VERSION ""

NS_ :

BS_:

BU_: HETC_M_MOB HETC_M_WST HETC_L_ARM HETC_L_TACT HETC_R_ARM HETC_R_TACT HMDH_201 HMDH_202 HMDH_203 HMDH_204 HMDH_205 HMDH_206 HMDH_207

BO_ 2163238143 CTRL_HETC_M_MOB_to_ALL: 7 HETC_M_MOB
 SG_ SubCode M : 0|8@1+ (1,0) [0|0] "" HETC_M_WST,HETC_L_ARM,HETC_L_TACT,HETC_R_ARM,HETC_R_TACT,HMDH_201,HMDH_202,HMDH_203,HMDH_204,HMDH_205,HMDH_206,HMDH_207
 SG_ Rtc_Year2000 m9 : 8|8@1+ (1,0) [0|0] "" HETC_M_WST,HETC_L_ARM,HETC_L_TACT,HETC_R_ARM,HETC_R_TACT,HMDH_201,HMDH_202,HMDH_203,HMDH_204,HMDH_205,HMDH_206,HMDH_207
 SG_ Rtc_Month m9 : 16|8@1+ (1,0) [0|0] "" HETC_M_WST,HETC_L_ARM,HETC_L_TACT,HETC_R_ARM,HETC_R_TACT,HMDH_201,HMDH_202,HMDH_203,HMDH_204,HMDH_205,HMDH_206,HMDH_207
 SG_ Rtc_Day m9 : 24|8@1+ (1,0) [0|0] "" HETC_M_WST,HETC_L_ARM,HETC_L_TACT,HETC_R_ARM,HETC_R_TACT,HMDH_201,HMDH_202,HMDH_203,HMDH_204,HMDH_205,HMDH_206,HMDH_207
 SG_ Rtc_Hour m9 : 32|8@1+ (1,0) [0|0] "" HETC_M_WST,HETC_L_ARM,HETC_L_TACT,HETC_R_ARM,HETC_R_TACT,HMDH_201,HMDH_202,HMDH_203,HMDH_204,HMDH_205,HMDH_206,HMDH_207
 SG_ Rtc_Min m9 : 40|8@1+ (1,0) [0|0] "" HETC_M_WST,HETC_L_ARM,HETC_L_TACT,HETC_R_ARM,HETC_R_TACT,HMDH_201,HMDH_202,HMDH_203,HMDH_204,HMDH_205,HMDH_206,HMDH_207
 SG_ Rtc_Sec m9 : 48|8@1+ (1,0) [0|0] "" HETC_M_WST,HETC_L_ARM,HETC_L_TACT,HETC_R_ARM,HETC_R_TACT,HMDH_201,HMDH_202,HMDH_203,HMDH_204,HMDH_205,HMDH_206,HMDH_207

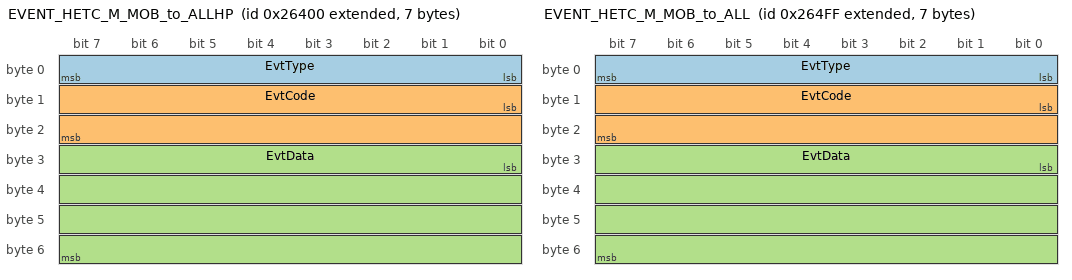
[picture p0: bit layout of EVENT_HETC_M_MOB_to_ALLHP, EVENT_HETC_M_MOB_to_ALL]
BO_ 2147640320 EVENT_HETC_M_MOB_to_ALLHP: 7 HETC_M_MOB
 SG_ EvtType : 0|8@1+ (1,0) [0|0] "" HETC_M_WST,HETC_L_ARM,HETC_L_TACT,HETC_R_ARM,HETC_R_TACT,HMDH_201,HMDH_202,HMDH_203,HMDH_204,HMDH_205,HMDH_206,HMDH_207
 SG_ EvtCode : 8|16@1+ (1,0) [0|0] "" HETC_M_WST,HETC_L_ARM,HETC_L_TACT,HETC_R_ARM,HETC_R_TACT,HMDH_201,HMDH_202,HMDH_203,HMDH_204,HMDH_205,HMDH_206,HMDH_207
 SG_ EvtData : 24|32@1+ (1,0) [0|0] "" HETC_M_WST,HETC_L_ARM,HETC_L_TACT,HETC_R_ARM,HETC_R_TACT,HMDH_201,HMDH_202,HMDH_203,HMDH_204,HMDH_205,HMDH_206,HMDH_207

BO_ 2147640575 EVENT_HETC_M_MOB_to_ALL: 7 HETC_M_MOB
 SG_ EvtType : 0|8@1+ (1,0) [0|0] "" HETC_M_WST,HETC_L_ARM,HETC_L_TACT,HETC_R_ARM,HETC_R_TACT,HMDH_201,HMDH_202,HMDH_203,HMDH_204,HMDH_205,HMDH_206,HMDH_207
 SG_ EvtCode : 8|16@1+ (1,0) [0|0] "" HETC_M_WST,HETC_L_ARM,HETC_L_TACT,HETC_R_ARM,HETC_R_TACT,HMDH_201,HMDH_202,HMDH_203,HMDH_204,HMDH_205,HMDH_206,HMDH_207
 SG_ EvtData : 24|32@1+ (1,0) [0|0] "" HETC_M_WST,HETC_L_ARM,HETC_L_TACT,HETC_R_ARM,HETC_R_TACT,HMDH_201,HMDH_202,HMDH_203,HMDH_204,HMDH_205,HMDH_206,HMDH_207

BO_ 2163240703 CTRL_HETC_M_WST_to_ALL: 7 HETC_M_WST
 SG_ SubCode M : 0|8@1+ (1,0) [0|0] "" HETC_M_MOB,HETC_L_ARM,HETC_L_TACT,HETC_R_ARM,HETC_R_TACT,HMDH_201,HMDH_202,HMDH_203,HMDH_204,HMDH_205,HMDH_206,HMDH_207
 SG_ Rtc_Year2000 m9 : 8|8@1+ (1,0) [0|0] "" HETC_M_MOB,HETC_L_ARM,HETC_L_TACT,HETC_R_ARM,HETC_R_TACT,HMDH_201,HMDH_202,HMDH_203,HMDH_204,HMDH_205,HMDH_206,HMDH_207
 SG_ Rtc_Month m9 : 16|8@1+ (1,0) [0|0] "" HETC_M_MOB,HETC_L_ARM,HETC_L_TACT,HETC_R_ARM,HETC_R_TACT,HMDH_201,HMDH_202,HMDH_203,HMDH_204,HMDH_205,HMDH_206,HMDH_207
 SG_ Rtc_Day m9 : 24|8@1+ (1,0) [0|0] "" HETC_M_MOB,HETC_L_ARM,HETC_L_TACT,HETC_R_ARM,HETC_R_TACT,HMDH_201,HMDH_202,HMDH_203,HMDH_204,HMDH_205,HMDH_206,HMDH_207
 SG_ Rtc_Hour m9 : 32|8@1+ (1,0) [0|0] "" HETC_M_MOB,HETC_L_ARM,HETC_L_TACT,HETC_R_ARM,HETC_R_TACT,HMDH_201,HMDH_202,HMDH_203,HMDH_204,HMDH_205,HMDH_206,HMDH_207
 SG_ Rtc_Min m9 : 40|8@1+ (1,0) [0|0] "" HETC_M_MOB,HETC_L_ARM,HETC_L_TACT,HETC_R_ARM,HETC_R_TACT,HMDH_201,HMDH_202,HMDH_203,HMDH_204,HMDH_205,HMDH_206,HMDH_207
 SG_ Rtc_Sec m9 : 48|8@1+ (1,0) [0|0] "" HETC_M_MOB,HETC_L_ARM,HETC_L_TACT,HETC_R_ARM,HETC_R_TACT,HMDH_201,HMDH_202,HMDH_203,HMDH_204,HMDH_205,HMDH_206,HMDH_207

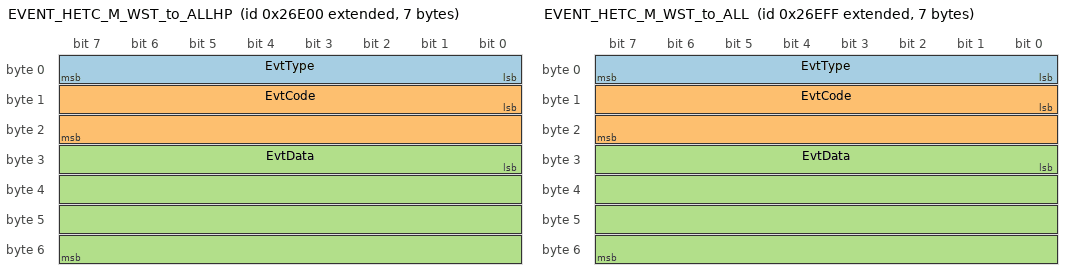
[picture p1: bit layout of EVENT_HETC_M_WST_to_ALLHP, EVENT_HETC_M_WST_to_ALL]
BO_ 2147642880 EVENT_HETC_M_WST_to_ALLHP: 7 HETC_M_WST
 SG_ EvtType : 0|8@1+ (1,0) [0|0] "" HETC_M_MOB,HETC_L_ARM,HETC_L_TACT,HETC_R_ARM,HETC_R_TACT,HMDH_201,HMDH_202,HMDH_203,HMDH_204,HMDH_205,HMDH_206,HMDH_207
 SG_ EvtCode : 8|16@1+ (1,0) [0|0] "" HETC_M_MOB,HETC_L_ARM,HETC_L_TACT,HETC_R_ARM,HETC_R_TACT,HMDH_201,HMDH_202,HMDH_203,HMDH_204,HMDH_205,HMDH_206,HMDH_207
 SG_ EvtData : 24|32@1+ (1,0) [0|0] "" HETC_M_MOB,HETC_L_ARM,HETC_L_TACT,HETC_R_ARM,HETC_R_TACT,HMDH_201,HMDH_202,HMDH_203,HMDH_204,HMDH_205,HMDH_206,HMDH_207

BO_ 2147643135 EVENT_HETC_M_WST_to_ALL: 7 HETC_M_WST
 SG_ EvtType : 0|8@1+ (1,0) [0|0] "" HETC_M_MOB,HETC_L_ARM,HETC_L_TACT,HETC_R_ARM,HETC_R_TACT,HMDH_201,HMDH_202,HMDH_203,HMDH_204,HMDH_205,HMDH_206,HMDH_207
 SG_ EvtCode : 8|16@1+ (1,0) [0|0] "" HETC_M_MOB,HETC_L_ARM,HETC_L_TACT,HETC_R_ARM,HETC_R_TACT,HMDH_201,HMDH_202,HMDH_203,HMDH_204,HMDH_205,HMDH_206,HMDH_207
 SG_ EvtData : 24|32@1+ (1,0) [0|0] "" HETC_M_MOB,HETC_L_ARM,HETC_L_TACT,HETC_R_ARM,HETC_R_TACT,HMDH_201,HMDH_202,HMDH_203,HMDH_204,HMDH_205,HMDH_206,HMDH_207

BO_ 2163243263 CTRL_HETC_L_ARM_to_ALL: 7 HETC_L_ARM
 SG_ SubCode M : 0|8@1+ (1,0) [0|0] "" HETC_M_MOB,HETC_M_WST,HETC_L_TACT,HETC_R_ARM,HETC_R_TACT,HMDH_201,HMDH_202,HMDH_203,HMDH_204,HMDH_205,HMDH_206,HMDH_207
 SG_ Rtc_Year2000 m9 : 8|8@1+ (1,0) [0|0] "" HETC_M_MOB,HETC_M_WST,HETC_L_TACT,HETC_R_ARM,HETC_R_TACT,HMDH_201,HMDH_202,HMDH_203,HMDH_204,HMDH_205,HMDH_206,HMDH_207
 SG_ Rtc_Month m9 : 16|8@1+ (1,0) [0|0] "" HETC_M_MOB,HETC_M_WST,HETC_L_TACT,HETC_R_ARM,HETC_R_TACT,HMDH_201,HMDH_202,HMDH_203,HMDH_204,HMDH_205,HMDH_206,HMDH_207
 SG_ Rtc_Day m9 : 24|8@1+ (1,0) [0|0] "" HETC_M_MOB,HETC_M_WST,HETC_L_TACT,HETC_R_ARM,HETC_R_TACT,HMDH_201,HMDH_202,HMDH_203,HMDH_204,HMDH_205,HMDH_206,HMDH_207
 SG_ Rtc_Hour m9 : 32|8@1+ (1,0) [0|0] "" HETC_M_MOB,HETC_M_WST,HETC_L_TACT,HETC_R_ARM,HETC_R_TACT,HMDH_201,HMDH_202,HMDH_203,HMDH_204,HMDH_205,HMDH_206,HMDH_207
 SG_ Rtc_Min m9 : 40|8@1+ (1,0) [0|0] "" HETC_M_MOB,HETC_M_WST,HETC_L_TACT,HETC_R_ARM,HETC_R_TACT,HMDH_201,HMDH_202,HMDH_203,HMDH_204,HMDH_205,HMDH_206,HMDH_207
 SG_ Rtc_Sec m9 : 48|8@1+ (1,0) [0|0] "" HETC_M_MOB,HETC_M_WST,HETC_L_TACT,HETC_R_ARM,HETC_R_TACT,HMDH_201,HMDH_202,HMDH_203,HMDH_204,HMDH_205,HMDH_206,HMDH_207

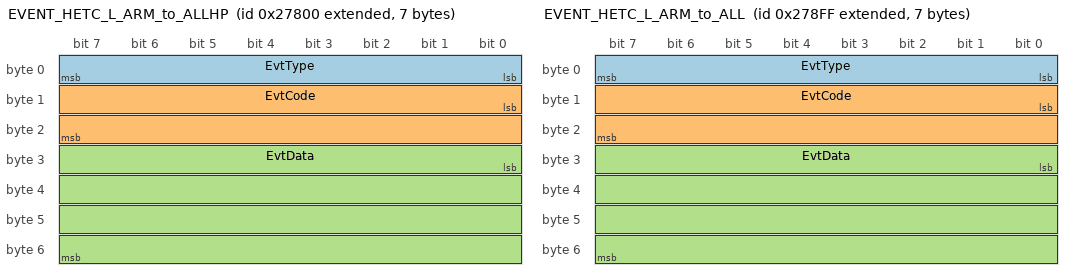
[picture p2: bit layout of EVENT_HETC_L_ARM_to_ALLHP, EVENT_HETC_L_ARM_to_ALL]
BO_ 2147645440 EVENT_HETC_L_ARM_to_ALLHP: 7 HETC_L_ARM
 SG_ EvtType : 0|8@1+ (1,0) [0|0] "" HETC_M_MOB,HETC_M_WST,HETC_L_TACT,HETC_R_ARM,HETC_R_TACT,HMDH_201,HMDH_202,HMDH_203,HMDH_204,HMDH_205,HMDH_206,HMDH_207
 SG_ EvtCode : 8|16@1+ (1,0) [0|0] "" HETC_M_MOB,HETC_M_WST,HETC_L_TACT,HETC_R_ARM,HETC_R_TACT,HMDH_201,HMDH_202,HMDH_203,HMDH_204,HMDH_205,HMDH_206,HMDH_207
 SG_ EvtData : 24|32@1+ (1,0) [0|0] "" HETC_M_MOB,HETC_M_WST,HETC_L_TACT,HETC_R_ARM,HETC_R_TACT,HMDH_201,HMDH_202,HMDH_203,HMDH_204,HMDH_205,HMDH_206,HMDH_207

BO_ 2147645695 EVENT_HETC_L_ARM_to_ALL: 7 HETC_L_ARM
 SG_ EvtType : 0|8@1+ (1,0) [0|0] "" HETC_M_MOB,HETC_M_WST,HETC_L_TACT,HETC_R_ARM,HETC_R_TACT,HMDH_201,HMDH_202,HMDH_203,HMDH_204,HMDH_205,HMDH_206,HMDH_207
 SG_ EvtCode : 8|16@1+ (1,0) [0|0] "" HETC_M_MOB,HETC_M_WST,HETC_L_TACT,HETC_R_ARM,HETC_R_TACT,HMDH_201,HMDH_202,HMDH_203,HMDH_204,HMDH_205,HMDH_206,HMDH_207
 SG_ EvtData : 24|32@1+ (1,0) [0|0] "" HETC_M_MOB,HETC_M_WST,HETC_L_TACT,HETC_R_ARM,HETC_R_TACT,HMDH_201,HMDH_202,HMDH_203,HMDH_204,HMDH_205,HMDH_206,HMDH_207

BO_ 2163245823 CTRL_HETC_L_TACT_to_ALL: 7 HETC_L_TACT
 SG_ SubCode M : 0|8@1+ (1,0) [0|0] "" HETC_M_MOB,HETC_M_WST,HETC_L_ARM,HETC_R_ARM,HETC_R_TACT,HMDH_201,HMDH_202,HMDH_203,HMDH_204,HMDH_205,HMDH_206,HMDH_207
 SG_ Rtc_Year2000 m9 : 8|8@1+ (1,0) [0|0] "" HETC_M_MOB,HETC_M_WST,HETC_L_ARM,HETC_R_ARM,HETC_R_TACT,HMDH_201,HMDH_202,HMDH_203,HMDH_204,HMDH_205,HMDH_206,HMDH_207
 SG_ Rtc_Month m9 : 16|8@1+ (1,0) [0|0] "" HETC_M_MOB,HETC_M_WST,HETC_L_ARM,HETC_R_ARM,HETC_R_TACT,HMDH_201,HMDH_202,HMDH_203,HMDH_204,HMDH_205,HMDH_206,HMDH_207
 SG_ Rtc_Day m9 : 24|8@1+ (1,0) [0|0] "" HETC_M_MOB,HETC_M_WST,HETC_L_ARM,HETC_R_ARM,HETC_R_TACT,HMDH_201,HMDH_202,HMDH_203,HMDH_204,HMDH_205,HMDH_206,HMDH_207
 SG_ Rtc_Hour m9 : 32|8@1+ (1,0) [0|0] "" HETC_M_MOB,HETC_M_WST,HETC_L_ARM,HETC_R_ARM,HETC_R_TACT,HMDH_201,HMDH_202,HMDH_203,HMDH_204,HMDH_205,HMDH_206,HMDH_207
 SG_ Rtc_Min m9 : 40|8@1+ (1,0) [0|0] "" HETC_M_MOB,HETC_M_WST,HETC_L_ARM,HETC_R_ARM,HETC_R_TACT,HMDH_201,HMDH_202,HMDH_203,HMDH_204,HMDH_205,HMDH_206,HMDH_207
 SG_ Rtc_Sec m9 : 48|8@1+ (1,0) [0|0] "" HETC_M_MOB,HETC_M_WST,HETC_L_ARM,HETC_R_ARM,HETC_R_TACT,HMDH_201,HMDH_202,HMDH_203,HMDH_204,HMDH_205,HMDH_206,HMDH_207

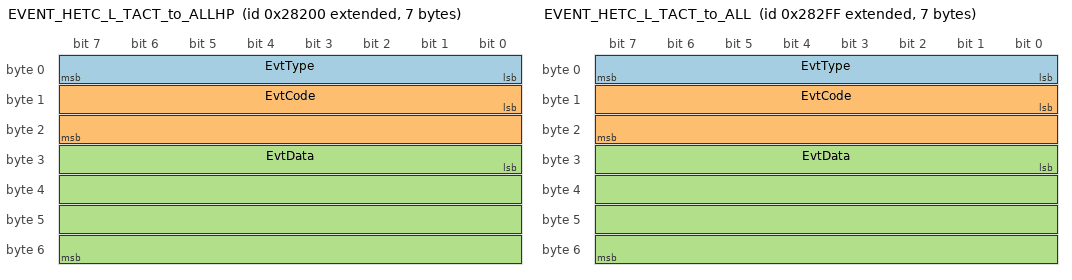
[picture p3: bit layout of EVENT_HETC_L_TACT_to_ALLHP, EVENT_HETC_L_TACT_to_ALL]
BO_ 2147648000 EVENT_HETC_L_TACT_to_ALLHP: 7 HETC_L_TACT
 SG_ EvtType : 0|8@1+ (1,0) [0|0] "" HETC_M_MOB,HETC_M_WST,HETC_L_ARM,HETC_R_ARM,HETC_R_TACT,HMDH_201,HMDH_202,HMDH_203,HMDH_204,HMDH_205,HMDH_206,HMDH_207
 SG_ EvtCode : 8|16@1+ (1,0) [0|0] "" HETC_M_MOB,HETC_M_WST,HETC_L_ARM,HETC_R_ARM,HETC_R_TACT,HMDH_201,HMDH_202,HMDH_203,HMDH_204,HMDH_205,HMDH_206,HMDH_207
 SG_ EvtData : 24|32@1+ (1,0) [0|0] "" HETC_M_MOB,HETC_M_WST,HETC_L_ARM,HETC_R_ARM,HETC_R_TACT,HMDH_201,HMDH_202,HMDH_203,HMDH_204,HMDH_205,HMDH_206,HMDH_207

BO_ 2147648255 EVENT_HETC_L_TACT_to_ALL: 7 HETC_L_TACT
 SG_ EvtType : 0|8@1+ (1,0) [0|0] "" HETC_M_MOB,HETC_M_WST,HETC_L_ARM,HETC_R_ARM,HETC_R_TACT,HMDH_201,HMDH_202,HMDH_203,HMDH_204,HMDH_205,HMDH_206,HMDH_207
 SG_ EvtCode : 8|16@1+ (1,0) [0|0] "" HETC_M_MOB,HETC_M_WST,HETC_L_ARM,HETC_R_ARM,HETC_R_TACT,HMDH_201,HMDH_202,HMDH_203,HMDH_204,HMDH_205,HMDH_206,HMDH_207
 SG_ EvtData : 24|32@1+ (1,0) [0|0] "" HETC_M_MOB,HETC_M_WST,HETC_L_ARM,HETC_R_ARM,HETC_R_TACT,HMDH_201,HMDH_202,HMDH_203,HMDH_204,HMDH_205,HMDH_206,HMDH_207

BO_ 2163248383 CTRL_HETC_R_ARM_to_ALL: 7 HETC_R_ARM
 SG_ SubCode M : 0|8@1+ (1,0) [0|0] "" HETC_M_MOB,HETC_M_WST,HETC_L_ARM,HETC_L_TACT,HETC_R_TACT,HMDH_201,HMDH_202,HMDH_203,HMDH_204,HMDH_205,HMDH_206,HMDH_207
 SG_ Rtc_Year2000 m9 : 8|8@1+ (1,0) [0|0] "" HETC_M_MOB,HETC_M_WST,HETC_L_ARM,HETC_L_TACT,HETC_R_TACT,HMDH_201,HMDH_202,HMDH_203,HMDH_204,HMDH_205,HMDH_206,HMDH_207
 SG_ Rtc_Month m9 : 16|8@1+ (1,0) [0|0] "" HETC_M_MOB,HETC_M_WST,HETC_L_ARM,HETC_L_TACT,HETC_R_TACT,HMDH_201,HMDH_202,HMDH_203,HMDH_204,HMDH_205,HMDH_206,HMDH_207
 SG_ Rtc_Day m9 : 24|8@1+ (1,0) [0|0] "" HETC_M_MOB,HETC_M_WST,HETC_L_ARM,HETC_L_TACT,HETC_R_TACT,HMDH_201,HMDH_202,HMDH_203,HMDH_204,HMDH_205,HMDH_206,HMDH_207
 SG_ Rtc_Hour m9 : 32|8@1+ (1,0) [0|0] "" HETC_M_MOB,HETC_M_WST,HETC_L_ARM,HETC_L_TACT,HETC_R_TACT,HMDH_201,HMDH_202,HMDH_203,HMDH_204,HMDH_205,HMDH_206,HMDH_207
 SG_ Rtc_Min m9 : 40|8@1+ (1,0) [0|0] "" HETC_M_MOB,HETC_M_WST,HETC_L_ARM,HETC_L_TACT,HETC_R_TACT,HMDH_201,HMDH_202,HMDH_203,HMDH_204,HMDH_205,HMDH_206,HMDH_207
 SG_ Rtc_Sec m9 : 48|8@1+ (1,0) [0|0] "" HETC_M_MOB,HETC_M_WST,HETC_L_ARM,HETC_L_TACT,HETC_R_TACT,HMDH_201,HMDH_202,HMDH_203,HMDH_204,HMDH_205,HMDH_206,HMDH_207

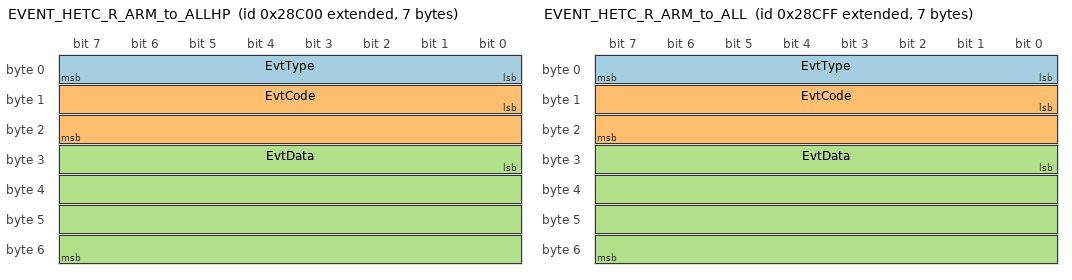
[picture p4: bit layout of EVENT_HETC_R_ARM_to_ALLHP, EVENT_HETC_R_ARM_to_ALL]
BO_ 2147650560 EVENT_HETC_R_ARM_to_ALLHP: 7 HETC_R_ARM
 SG_ EvtType : 0|8@1+ (1,0) [0|0] "" HETC_M_MOB,HETC_M_WST,HETC_L_ARM,HETC_L_TACT,HETC_R_TACT,HMDH_201,HMDH_202,HMDH_203,HMDH_204,HMDH_205,HMDH_206,HMDH_207
 SG_ EvtCode : 8|16@1+ (1,0) [0|0] "" HETC_M_MOB,HETC_M_WST,HETC_L_ARM,HETC_L_TACT,HETC_R_TACT,HMDH_201,HMDH_202,HMDH_203,HMDH_204,HMDH_205,HMDH_206,HMDH_207
 SG_ EvtData : 24|32@1+ (1,0) [0|0] "" HETC_M_MOB,HETC_M_WST,HETC_L_ARM,HETC_L_TACT,HETC_R_TACT,HMDH_201,HMDH_202,HMDH_203,HMDH_204,HMDH_205,HMDH_206,HMDH_207

BO_ 2147650815 EVENT_HETC_R_ARM_to_ALL: 7 HETC_R_ARM
 SG_ EvtType : 0|8@1+ (1,0) [0|0] "" HETC_M_MOB,HETC_M_WST,HETC_L_ARM,HETC_L_TACT,HETC_R_TACT,HMDH_201,HMDH_202,HMDH_203,HMDH_204,HMDH_205,HMDH_206,HMDH_207
 SG_ EvtCode : 8|16@1+ (1,0) [0|0] "" HETC_M_MOB,HETC_M_WST,HETC_L_ARM,HETC_L_TACT,HETC_R_TACT,HMDH_201,HMDH_202,HMDH_203,HMDH_204,HMDH_205,HMDH_206,HMDH_207
 SG_ EvtData : 24|32@1+ (1,0) [0|0] "" HETC_M_MOB,HETC_M_WST,HETC_L_ARM,HETC_L_TACT,HETC_R_TACT,HMDH_201,HMDH_202,HMDH_203,HMDH_204,HMDH_205,HMDH_206,HMDH_207

BO_ 2163250943 CTRL_HETC_R_TACT_to_ALL: 7 HETC_R_TACT
 SG_ SubCode M : 0|8@1+ (1,0) [0|0] "" HETC_M_MOB,HETC_M_WST,HETC_L_ARM,HETC_L_TACT,HETC_R_ARM,HMDH_201,HMDH_202,HMDH_203,HMDH_204,HMDH_205,HMDH_206,HMDH_207
 SG_ Rtc_Year2000 m9 : 8|8@1+ (1,0) [0|0] "" HETC_M_MOB,HETC_M_WST,HETC_L_ARM,HETC_L_TACT,HETC_R_ARM,HMDH_201,HMDH_202,HMDH_203,HMDH_204,HMDH_205,HMDH_206,HMDH_207
 SG_ Rtc_Month m9 : 16|8@1+ (1,0) [0|0] "" HETC_M_MOB,HETC_M_WST,HETC_L_ARM,HETC_L_TACT,HETC_R_ARM,HMDH_201,HMDH_202,HMDH_203,HMDH_204,HMDH_205,HMDH_206,HMDH_207
 SG_ Rtc_Day m9 : 24|8@1+ (1,0) [0|0] "" HETC_M_MOB,HETC_M_WST,HETC_L_ARM,HETC_L_TACT,HETC_R_ARM,HMDH_201,HMDH_202,HMDH_203,HMDH_204,HMDH_205,HMDH_206,HMDH_207
 SG_ Rtc_Hour m9 : 32|8@1+ (1,0) [0|0] "" HETC_M_MOB,HETC_M_WST,HETC_L_ARM,HETC_L_TACT,HETC_R_ARM,HMDH_201,HMDH_202,HMDH_203,HMDH_204,HMDH_205,HMDH_206,HMDH_207
 SG_ Rtc_Min m9 : 40|8@1+ (1,0) [0|0] "" HETC_M_MOB,HETC_M_WST,HETC_L_ARM,HETC_L_TACT,HETC_R_ARM,HMDH_201,HMDH_202,HMDH_203,HMDH_204,HMDH_205,HMDH_206,HMDH_207
 SG_ Rtc_Sec m9 : 48|8@1+ (1,0) [0|0] "" HETC_M_MOB,HETC_M_WST,HETC_L_ARM,HETC_L_TACT,HETC_R_ARM,HMDH_201,HMDH_202,HMDH_203,HMDH_204,HMDH_205,HMDH_206,HMDH_207

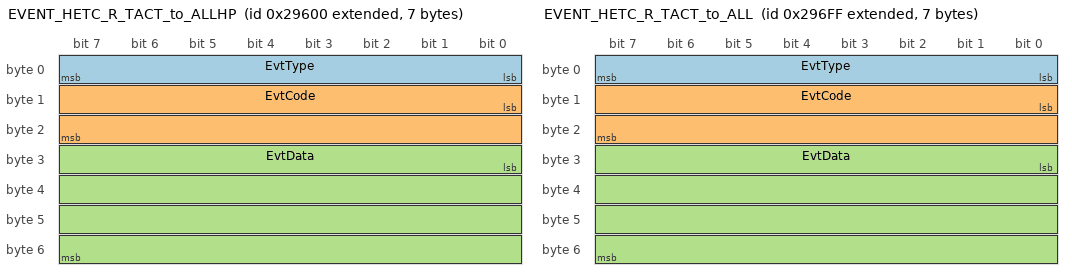
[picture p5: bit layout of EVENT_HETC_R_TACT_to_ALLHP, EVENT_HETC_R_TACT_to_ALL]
BO_ 2147653120 EVENT_HETC_R_TACT_to_ALLHP: 7 HETC_R_TACT
 SG_ EvtType : 0|8@1+ (1,0) [0|0] "" HETC_M_MOB,HETC_M_WST,HETC_L_ARM,HETC_L_TACT,HETC_R_ARM,HMDH_201,HMDH_202,HMDH_203,HMDH_204,HMDH_205,HMDH_206,HMDH_207
 SG_ EvtCode : 8|16@1+ (1,0) [0|0] "" HETC_M_MOB,HETC_M_WST,HETC_L_ARM,HETC_L_TACT,HETC_R_ARM,HMDH_201,HMDH_202,HMDH_203,HMDH_204,HMDH_205,HMDH_206,HMDH_207
 SG_ EvtData : 24|32@1+ (1,0) [0|0] "" HETC_M_MOB,HETC_M_WST,HETC_L_ARM,HETC_L_TACT,HETC_R_ARM,HMDH_201,HMDH_202,HMDH_203,HMDH_204,HMDH_205,HMDH_206,HMDH_207

BO_ 2147653375 EVENT_HETC_R_TACT_to_ALL: 7 HETC_R_TACT
 SG_ EvtType : 0|8@1+ (1,0) [0|0] "" HETC_M_MOB,HETC_M_WST,HETC_L_ARM,HETC_L_TACT,HETC_R_ARM,HMDH_201,HMDH_202,HMDH_203,HMDH_204,HMDH_205,HMDH_206,HMDH_207
 SG_ EvtCode : 8|16@1+ (1,0) [0|0] "" HETC_M_MOB,HETC_M_WST,HETC_L_ARM,HETC_L_TACT,HETC_R_ARM,HMDH_201,HMDH_202,HMDH_203,HMDH_204,HMDH_205,HMDH_206,HMDH_207
 SG_ EvtData : 24|32@1+ (1,0) [0|0] "" HETC_M_MOB,HETC_M_WST,HETC_L_ARM,HETC_L_TACT,HETC_R_ARM,HMDH_201,HMDH_202,HMDH_203,HMDH_204,HMDH_205,HMDH_206,HMDH_207

BO_ 2163263999 CTRL_HMDH_201_to_ALL: 7 HMDH_201
 SG_ SubCode M : 0|8@1+ (1,0) [0|0] "" HETC_M_MOB,HETC_M_WST,HETC_L_ARM,HETC_L_TACT,HETC_R_ARM,HETC_R_TACT,HMDH_202,HMDH_203,HMDH_204,HMDH_205,HMDH_206,HMDH_207
 SG_ Rtc_Year2000 m9 : 8|8@1+ (1,0) [0|0] "" HETC_M_MOB,HETC_M_WST,HETC_L_ARM,HETC_L_TACT,HETC_R_ARM,HETC_R_TACT,HMDH_202,HMDH_203,HMDH_204,HMDH_205,HMDH_206,HMDH_207
 SG_ Rtc_Month m9 : 16|8@1+ (1,0) [0|0] "" HETC_M_MOB,HETC_M_WST,HETC_L_ARM,HETC_L_TACT,HETC_R_ARM,HETC_R_TACT,HMDH_202,HMDH_203,HMDH_204,HMDH_205,HMDH_206,HMDH_207
 SG_ Rtc_Day m9 : 24|8@1+ (1,0) [0|0] "" HETC_M_MOB,HETC_M_WST,HETC_L_ARM,HETC_L_TACT,HETC_R_ARM,HETC_R_TACT,HMDH_202,HMDH_203,HMDH_204,HMDH_205,HMDH_206,HMDH_207
 SG_ Rtc_Hour m9 : 32|8@1+ (1,0) [0|0] "" HETC_M_MOB,HETC_M_WST,HETC_L_ARM,HETC_L_TACT,HETC_R_ARM,HETC_R_TACT,HMDH_202,HMDH_203,HMDH_204,HMDH_205,HMDH_206,HMDH_207
 SG_ Rtc_Min m9 : 40|8@1+ (1,0) [0|0] "" HETC_M_MOB,HETC_M_WST,HETC_L_ARM,HETC_L_TACT,HETC_R_ARM,HETC_R_TACT,HMDH_202,HMDH_203,HMDH_204,HMDH_205,HMDH_206,HMDH_207
 SG_ Rtc_Sec m9 : 48|8@1+ (1,0) [0|0] "" HETC_M_MOB,HETC_M_WST,HETC_L_ARM,HETC_L_TACT,HETC_R_ARM,HETC_R_TACT,HMDH_202,HMDH_203,HMDH_204,HMDH_205,HMDH_206,HMDH_207

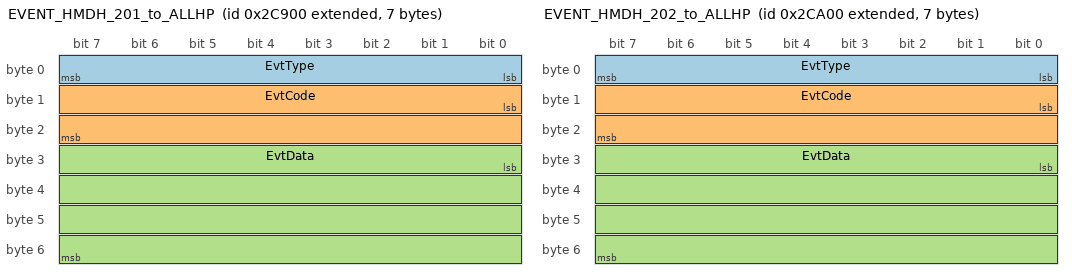
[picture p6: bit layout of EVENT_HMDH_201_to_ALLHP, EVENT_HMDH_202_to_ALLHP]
BO_ 2147666176 EVENT_HMDH_201_to_ALLHP: 7 HMDH_201
 SG_ EvtType : 0|8@1+ (1,0) [0|0] "" HETC_M_MOB,HETC_M_WST,HETC_L_ARM,HETC_L_TACT,HETC_R_ARM,HETC_R_TACT,HMDH_202,HMDH_203,HMDH_204,HMDH_205,HMDH_206,HMDH_207
 SG_ EvtCode : 8|16@1+ (1,0) [0|0] "" HETC_M_MOB,HETC_M_WST,HETC_L_ARM,HETC_L_TACT,HETC_R_ARM,HETC_R_TACT,HMDH_202,HMDH_203,HMDH_204,HMDH_205,HMDH_206,HMDH_207
 SG_ EvtData : 24|32@1+ (1,0) [0|0] "" HETC_M_MOB,HETC_M_WST,HETC_L_ARM,HETC_L_TACT,HETC_R_ARM,HETC_R_TACT,HMDH_202,HMDH_203,HMDH_204,HMDH_205,HMDH_206,HMDH_207

BO_ 2163264255 CTRL_HMDH_202_to_ALL: 7 HMDH_202
 SG_ SubCode M : 0|8@1+ (1,0) [0|0] "" HETC_M_MOB,HETC_M_WST,HETC_L_ARM,HETC_L_TACT,HETC_R_ARM,HETC_R_TACT,HMDH_201,HMDH_203,HMDH_204,HMDH_205,HMDH_206,HMDH_207
 SG_ Rtc_Year2000 m9 : 8|8@1+ (1,0) [0|0] "" HETC_M_MOB,HETC_M_WST,HETC_L_ARM,HETC_L_TACT,HETC_R_ARM,HETC_R_TACT,HMDH_201,HMDH_203,HMDH_204,HMDH_205,HMDH_206,HMDH_207
 SG_ Rtc_Month m9 : 16|8@1+ (1,0) [0|0] "" HETC_M_MOB,HETC_M_WST,HETC_L_ARM,HETC_L_TACT,HETC_R_ARM,HETC_R_TACT,HMDH_201,HMDH_203,HMDH_204,HMDH_205,HMDH_206,HMDH_207
 SG_ Rtc_Day m9 : 24|8@1+ (1,0) [0|0] "" HETC_M_MOB,HETC_M_WST,HETC_L_ARM,HETC_L_TACT,HETC_R_ARM,HETC_R_TACT,HMDH_201,HMDH_203,HMDH_204,HMDH_205,HMDH_206,HMDH_207
 SG_ Rtc_Hour m9 : 32|8@1+ (1,0) [0|0] "" HETC_M_MOB,HETC_M_WST,HETC_L_ARM,HETC_L_TACT,HETC_R_ARM,HETC_R_TACT,HMDH_201,HMDH_203,HMDH_204,HMDH_205,HMDH_206,HMDH_207
 SG_ Rtc_Min m9 : 40|8@1+ (1,0) [0|0] "" HETC_M_MOB,HETC_M_WST,HETC_L_ARM,HETC_L_TACT,HETC_R_ARM,HETC_R_TACT,HMDH_201,HMDH_203,HMDH_204,HMDH_205,HMDH_206,HMDH_207
 SG_ Rtc_Sec m9 : 48|8@1+ (1,0) [0|0] "" HETC_M_MOB,HETC_M_WST,HETC_L_ARM,HETC_L_TACT,HETC_R_ARM,HETC_R_TACT,HMDH_201,HMDH_203,HMDH_204,HMDH_205,HMDH_206,HMDH_207

BO_ 2147666432 EVENT_HMDH_202_to_ALLHP: 7 HMDH_202
 SG_ EvtType : 0|8@1+ (1,0) [0|0] "" HETC_M_MOB,HETC_M_WST,HETC_L_ARM,HETC_L_TACT,HETC_R_ARM,HETC_R_TACT,HMDH_201,HMDH_203,HMDH_204,HMDH_205,HMDH_206,HMDH_207
 SG_ EvtCode : 8|16@1+ (1,0) [0|0] "" HETC_M_MOB,HETC_M_WST,HETC_L_ARM,HETC_L_TACT,HETC_R_ARM,HETC_R_TACT,HMDH_201,HMDH_203,HMDH_204,HMDH_205,HMDH_206,HMDH_207
 SG_ EvtData : 24|32@1+ (1,0) [0|0] "" HETC_M_MOB,HETC_M_WST,HETC_L_ARM,HETC_L_TACT,HETC_R_ARM,HETC_R_TACT,HMDH_201,HMDH_203,HMDH_204,HMDH_205,HMDH_206,HMDH_207

BO_ 2163264511 CTRL_HMDH_203_to_ALL: 7 HMDH_203
 SG_ SubCode M : 0|8@1+ (1,0) [0|0] "" HETC_M_MOB,HETC_M_WST,HETC_L_ARM,HETC_L_TACT,HETC_R_ARM,HETC_R_TACT,HMDH_201,HMDH_202,HMDH_204,HMDH_205,HMDH_206,HMDH_207
 SG_ Rtc_Year2000 m9 : 8|8@1+ (1,0) [0|0] "" HETC_M_MOB,HETC_M_WST,HETC_L_ARM,HETC_L_TACT,HETC_R_ARM,HETC_R_TACT,HMDH_201,HMDH_202,HMDH_204,HMDH_205,HMDH_206,HMDH_207
 SG_ Rtc_Month m9 : 16|8@1+ (1,0) [0|0] "" HETC_M_MOB,HETC_M_WST,HETC_L_ARM,HETC_L_TACT,HETC_R_ARM,HETC_R_TACT,HMDH_201,HMDH_202,HMDH_204,HMDH_205,HMDH_206,HMDH_207
 SG_ Rtc_Day m9 : 24|8@1+ (1,0) [0|0] "" HETC_M_MOB,HETC_M_WST,HETC_L_ARM,HETC_L_TACT,HETC_R_ARM,HETC_R_TACT,HMDH_201,HMDH_202,HMDH_204,HMDH_205,HMDH_206,HMDH_207
 SG_ Rtc_Hour m9 : 32|8@1+ (1,0) [0|0] "" HETC_M_MOB,HETC_M_WST,HETC_L_ARM,HETC_L_TACT,HETC_R_ARM,HETC_R_TACT,HMDH_201,HMDH_202,HMDH_204,HMDH_205,HMDH_206,HMDH_207
 SG_ Rtc_Min m9 : 40|8@1+ (1,0) [0|0] "" HETC_M_MOB,HETC_M_WST,HETC_L_ARM,HETC_L_TACT,HETC_R_ARM,HETC_R_TACT,HMDH_201,HMDH_202,HMDH_204,HMDH_205,HMDH_206,HMDH_207
 SG_ Rtc_Sec m9 : 48|8@1+ (1,0) [0|0] "" HETC_M_MOB,HETC_M_WST,HETC_L_ARM,HETC_L_TACT,HETC_R_ARM,HETC_R_TACT,HMDH_201,HMDH_202,HMDH_204,HMDH_205,HMDH_206,HMDH_207

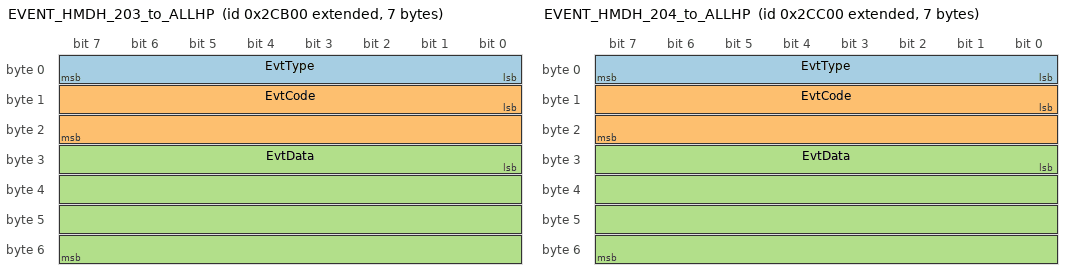
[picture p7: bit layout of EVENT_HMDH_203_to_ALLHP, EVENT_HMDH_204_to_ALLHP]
BO_ 2147666688 EVENT_HMDH_203_to_ALLHP: 7 HMDH_203
 SG_ EvtType : 0|8@1+ (1,0) [0|0] "" HETC_M_MOB,HETC_M_WST,HETC_L_ARM,HETC_L_TACT,HETC_R_ARM,HETC_R_TACT,HMDH_201,HMDH_202,HMDH_204,HMDH_205,HMDH_206,HMDH_207
 SG_ EvtCode : 8|16@1+ (1,0) [0|0] "" HETC_M_MOB,HETC_M_WST,HETC_L_ARM,HETC_L_TACT,HETC_R_ARM,HETC_R_TACT,HMDH_201,HMDH_202,HMDH_204,HMDH_205,HMDH_206,HMDH_207
 SG_ EvtData : 24|32@1+ (1,0) [0|0] "" HETC_M_MOB,HETC_M_WST,HETC_L_ARM,HETC_L_TACT,HETC_R_ARM,HETC_R_TACT,HMDH_201,HMDH_202,HMDH_204,HMDH_205,HMDH_206,HMDH_207

BO_ 2163264767 CTRL_HMDH_204_to_ALL: 7 HMDH_204
 SG_ SubCode M : 0|8@1+ (1,0) [0|0] "" HETC_M_MOB,HETC_M_WST,HETC_L_ARM,HETC_L_TACT,HETC_R_ARM,HETC_R_TACT,HMDH_201,HMDH_202,HMDH_203,HMDH_205,HMDH_206,HMDH_207
 SG_ Rtc_Year2000 m9 : 8|8@1+ (1,0) [0|0] "" HETC_M_MOB,HETC_M_WST,HETC_L_ARM,HETC_L_TACT,HETC_R_ARM,HETC_R_TACT,HMDH_201,HMDH_202,HMDH_203,HMDH_205,HMDH_206,HMDH_207
 SG_ Rtc_Month m9 : 16|8@1+ (1,0) [0|0] "" HETC_M_MOB,HETC_M_WST,HETC_L_ARM,HETC_L_TACT,HETC_R_ARM,HETC_R_TACT,HMDH_201,HMDH_202,HMDH_203,HMDH_205,HMDH_206,HMDH_207
 SG_ Rtc_Day m9 : 24|8@1+ (1,0) [0|0] "" HETC_M_MOB,HETC_M_WST,HETC_L_ARM,HETC_L_TACT,HETC_R_ARM,HETC_R_TACT,HMDH_201,HMDH_202,HMDH_203,HMDH_205,HMDH_206,HMDH_207
 SG_ Rtc_Hour m9 : 32|8@1+ (1,0) [0|0] "" HETC_M_MOB,HETC_M_WST,HETC_L_ARM,HETC_L_TACT,HETC_R_ARM,HETC_R_TACT,HMDH_201,HMDH_202,HMDH_203,HMDH_205,HMDH_206,HMDH_207
 SG_ Rtc_Min m9 : 40|8@1+ (1,0) [0|0] "" HETC_M_MOB,HETC_M_WST,HETC_L_ARM,HETC_L_TACT,HETC_R_ARM,HETC_R_TACT,HMDH_201,HMDH_202,HMDH_203,HMDH_205,HMDH_206,HMDH_207
 SG_ Rtc_Sec m9 : 48|8@1+ (1,0) [0|0] "" HETC_M_MOB,HETC_M_WST,HETC_L_ARM,HETC_L_TACT,HETC_R_ARM,HETC_R_TACT,HMDH_201,HMDH_202,HMDH_203,HMDH_205,HMDH_206,HMDH_207

BO_ 2147666944 EVENT_HMDH_204_to_ALLHP: 7 HMDH_204
 SG_ EvtType : 0|8@1+ (1,0) [0|0] "" HETC_M_MOB,HETC_M_WST,HETC_L_ARM,HETC_L_TACT,HETC_R_ARM,HETC_R_TACT,HMDH_201,HMDH_202,HMDH_203,HMDH_205,HMDH_206,HMDH_207
 SG_ EvtCode : 8|16@1+ (1,0) [0|0] "" HETC_M_MOB,HETC_M_WST,HETC_L_ARM,HETC_L_TACT,HETC_R_ARM,HETC_R_TACT,HMDH_201,HMDH_202,HMDH_203,HMDH_205,HMDH_206,HMDH_207
 SG_ EvtData : 24|32@1+ (1,0) [0|0] "" HETC_M_MOB,HETC_M_WST,HETC_L_ARM,HETC_L_TACT,HETC_R_ARM,HETC_R_TACT,HMDH_201,HMDH_202,HMDH_203,HMDH_205,HMDH_206,HMDH_207

BO_ 2163265023 CTRL_HMDH_205_to_ALL: 7 HMDH_205
 SG_ SubCode M : 0|8@1+ (1,0) [0|0] "" HETC_M_MOB,HETC_M_WST,HETC_L_ARM,HETC_L_TACT,HETC_R_ARM,HETC_R_TACT,HMDH_201,HMDH_202,HMDH_203,HMDH_204,HMDH_206,HMDH_207
 SG_ Rtc_Year2000 m9 : 8|8@1+ (1,0) [0|0] "" HETC_M_MOB,HETC_M_WST,HETC_L_ARM,HETC_L_TACT,HETC_R_ARM,HETC_R_TACT,HMDH_201,HMDH_202,HMDH_203,HMDH_204,HMDH_206,HMDH_207
 SG_ Rtc_Month m9 : 16|8@1+ (1,0) [0|0] "" HETC_M_MOB,HETC_M_WST,HETC_L_ARM,HETC_L_TACT,HETC_R_ARM,HETC_R_TACT,HMDH_201,HMDH_202,HMDH_203,HMDH_204,HMDH_206,HMDH_207
 SG_ Rtc_Day m9 : 24|8@1+ (1,0) [0|0] "" HETC_M_MOB,HETC_M_WST,HETC_L_ARM,HETC_L_TACT,HETC_R_ARM,HETC_R_TACT,HMDH_201,HMDH_202,HMDH_203,HMDH_204,HMDH_206,HMDH_207
 SG_ Rtc_Hour m9 : 32|8@1+ (1,0) [0|0] "" HETC_M_MOB,HETC_M_WST,HETC_L_ARM,HETC_L_TACT,HETC_R_ARM,HETC_R_TACT,HMDH_201,HMDH_202,HMDH_203,HMDH_204,HMDH_206,HMDH_207
 SG_ Rtc_Min m9 : 40|8@1+ (1,0) [0|0] "" HETC_M_MOB,HETC_M_WST,HETC_L_ARM,HETC_L_TACT,HETC_R_ARM,HETC_R_TACT,HMDH_201,HMDH_202,HMDH_203,HMDH_204,HMDH_206,HMDH_207
 SG_ Rtc_Sec m9 : 48|8@1+ (1,0) [0|0] "" HETC_M_MOB,HETC_M_WST,HETC_L_ARM,HETC_L_TACT,HETC_R_ARM,HETC_R_TACT,HMDH_201,HMDH_202,HMDH_203,HMDH_204,HMDH_206,HMDH_207

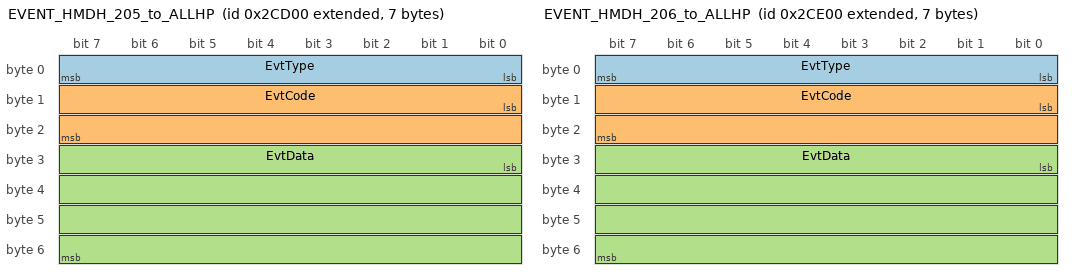
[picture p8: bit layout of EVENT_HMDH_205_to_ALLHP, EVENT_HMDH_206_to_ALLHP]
BO_ 2147667200 EVENT_HMDH_205_to_ALLHP: 7 HMDH_205
 SG_ EvtType : 0|8@1+ (1,0) [0|0] "" HETC_M_MOB,HETC_M_WST,HETC_L_ARM,HETC_L_TACT,HETC_R_ARM,HETC_R_TACT,HMDH_201,HMDH_202,HMDH_203,HMDH_204,HMDH_206,HMDH_207
 SG_ EvtCode : 8|16@1+ (1,0) [0|0] "" HETC_M_MOB,HETC_M_WST,HETC_L_ARM,HETC_L_TACT,HETC_R_ARM,HETC_R_TACT,HMDH_201,HMDH_202,HMDH_203,HMDH_204,HMDH_206,HMDH_207
 SG_ EvtData : 24|32@1+ (1,0) [0|0] "" HETC_M_MOB,HETC_M_WST,HETC_L_ARM,HETC_L_TACT,HETC_R_ARM,HETC_R_TACT,HMDH_201,HMDH_202,HMDH_203,HMDH_204,HMDH_206,HMDH_207

BO_ 2163265279 CTRL_HMDH_206_to_ALL: 7 HMDH_206
 SG_ SubCode M : 0|8@1+ (1,0) [0|0] "" HETC_M_MOB,HETC_M_WST,HETC_L_ARM,HETC_L_TACT,HETC_R_ARM,HETC_R_TACT,HMDH_201,HMDH_202,HMDH_203,HMDH_204,HMDH_205,HMDH_207
 SG_ Rtc_Year2000 m9 : 8|8@1+ (1,0) [0|0] "" HETC_M_MOB,HETC_M_WST,HETC_L_ARM,HETC_L_TACT,HETC_R_ARM,HETC_R_TACT,HMDH_201,HMDH_202,HMDH_203,HMDH_204,HMDH_205,HMDH_207
 SG_ Rtc_Month m9 : 16|8@1+ (1,0) [0|0] "" HETC_M_MOB,HETC_M_WST,HETC_L_ARM,HETC_L_TACT,HETC_R_ARM,HETC_R_TACT,HMDH_201,HMDH_202,HMDH_203,HMDH_204,HMDH_205,HMDH_207
 SG_ Rtc_Day m9 : 24|8@1+ (1,0) [0|0] "" HETC_M_MOB,HETC_M_WST,HETC_L_ARM,HETC_L_TACT,HETC_R_ARM,HETC_R_TACT,HMDH_201,HMDH_202,HMDH_203,HMDH_204,HMDH_205,HMDH_207
 SG_ Rtc_Hour m9 : 32|8@1+ (1,0) [0|0] "" HETC_M_MOB,HETC_M_WST,HETC_L_ARM,HETC_L_TACT,HETC_R_ARM,HETC_R_TACT,HMDH_201,HMDH_202,HMDH_203,HMDH_204,HMDH_205,HMDH_207
 SG_ Rtc_Min m9 : 40|8@1+ (1,0) [0|0] "" HETC_M_MOB,HETC_M_WST,HETC_L_ARM,HETC_L_TACT,HETC_R_ARM,HETC_R_TACT,HMDH_201,HMDH_202,HMDH_203,HMDH_204,HMDH_205,HMDH_207
 SG_ Rtc_Sec m9 : 48|8@1+ (1,0) [0|0] "" HETC_M_MOB,HETC_M_WST,HETC_L_ARM,HETC_L_TACT,HETC_R_ARM,HETC_R_TACT,HMDH_201,HMDH_202,HMDH_203,HMDH_204,HMDH_205,HMDH_207

BO_ 2147667456 EVENT_HMDH_206_to_ALLHP: 7 HMDH_206
 SG_ EvtType : 0|8@1+ (1,0) [0|0] "" HETC_M_MOB,HETC_M_WST,HETC_L_ARM,HETC_L_TACT,HETC_R_ARM,HETC_R_TACT,HMDH_201,HMDH_202,HMDH_203,HMDH_204,HMDH_205,HMDH_207
 SG_ EvtCode : 8|16@1+ (1,0) [0|0] "" HETC_M_MOB,HETC_M_WST,HETC_L_ARM,HETC_L_TACT,HETC_R_ARM,HETC_R_TACT,HMDH_201,HMDH_202,HMDH_203,HMDH_204,HMDH_205,HMDH_207
 SG_ EvtData : 24|32@1+ (1,0) [0|0] "" HETC_M_MOB,HETC_M_WST,HETC_L_ARM,HETC_L_TACT,HETC_R_ARM,HETC_R_TACT,HMDH_201,HMDH_202,HMDH_203,HMDH_204,HMDH_205,HMDH_207

BO_ 2163265535 CTRL_HMDH_207_to_ALL: 7 HMDH_207
 SG_ SubCode M : 0|8@1+ (1,0) [0|0] "" HETC_M_MOB,HETC_M_WST,HETC_L_ARM,HETC_L_TACT,HETC_R_ARM,HETC_R_TACT,HMDH_201,HMDH_202,HMDH_203,HMDH_204,HMDH_205,HMDH_206
 SG_ Rtc_Year2000 m9 : 8|8@1+ (1,0) [0|0] "" HETC_M_MOB,HETC_M_WST,HETC_L_ARM,HETC_L_TACT,HETC_R_ARM,HETC_R_TACT,HMDH_201,HMDH_202,HMDH_203,HMDH_204,HMDH_205,HMDH_206
 SG_ Rtc_Month m9 : 16|8@1+ (1,0) [0|0] "" HETC_M_MOB,HETC_M_WST,HETC_L_ARM,HETC_L_TACT,HETC_R_ARM,HETC_R_TACT,HMDH_201,HMDH_202,HMDH_203,HMDH_204,HMDH_205,HMDH_206
 SG_ Rtc_Day m9 : 24|8@1+ (1,0) [0|0] "" HETC_M_MOB,HETC_M_WST,HETC_L_ARM,HETC_L_TACT,HETC_R_ARM,HETC_R_TACT,HMDH_201,HMDH_202,HMDH_203,HMDH_204,HMDH_205,HMDH_206
 SG_ Rtc_Hour m9 : 32|8@1+ (1,0) [0|0] "" HETC_M_MOB,HETC_M_WST,HETC_L_ARM,HETC_L_TACT,HETC_R_ARM,HETC_R_TACT,HMDH_201,HMDH_202,HMDH_203,HMDH_204,HMDH_205,HMDH_206
 SG_ Rtc_Min m9 : 40|8@1+ (1,0) [0|0] "" HETC_M_MOB,HETC_M_WST,HETC_L_ARM,HETC_L_TACT,HETC_R_ARM,HETC_R_TACT,HMDH_201,HMDH_202,HMDH_203,HMDH_204,HMDH_205,HMDH_206
 SG_ Rtc_Sec m9 : 48|8@1+ (1,0) [0|0] "" HETC_M_MOB,HETC_M_WST,HETC_L_ARM,HETC_L_TACT,HETC_R_ARM,HETC_R_TACT,HMDH_201,HMDH_202,HMDH_203,HMDH_204,HMDH_205,HMDH_206

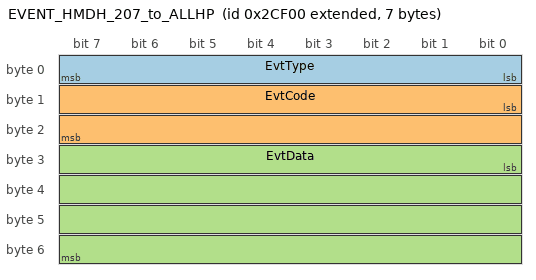
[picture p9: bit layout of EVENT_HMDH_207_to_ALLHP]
BO_ 2147667712 EVENT_HMDH_207_to_ALLHP: 7 HMDH_207
 SG_ EvtType : 0|8@1+ (1,0) [0|0] "" HETC_M_MOB,HETC_M_WST,HETC_L_ARM,HETC_L_TACT,HETC_R_ARM,HETC_R_TACT,HMDH_201,HMDH_202,HMDH_203,HMDH_204,HMDH_205,HMDH_206
 SG_ EvtCode : 8|16@1+ (1,0) [0|0] "" HETC_M_MOB,HETC_M_WST,HETC_L_ARM,HETC_L_TACT,HETC_R_ARM,HETC_R_TACT,HMDH_201,HMDH_202,HMDH_203,HMDH_204,HMDH_205,HMDH_206
 SG_ EvtData : 24|32@1+ (1,0) [0|0] "" HETC_M_MOB,HETC_M_WST,HETC_L_ARM,HETC_L_TACT,HETC_R_ARM,HETC_R_TACT,HMDH_201,HMDH_202,HMDH_203,HMDH_204,HMDH_205,HMDH_206

BO_ 2163303534 STATUS_HETC_M_MOB_to_HETC_M_WST: 48 HETC_M_MOB
 SG_ SubCode M : 0|8@1+ (1,0) [0|0] "" HETC_M_WST
 SG_ Ping_CanId m5 : 8|8@1+ (1,0) [0|0] "" HETC_M_WST
 SG_ Ping_HostId m5 : 16|8@1+ (1,0) [0|0] "" HETC_M_WST
 SG_ Ping_Pid m5 : 24|16@1+ (1,0) [0|0] "" HETC_M_WST
 SG_ Ping_Bid m5 : 40|16@1+ (1,0) [0|0] "" HETC_M_WST
 SG_ Ping_Mid m5 : 56|16@1+ (1,0) [0|0] "" HETC_M_WST
 SG_ Ping_VerMajor m5 : 72|8@1+ (1,0) [0|0] "" HETC_M_WST
 SG_ Ping_VerMinor m5 : 80|8@1+ (1,0) [0|0] "" HETC_M_WST
 SG_ Ping_VerPatch m5 : 88|8@1+ (1,0) [0|0] "" HETC_M_WST
 SG_ Ping_Name0 m5 : 96|8@1+ (1,0) [0|0] "" HETC_M_WST
 SG_ Ping_Name1 m5 : 104|8@1+ (1,0) [0|0] "" HETC_M_WST
 SG_ Ping_Name2 m5 : 112|8@1+ (1,0) [0|0] "" HETC_M_WST
 SG_ Ping_Name3 m5 : 120|8@1+ (1,0) [0|0] "" HETC_M_WST
 SG_ Ping_Name4 m5 : 128|8@1+ (1,0) [0|0] "" HETC_M_WST
 SG_ Ping_Name5 m5 : 136|8@1+ (1,0) [0|0] "" HETC_M_WST
 SG_ Ping_Name6 m5 : 144|8@1+ (1,0) [0|0] "" HETC_M_WST
 SG_ Ping_Name7 m5 : 152|8@1+ (1,0) [0|0] "" HETC_M_WST
 SG_ Ping_Name8 m5 : 160|8@1+ (1,0) [0|0] "" HETC_M_WST
 SG_ Ping_Name9 m5 : 168|8@1+ (1,0) [0|0] "" HETC_M_WST
 SG_ Ping_Name10 m5 : 176|8@1+ (1,0) [0|0] "" HETC_M_WST
 SG_ Ping_Name11 m5 : 184|8@1+ (1,0) [0|0] "" HETC_M_WST
 SG_ Ping_Name12 m5 : 192|8@1+ (1,0) [0|0] "" HETC_M_WST
 SG_ Ping_Name13 m5 : 200|8@1+ (1,0) [0|0] "" HETC_M_WST
 SG_ Ping_Name14 m5 : 208|8@1+ (1,0) [0|0] "" HETC_M_WST
 SG_ Ping_Name15 m5 : 216|8@1+ (1,0) [0|0] "" HETC_M_WST
 SG_ Ping_FmtVer m5 : 224|8@1+ (1,0) [0|0] "" HETC_M_WST
 SG_ Ping_GitRev m5 : 232|32@1+ (1,0) [0|0] "" HETC_M_WST
 SG_ Ping_FwCrc m5 : 264|16@1+ (1,0) [0|0] "" HETC_M_WST
 SG_ Ping_UptimeS m5 : 280|16@1+ (1,0) [0|0] "s" HETC_M_WST
 SG_ Ecat_CanId m31 : 8|8@1+ (1,0) [0|0] "" HETC_M_WST
 SG_ Ecat_Name0 m31 : 16|8@1+ (1,0) [0|0] "" HETC_M_WST
 SG_ Ecat_Name1 m31 : 24|8@1+ (1,0) [0|0] "" HETC_M_WST
 SG_ Ecat_Name2 m31 : 32|8@1+ (1,0) [0|0] "" HETC_M_WST
 SG_ Ecat_Name3 m31 : 40|8@1+ (1,0) [0|0] "" HETC_M_WST
 SG_ Ecat_Name4 m31 : 48|8@1+ (1,0) [0|0] "" HETC_M_WST
 SG_ Ecat_Name5 m31 : 56|8@1+ (1,0) [0|0] "" HETC_M_WST
 SG_ Ecat_Name6 m31 : 64|8@1+ (1,0) [0|0] "" HETC_M_WST
 SG_ Ecat_Name7 m31 : 72|8@1+ (1,0) [0|0] "" HETC_M_WST
 SG_ Ecat_Name8 m31 : 80|8@1+ (1,0) [0|0] "" HETC_M_WST
 SG_ Ecat_Name9 m31 : 88|8@1+ (1,0) [0|0] "" HETC_M_WST
 SG_ Ecat_Name10 m31 : 96|8@1+ (1,0) [0|0] "" HETC_M_WST
 SG_ Ecat_Name11 m31 : 104|8@1+ (1,0) [0|0] "" HETC_M_WST
 SG_ Ecat_Name12 m31 : 112|8@1+ (1,0) [0|0] "" HETC_M_WST
 SG_ Ecat_Name13 m31 : 120|8@1+ (1,0) [0|0] "" HETC_M_WST
 SG_ Ecat_Name14 m31 : 128|8@1+ (1,0) [0|0] "" HETC_M_WST
 SG_ Ecat_Name15 m31 : 136|8@1+ (1,0) [0|0] "" HETC_M_WST
 SG_ Ecat_Link m31 : 144|8@1+ (1,0) [0|0] "" HETC_M_WST
 SG_ Ecat_InvalidFrame0 m31 : 152|8@1+ (1,0) [0|0] "" HETC_M_WST
 SG_ Ecat_InvalidFrame1 m31 : 160|8@1+ (1,0) [0|0] "" HETC_M_WST
 SG_ Ecat_InvalidFrame2 m31 : 168|8@1+ (1,0) [0|0] "" HETC_M_WST
 SG_ Ecat_InvalidFrame3 m31 : 176|8@1+ (1,0) [0|0] "" HETC_M_WST
 SG_ Ecat_RxError0 m31 : 184|8@1+ (1,0) [0|0] "" HETC_M_WST
 SG_ Ecat_RxError1 m31 : 192|8@1+ (1,0) [0|0] "" HETC_M_WST
 SG_ Ecat_RxError2 m31 : 200|8@1+ (1,0) [0|0] "" HETC_M_WST
 SG_ Ecat_RxError3 m31 : 208|8@1+ (1,0) [0|0] "" HETC_M_WST
 SG_ Ecat_FwdRxError0 m31 : 216|8@1+ (1,0) [0|0] "" HETC_M_WST
 SG_ Ecat_FwdRxError1 m31 : 224|8@1+ (1,0) [0|0] "" HETC_M_WST
 SG_ Ecat_FwdRxError2 m31 : 232|8@1+ (1,0) [0|0] "" HETC_M_WST
 SG_ Ecat_FwdRxError3 m31 : 240|8@1+ (1,0) [0|0] "" HETC_M_WST
 SG_ Ecat_PuError m31 : 248|8@1+ (1,0) [0|0] "" HETC_M_WST
 SG_ Ecat_PdiError m31 : 256|8@1+ (1,0) [0|0] "" HETC_M_WST
 SG_ Ecat_LostLink0 m31 : 264|8@1+ (1,0) [0|0] "" HETC_M_WST
 SG_ Ecat_LostLink1 m31 : 272|8@1+ (1,0) [0|0] "" HETC_M_WST
 SG_ Ecat_LostLink2 m31 : 280|8@1+ (1,0) [0|0] "" HETC_M_WST
 SG_ Ecat_LostLink3 m31 : 288|8@1+ (1,0) [0|0] "" HETC_M_WST
 SG_ Saf_CanId m32 : 8|8@1+ (1,0) [0|0] "" HETC_M_WST
 SG_ Saf_Name0 m32 : 16|8@1+ (1,0) [0|0] "" HETC_M_WST
 SG_ Saf_Name1 m32 : 24|8@1+ (1,0) [0|0] "" HETC_M_WST
 SG_ Saf_Name2 m32 : 32|8@1+ (1,0) [0|0] "" HETC_M_WST
 SG_ Saf_Name3 m32 : 40|8@1+ (1,0) [0|0] "" HETC_M_WST
 SG_ Saf_Name4 m32 : 48|8@1+ (1,0) [0|0] "" HETC_M_WST
 SG_ Saf_Name5 m32 : 56|8@1+ (1,0) [0|0] "" HETC_M_WST
 SG_ Saf_Name6 m32 : 64|8@1+ (1,0) [0|0] "" HETC_M_WST
 SG_ Saf_Name7 m32 : 72|8@1+ (1,0) [0|0] "" HETC_M_WST
 SG_ Saf_Name8 m32 : 80|8@1+ (1,0) [0|0] "" HETC_M_WST
 SG_ Saf_Name9 m32 : 88|8@1+ (1,0) [0|0] "" HETC_M_WST
 SG_ Saf_Name10 m32 : 96|8@1+ (1,0) [0|0] "" HETC_M_WST
 SG_ Saf_Name11 m32 : 104|8@1+ (1,0) [0|0] "" HETC_M_WST
 SG_ Saf_Name12 m32 : 112|8@1+ (1,0) [0|0] "" HETC_M_WST
 SG_ Saf_Name13 m32 : 120|8@1+ (1,0) [0|0] "" HETC_M_WST
 SG_ Saf_Name14 m32 : 128|8@1+ (1,0) [0|0] "" HETC_M_WST
 SG_ Saf_Name15 m32 : 136|8@1+ (1,0) [0|0] "" HETC_M_WST
 SG_ Saf_State m32 : 144|8@1+ (1,0) [0|0] "" HETC_M_WST
 SG_ Saf_Bits m32 : 152|16@1+ (1,0) [0|0] "" HETC_M_WST
 SG_ Saf_Estop m32 : 168|8@1+ (1,0) [0|0] "" HETC_M_WST
 SG_ Saf_FatalLatched m32 : 176|16@1+ (1,0) [0|0] "" HETC_M_WST
 SG_ Saf_ErrCode m32 : 192|32@1+ (1,0) [0|0] "" HETC_M_WST

BO_ 2163303544 STATUS_HETC_M_MOB_to_HETC_L_ARM: 48 HETC_M_MOB
 SG_ SubCode M : 0|8@1+ (1,0) [0|0] "" HETC_L_ARM
 SG_ Ping_CanId m5 : 8|8@1+ (1,0) [0|0] "" HETC_L_ARM
 SG_ Ping_HostId m5 : 16|8@1+ (1,0) [0|0] "" HETC_L_ARM
 SG_ Ping_Pid m5 : 24|16@1+ (1,0) [0|0] "" HETC_L_ARM
 SG_ Ping_Bid m5 : 40|16@1+ (1,0) [0|0] "" HETC_L_ARM
 SG_ Ping_Mid m5 : 56|16@1+ (1,0) [0|0] "" HETC_L_ARM
 SG_ Ping_VerMajor m5 : 72|8@1+ (1,0) [0|0] "" HETC_L_ARM
 SG_ Ping_VerMinor m5 : 80|8@1+ (1,0) [0|0] "" HETC_L_ARM
 SG_ Ping_VerPatch m5 : 88|8@1+ (1,0) [0|0] "" HETC_L_ARM
 SG_ Ping_Name0 m5 : 96|8@1+ (1,0) [0|0] "" HETC_L_ARM
 SG_ Ping_Name1 m5 : 104|8@1+ (1,0) [0|0] "" HETC_L_ARM
 SG_ Ping_Name2 m5 : 112|8@1+ (1,0) [0|0] "" HETC_L_ARM
 SG_ Ping_Name3 m5 : 120|8@1+ (1,0) [0|0] "" HETC_L_ARM
 SG_ Ping_Name4 m5 : 128|8@1+ (1,0) [0|0] "" HETC_L_ARM
 SG_ Ping_Name5 m5 : 136|8@1+ (1,0) [0|0] "" HETC_L_ARM
 SG_ Ping_Name6 m5 : 144|8@1+ (1,0) [0|0] "" HETC_L_ARM
 SG_ Ping_Name7 m5 : 152|8@1+ (1,0) [0|0] "" HETC_L_ARM
 SG_ Ping_Name8 m5 : 160|8@1+ (1,0) [0|0] "" HETC_L_ARM
 SG_ Ping_Name9 m5 : 168|8@1+ (1,0) [0|0] "" HETC_L_ARM
 SG_ Ping_Name10 m5 : 176|8@1+ (1,0) [0|0] "" HETC_L_ARM
 SG_ Ping_Name11 m5 : 184|8@1+ (1,0) [0|0] "" HETC_L_ARM
 SG_ Ping_Name12 m5 : 192|8@1+ (1,0) [0|0] "" HETC_L_ARM
 SG_ Ping_Name13 m5 : 200|8@1+ (1,0) [0|0] "" HETC_L_ARM
 SG_ Ping_Name14 m5 : 208|8@1+ (1,0) [0|0] "" HETC_L_ARM
 SG_ Ping_Name15 m5 : 216|8@1+ (1,0) [0|0] "" HETC_L_ARM
 SG_ Ping_FmtVer m5 : 224|8@1+ (1,0) [0|0] "" HETC_L_ARM
 SG_ Ping_GitRev m5 : 232|32@1+ (1,0) [0|0] "" HETC_L_ARM
 SG_ Ping_FwCrc m5 : 264|16@1+ (1,0) [0|0] "" HETC_L_ARM
 SG_ Ping_UptimeS m5 : 280|16@1+ (1,0) [0|0] "s" HETC_L_ARM
 SG_ Ecat_CanId m31 : 8|8@1+ (1,0) [0|0] "" HETC_L_ARM
 SG_ Ecat_Name0 m31 : 16|8@1+ (1,0) [0|0] "" HETC_L_ARM
 SG_ Ecat_Name1 m31 : 24|8@1+ (1,0) [0|0] "" HETC_L_ARM
 SG_ Ecat_Name2 m31 : 32|8@1+ (1,0) [0|0] "" HETC_L_ARM
 SG_ Ecat_Name3 m31 : 40|8@1+ (1,0) [0|0] "" HETC_L_ARM
 SG_ Ecat_Name4 m31 : 48|8@1+ (1,0) [0|0] "" HETC_L_ARM
 SG_ Ecat_Name5 m31 : 56|8@1+ (1,0) [0|0] "" HETC_L_ARM
 SG_ Ecat_Name6 m31 : 64|8@1+ (1,0) [0|0] "" HETC_L_ARM
 SG_ Ecat_Name7 m31 : 72|8@1+ (1,0) [0|0] "" HETC_L_ARM
 SG_ Ecat_Name8 m31 : 80|8@1+ (1,0) [0|0] "" HETC_L_ARM
 SG_ Ecat_Name9 m31 : 88|8@1+ (1,0) [0|0] "" HETC_L_ARM
 SG_ Ecat_Name10 m31 : 96|8@1+ (1,0) [0|0] "" HETC_L_ARM
 SG_ Ecat_Name11 m31 : 104|8@1+ (1,0) [0|0] "" HETC_L_ARM
 SG_ Ecat_Name12 m31 : 112|8@1+ (1,0) [0|0] "" HETC_L_ARM
 SG_ Ecat_Name13 m31 : 120|8@1+ (1,0) [0|0] "" HETC_L_ARM
 SG_ Ecat_Name14 m31 : 128|8@1+ (1,0) [0|0] "" HETC_L_ARM
 SG_ Ecat_Name15 m31 : 136|8@1+ (1,0) [0|0] "" HETC_L_ARM
 SG_ Ecat_Link m31 : 144|8@1+ (1,0) [0|0] "" HETC_L_ARM
 SG_ Ecat_InvalidFrame0 m31 : 152|8@1+ (1,0) [0|0] "" HETC_L_ARM
 SG_ Ecat_InvalidFrame1 m31 : 160|8@1+ (1,0) [0|0] "" HETC_L_ARM
 SG_ Ecat_InvalidFrame2 m31 : 168|8@1+ (1,0) [0|0] "" HETC_L_ARM
 SG_ Ecat_InvalidFrame3 m31 : 176|8@1+ (1,0) [0|0] "" HETC_L_ARM
 SG_ Ecat_RxError0 m31 : 184|8@1+ (1,0) [0|0] "" HETC_L_ARM
 SG_ Ecat_RxError1 m31 : 192|8@1+ (1,0) [0|0] "" HETC_L_ARM
 SG_ Ecat_RxError2 m31 : 200|8@1+ (1,0) [0|0] "" HETC_L_ARM
 SG_ Ecat_RxError3 m31 : 208|8@1+ (1,0) [0|0] "" HETC_L_ARM
 SG_ Ecat_FwdRxError0 m31 : 216|8@1+ (1,0) [0|0] "" HETC_L_ARM
 SG_ Ecat_FwdRxError1 m31 : 224|8@1+ (1,0) [0|0] "" HETC_L_ARM
 SG_ Ecat_FwdRxError2 m31 : 232|8@1+ (1,0) [0|0] "" HETC_L_ARM
 SG_ Ecat_FwdRxError3 m31 : 240|8@1+ (1,0) [0|0] "" HETC_L_ARM
 SG_ Ecat_PuError m31 : 248|8@1+ (1,0) [0|0] "" HETC_L_ARM
 SG_ Ecat_PdiError m31 : 256|8@1+ (1,0) [0|0] "" HETC_L_ARM
 SG_ Ecat_LostLink0 m31 : 264|8@1+ (1,0) [0|0] "" HETC_L_ARM
 SG_ Ecat_LostLink1 m31 : 272|8@1+ (1,0) [0|0] "" HETC_L_ARM
 SG_ Ecat_LostLink2 m31 : 280|8@1+ (1,0) [0|0] "" HETC_L_ARM
 SG_ Ecat_LostLink3 m31 : 288|8@1+ (1,0) [0|0] "" HETC_L_ARM
 SG_ Saf_CanId m32 : 8|8@1+ (1,0) [0|0] "" HETC_L_ARM
 SG_ Saf_Name0 m32 : 16|8@1+ (1,0) [0|0] "" HETC_L_ARM
 SG_ Saf_Name1 m32 : 24|8@1+ (1,0) [0|0] "" HETC_L_ARM
 SG_ Saf_Name2 m32 : 32|8@1+ (1,0) [0|0] "" HETC_L_ARM
 SG_ Saf_Name3 m32 : 40|8@1+ (1,0) [0|0] "" HETC_L_ARM
 SG_ Saf_Name4 m32 : 48|8@1+ (1,0) [0|0] "" HETC_L_ARM
 SG_ Saf_Name5 m32 : 56|8@1+ (1,0) [0|0] "" HETC_L_ARM
 SG_ Saf_Name6 m32 : 64|8@1+ (1,0) [0|0] "" HETC_L_ARM
 SG_ Saf_Name7 m32 : 72|8@1+ (1,0) [0|0] "" HETC_L_ARM
 SG_ Saf_Name8 m32 : 80|8@1+ (1,0) [0|0] "" HETC_L_ARM
 SG_ Saf_Name9 m32 : 88|8@1+ (1,0) [0|0] "" HETC_L_ARM
 SG_ Saf_Name10 m32 : 96|8@1+ (1,0) [0|0] "" HETC_L_ARM
 SG_ Saf_Name11 m32 : 104|8@1+ (1,0) [0|0] "" HETC_L_ARM
 SG_ Saf_Name12 m32 : 112|8@1+ (1,0) [0|0] "" HETC_L_ARM
 SG_ Saf_Name13 m32 : 120|8@1+ (1,0) [0|0] "" HETC_L_ARM
 SG_ Saf_Name14 m32 : 128|8@1+ (1,0) [0|0] "" HETC_L_ARM
 SG_ Saf_Name15 m32 : 136|8@1+ (1,0) [0|0] "" HETC_L_ARM
 SG_ Saf_State m32 : 144|8@1+ (1,0) [0|0] "" HETC_L_ARM
 SG_ Saf_Bits m32 : 152|16@1+ (1,0) [0|0] "" HETC_L_ARM
 SG_ Saf_Estop m32 : 168|8@1+ (1,0) [0|0] "" HETC_L_ARM
 SG_ Saf_FatalLatched m32 : 176|16@1+ (1,0) [0|0] "" HETC_L_ARM
 SG_ Saf_ErrCode m32 : 192|32@1+ (1,0) [0|0] "" HETC_L_ARM

BO_ 2163303554 STATUS_HETC_M_MOB_to_HETC_L_TACT: 48 HETC_M_MOB
 SG_ SubCode M : 0|8@1+ (1,0) [0|0] "" HETC_L_TACT
 SG_ Ping_CanId m5 : 8|8@1+ (1,0) [0|0] "" HETC_L_TACT
 SG_ Ping_HostId m5 : 16|8@1+ (1,0) [0|0] "" HETC_L_TACT
 SG_ Ping_Pid m5 : 24|16@1+ (1,0) [0|0] "" HETC_L_TACT
 SG_ Ping_Bid m5 : 40|16@1+ (1,0) [0|0] "" HETC_L_TACT
 SG_ Ping_Mid m5 : 56|16@1+ (1,0) [0|0] "" HETC_L_TACT
 SG_ Ping_VerMajor m5 : 72|8@1+ (1,0) [0|0] "" HETC_L_TACT
 SG_ Ping_VerMinor m5 : 80|8@1+ (1,0) [0|0] "" HETC_L_TACT
 SG_ Ping_VerPatch m5 : 88|8@1+ (1,0) [0|0] "" HETC_L_TACT
 SG_ Ping_Name0 m5 : 96|8@1+ (1,0) [0|0] "" HETC_L_TACT
 SG_ Ping_Name1 m5 : 104|8@1+ (1,0) [0|0] "" HETC_L_TACT
 SG_ Ping_Name2 m5 : 112|8@1+ (1,0) [0|0] "" HETC_L_TACT
 SG_ Ping_Name3 m5 : 120|8@1+ (1,0) [0|0] "" HETC_L_TACT
 SG_ Ping_Name4 m5 : 128|8@1+ (1,0) [0|0] "" HETC_L_TACT
 SG_ Ping_Name5 m5 : 136|8@1+ (1,0) [0|0] "" HETC_L_TACT
 SG_ Ping_Name6 m5 : 144|8@1+ (1,0) [0|0] "" HETC_L_TACT
 SG_ Ping_Name7 m5 : 152|8@1+ (1,0) [0|0] "" HETC_L_TACT
 SG_ Ping_Name8 m5 : 160|8@1+ (1,0) [0|0] "" HETC_L_TACT
 SG_ Ping_Name9 m5 : 168|8@1+ (1,0) [0|0] "" HETC_L_TACT
 SG_ Ping_Name10 m5 : 176|8@1+ (1,0) [0|0] "" HETC_L_TACT
 SG_ Ping_Name11 m5 : 184|8@1+ (1,0) [0|0] "" HETC_L_TACT
 SG_ Ping_Name12 m5 : 192|8@1+ (1,0) [0|0] "" HETC_L_TACT
 SG_ Ping_Name13 m5 : 200|8@1+ (1,0) [0|0] "" HETC_L_TACT
 SG_ Ping_Name14 m5 : 208|8@1+ (1,0) [0|0] "" HETC_L_TACT
 SG_ Ping_Name15 m5 : 216|8@1+ (1,0) [0|0] "" HETC_L_TACT
 SG_ Ping_FmtVer m5 : 224|8@1+ (1,0) [0|0] "" HETC_L_TACT
 SG_ Ping_GitRev m5 : 232|32@1+ (1,0) [0|0] "" HETC_L_TACT
 SG_ Ping_FwCrc m5 : 264|16@1+ (1,0) [0|0] "" HETC_L_TACT
 SG_ Ping_UptimeS m5 : 280|16@1+ (1,0) [0|0] "s" HETC_L_TACT
 SG_ Ecat_CanId m31 : 8|8@1+ (1,0) [0|0] "" HETC_L_TACT
 SG_ Ecat_Name0 m31 : 16|8@1+ (1,0) [0|0] "" HETC_L_TACT
 SG_ Ecat_Name1 m31 : 24|8@1+ (1,0) [0|0] "" HETC_L_TACT
 SG_ Ecat_Name2 m31 : 32|8@1+ (1,0) [0|0] "" HETC_L_TACT
 SG_ Ecat_Name3 m31 : 40|8@1+ (1,0) [0|0] "" HETC_L_TACT
 SG_ Ecat_Name4 m31 : 48|8@1+ (1,0) [0|0] "" HETC_L_TACT
 SG_ Ecat_Name5 m31 : 56|8@1+ (1,0) [0|0] "" HETC_L_TACT
 SG_ Ecat_Name6 m31 : 64|8@1+ (1,0) [0|0] "" HETC_L_TACT
 SG_ Ecat_Name7 m31 : 72|8@1+ (1,0) [0|0] "" HETC_L_TACT
 SG_ Ecat_Name8 m31 : 80|8@1+ (1,0) [0|0] "" HETC_L_TACT
 SG_ Ecat_Name9 m31 : 88|8@1+ (1,0) [0|0] "" HETC_L_TACT
 SG_ Ecat_Name10 m31 : 96|8@1+ (1,0) [0|0] "" HETC_L_TACT
 SG_ Ecat_Name11 m31 : 104|8@1+ (1,0) [0|0] "" HETC_L_TACT
 SG_ Ecat_Name12 m31 : 112|8@1+ (1,0) [0|0] "" HETC_L_TACT
 SG_ Ecat_Name13 m31 : 120|8@1+ (1,0) [0|0] "" HETC_L_TACT
 SG_ Ecat_Name14 m31 : 128|8@1+ (1,0) [0|0] "" HETC_L_TACT
 SG_ Ecat_Name15 m31 : 136|8@1+ (1,0) [0|0] "" HETC_L_TACT
 SG_ Ecat_Link m31 : 144|8@1+ (1,0) [0|0] "" HETC_L_TACT
 SG_ Ecat_InvalidFrame0 m31 : 152|8@1+ (1,0) [0|0] "" HETC_L_TACT
 SG_ Ecat_InvalidFrame1 m31 : 160|8@1+ (1,0) [0|0] "" HETC_L_TACT
 SG_ Ecat_InvalidFrame2 m31 : 168|8@1+ (1,0) [0|0] "" HETC_L_TACT
 SG_ Ecat_InvalidFrame3 m31 : 176|8@1+ (1,0) [0|0] "" HETC_L_TACT
 SG_ Ecat_RxError0 m31 : 184|8@1+ (1,0) [0|0] "" HETC_L_TACT
 SG_ Ecat_RxError1 m31 : 192|8@1+ (1,0) [0|0] "" HETC_L_TACT
 SG_ Ecat_RxError2 m31 : 200|8@1+ (1,0) [0|0] "" HETC_L_TACT
 SG_ Ecat_RxError3 m31 : 208|8@1+ (1,0) [0|0] "" HETC_L_TACT
 SG_ Ecat_FwdRxError0 m31 : 216|8@1+ (1,0) [0|0] "" HETC_L_TACT
 SG_ Ecat_FwdRxError1 m31 : 224|8@1+ (1,0) [0|0] "" HETC_L_TACT
 SG_ Ecat_FwdRxError2 m31 : 232|8@1+ (1,0) [0|0] "" HETC_L_TACT
 SG_ Ecat_FwdRxError3 m31 : 240|8@1+ (1,0) [0|0] "" HETC_L_TACT
 SG_ Ecat_PuError m31 : 248|8@1+ (1,0) [0|0] "" HETC_L_TACT
 SG_ Ecat_PdiError m31 : 256|8@1+ (1,0) [0|0] "" HETC_L_TACT
 SG_ Ecat_LostLink0 m31 : 264|8@1+ (1,0) [0|0] "" HETC_L_TACT
 SG_ Ecat_LostLink1 m31 : 272|8@1+ (1,0) [0|0] "" HETC_L_TACT
 SG_ Ecat_LostLink2 m31 : 280|8@1+ (1,0) [0|0] "" HETC_L_TACT
 SG_ Ecat_LostLink3 m31 : 288|8@1+ (1,0) [0|0] "" HETC_L_TACT
 SG_ Saf_CanId m32 : 8|8@1+ (1,0) [0|0] "" HETC_L_TACT
 SG_ Saf_Name0 m32 : 16|8@1+ (1,0) [0|0] "" HETC_L_TACT
 SG_ Saf_Name1 m32 : 24|8@1+ (1,0) [0|0] "" HETC_L_TACT
 SG_ Saf_Name2 m32 : 32|8@1+ (1,0) [0|0] "" HETC_L_TACT
 SG_ Saf_Name3 m32 : 40|8@1+ (1,0) [0|0] "" HETC_L_TACT
 SG_ Saf_Name4 m32 : 48|8@1+ (1,0) [0|0] "" HETC_L_TACT
 SG_ Saf_Name5 m32 : 56|8@1+ (1,0) [0|0] "" HETC_L_TACT
 SG_ Saf_Name6 m32 : 64|8@1+ (1,0) [0|0] "" HETC_L_TACT
 SG_ Saf_Name7 m32 : 72|8@1+ (1,0) [0|0] "" HETC_L_TACT
 SG_ Saf_Name8 m32 : 80|8@1+ (1,0) [0|0] "" HETC_L_TACT
 SG_ Saf_Name9 m32 : 88|8@1+ (1,0) [0|0] "" HETC_L_TACT
 SG_ Saf_Name10 m32 : 96|8@1+ (1,0) [0|0] "" HETC_L_TACT
 SG_ Saf_Name11 m32 : 104|8@1+ (1,0) [0|0] "" HETC_L_TACT
 SG_ Saf_Name12 m32 : 112|8@1+ (1,0) [0|0] "" HETC_L_TACT
 SG_ Saf_Name13 m32 : 120|8@1+ (1,0) [0|0] "" HETC_L_TACT
 SG_ Saf_Name14 m32 : 128|8@1+ (1,0) [0|0] "" HETC_L_TACT
 SG_ Saf_Name15 m32 : 136|8@1+ (1,0) [0|0] "" HETC_L_TACT
 SG_ Saf_State m32 : 144|8@1+ (1,0) [0|0] "" HETC_L_TACT
 SG_ Saf_Bits m32 : 152|16@1+ (1,0) [0|0] "" HETC_L_TACT
 SG_ Saf_Estop m32 : 168|8@1+ (1,0) [0|0] "" HETC_L_TACT
 SG_ Saf_FatalLatched m32 : 176|16@1+ (1,0) [0|0] "" HETC_L_TACT
 SG_ Saf_ErrCode m32 : 192|32@1+ (1,0) [0|0] "" HETC_L_TACT

BO_ 2163303564 STATUS_HETC_M_MOB_to_HETC_R_ARM: 48 HETC_M_MOB
 SG_ SubCode M : 0|8@1+ (1,0) [0|0] "" HETC_R_ARM
 SG_ Ping_CanId m5 : 8|8@1+ (1,0) [0|0] "" HETC_R_ARM
 SG_ Ping_HostId m5 : 16|8@1+ (1,0) [0|0] "" HETC_R_ARM
 SG_ Ping_Pid m5 : 24|16@1+ (1,0) [0|0] "" HETC_R_ARM
 SG_ Ping_Bid m5 : 40|16@1+ (1,0) [0|0] "" HETC_R_ARM
 SG_ Ping_Mid m5 : 56|16@1+ (1,0) [0|0] "" HETC_R_ARM
 SG_ Ping_VerMajor m5 : 72|8@1+ (1,0) [0|0] "" HETC_R_ARM
 SG_ Ping_VerMinor m5 : 80|8@1+ (1,0) [0|0] "" HETC_R_ARM
 SG_ Ping_VerPatch m5 : 88|8@1+ (1,0) [0|0] "" HETC_R_ARM
 SG_ Ping_Name0 m5 : 96|8@1+ (1,0) [0|0] "" HETC_R_ARM
 SG_ Ping_Name1 m5 : 104|8@1+ (1,0) [0|0] "" HETC_R_ARM
 SG_ Ping_Name2 m5 : 112|8@1+ (1,0) [0|0] "" HETC_R_ARM
 SG_ Ping_Name3 m5 : 120|8@1+ (1,0) [0|0] "" HETC_R_ARM
 SG_ Ping_Name4 m5 : 128|8@1+ (1,0) [0|0] "" HETC_R_ARM
 SG_ Ping_Name5 m5 : 136|8@1+ (1,0) [0|0] "" HETC_R_ARM
 SG_ Ping_Name6 m5 : 144|8@1+ (1,0) [0|0] "" HETC_R_ARM
 SG_ Ping_Name7 m5 : 152|8@1+ (1,0) [0|0] "" HETC_R_ARM
 SG_ Ping_Name8 m5 : 160|8@1+ (1,0) [0|0] "" HETC_R_ARM
 SG_ Ping_Name9 m5 : 168|8@1+ (1,0) [0|0] "" HETC_R_ARM
 SG_ Ping_Name10 m5 : 176|8@1+ (1,0) [0|0] "" HETC_R_ARM
 SG_ Ping_Name11 m5 : 184|8@1+ (1,0) [0|0] "" HETC_R_ARM
 SG_ Ping_Name12 m5 : 192|8@1+ (1,0) [0|0] "" HETC_R_ARM
 SG_ Ping_Name13 m5 : 200|8@1+ (1,0) [0|0] "" HETC_R_ARM
 SG_ Ping_Name14 m5 : 208|8@1+ (1,0) [0|0] "" HETC_R_ARM
 SG_ Ping_Name15 m5 : 216|8@1+ (1,0) [0|0] "" HETC_R_ARM
 SG_ Ping_FmtVer m5 : 224|8@1+ (1,0) [0|0] "" HETC_R_ARM
 SG_ Ping_GitRev m5 : 232|32@1+ (1,0) [0|0] "" HETC_R_ARM
 SG_ Ping_FwCrc m5 : 264|16@1+ (1,0) [0|0] "" HETC_R_ARM
 SG_ Ping_UptimeS m5 : 280|16@1+ (1,0) [0|0] "s" HETC_R_ARM
 SG_ Ecat_CanId m31 : 8|8@1+ (1,0) [0|0] "" HETC_R_ARM
 SG_ Ecat_Name0 m31 : 16|8@1+ (1,0) [0|0] "" HETC_R_ARM
 SG_ Ecat_Name1 m31 : 24|8@1+ (1,0) [0|0] "" HETC_R_ARM
 SG_ Ecat_Name2 m31 : 32|8@1+ (1,0) [0|0] "" HETC_R_ARM
 SG_ Ecat_Name3 m31 : 40|8@1+ (1,0) [0|0] "" HETC_R_ARM
 SG_ Ecat_Name4 m31 : 48|8@1+ (1,0) [0|0] "" HETC_R_ARM
 SG_ Ecat_Name5 m31 : 56|8@1+ (1,0) [0|0] "" HETC_R_ARM
 SG_ Ecat_Name6 m31 : 64|8@1+ (1,0) [0|0] "" HETC_R_ARM
 SG_ Ecat_Name7 m31 : 72|8@1+ (1,0) [0|0] "" HETC_R_ARM
 SG_ Ecat_Name8 m31 : 80|8@1+ (1,0) [0|0] "" HETC_R_ARM
 SG_ Ecat_Name9 m31 : 88|8@1+ (1,0) [0|0] "" HETC_R_ARM
 SG_ Ecat_Name10 m31 : 96|8@1+ (1,0) [0|0] "" HETC_R_ARM
 SG_ Ecat_Name11 m31 : 104|8@1+ (1,0) [0|0] "" HETC_R_ARM
 SG_ Ecat_Name12 m31 : 112|8@1+ (1,0) [0|0] "" HETC_R_ARM
 SG_ Ecat_Name13 m31 : 120|8@1+ (1,0) [0|0] "" HETC_R_ARM
 SG_ Ecat_Name14 m31 : 128|8@1+ (1,0) [0|0] "" HETC_R_ARM
 SG_ Ecat_Name15 m31 : 136|8@1+ (1,0) [0|0] "" HETC_R_ARM
 SG_ Ecat_Link m31 : 144|8@1+ (1,0) [0|0] "" HETC_R_ARM
 SG_ Ecat_InvalidFrame0 m31 : 152|8@1+ (1,0) [0|0] "" HETC_R_ARM
 SG_ Ecat_InvalidFrame1 m31 : 160|8@1+ (1,0) [0|0] "" HETC_R_ARM
 SG_ Ecat_InvalidFrame2 m31 : 168|8@1+ (1,0) [0|0] "" HETC_R_ARM
 SG_ Ecat_InvalidFrame3 m31 : 176|8@1+ (1,0) [0|0] "" HETC_R_ARM
 SG_ Ecat_RxError0 m31 : 184|8@1+ (1,0) [0|0] "" HETC_R_ARM
 SG_ Ecat_RxError1 m31 : 192|8@1+ (1,0) [0|0] "" HETC_R_ARM
 SG_ Ecat_RxError2 m31 : 200|8@1+ (1,0) [0|0] "" HETC_R_ARM
 SG_ Ecat_RxError3 m31 : 208|8@1+ (1,0) [0|0] "" HETC_R_ARM
 SG_ Ecat_FwdRxError0 m31 : 216|8@1+ (1,0) [0|0] "" HETC_R_ARM
 SG_ Ecat_FwdRxError1 m31 : 224|8@1+ (1,0) [0|0] "" HETC_R_ARM
 SG_ Ecat_FwdRxError2 m31 : 232|8@1+ (1,0) [0|0] "" HETC_R_ARM
 SG_ Ecat_FwdRxError3 m31 : 240|8@1+ (1,0) [0|0] "" HETC_R_ARM
 SG_ Ecat_PuError m31 : 248|8@1+ (1,0) [0|0] "" HETC_R_ARM
 SG_ Ecat_PdiError m31 : 256|8@1+ (1,0) [0|0] "" HETC_R_ARM
 SG_ Ecat_LostLink0 m31 : 264|8@1+ (1,0) [0|0] "" HETC_R_ARM
 SG_ Ecat_LostLink1 m31 : 272|8@1+ (1,0) [0|0] "" HETC_R_ARM
 SG_ Ecat_LostLink2 m31 : 280|8@1+ (1,0) [0|0] "" HETC_R_ARM
 SG_ Ecat_LostLink3 m31 : 288|8@1+ (1,0) [0|0] "" HETC_R_ARM
 SG_ Saf_CanId m32 : 8|8@1+ (1,0) [0|0] "" HETC_R_ARM
 SG_ Saf_Name0 m32 : 16|8@1+ (1,0) [0|0] "" HETC_R_ARM
 SG_ Saf_Name1 m32 : 24|8@1+ (1,0) [0|0] "" HETC_R_ARM
 SG_ Saf_Name2 m32 : 32|8@1+ (1,0) [0|0] "" HETC_R_ARM
 SG_ Saf_Name3 m32 : 40|8@1+ (1,0) [0|0] "" HETC_R_ARM
 SG_ Saf_Name4 m32 : 48|8@1+ (1,0) [0|0] "" HETC_R_ARM
 SG_ Saf_Name5 m32 : 56|8@1+ (1,0) [0|0] "" HETC_R_ARM
 SG_ Saf_Name6 m32 : 64|8@1+ (1,0) [0|0] "" HETC_R_ARM
 SG_ Saf_Name7 m32 : 72|8@1+ (1,0) [0|0] "" HETC_R_ARM
 SG_ Saf_Name8 m32 : 80|8@1+ (1,0) [0|0] "" HETC_R_ARM
 SG_ Saf_Name9 m32 : 88|8@1+ (1,0) [0|0] "" HETC_R_ARM
 SG_ Saf_Name10 m32 : 96|8@1+ (1,0) [0|0] "" HETC_R_ARM
 SG_ Saf_Name11 m32 : 104|8@1+ (1,0) [0|0] "" HETC_R_ARM
 SG_ Saf_Name12 m32 : 112|8@1+ (1,0) [0|0] "" HETC_R_ARM
 SG_ Saf_Name13 m32 : 120|8@1+ (1,0) [0|0] "" HETC_R_ARM
 SG_ Saf_Name14 m32 : 128|8@1+ (1,0) [0|0] "" HETC_R_ARM
 SG_ Saf_Name15 m32 : 136|8@1+ (1,0) [0|0] "" HETC_R_ARM
 SG_ Saf_State m32 : 144|8@1+ (1,0) [0|0] "" HETC_R_ARM
 SG_ Saf_Bits m32 : 152|16@1+ (1,0) [0|0] "" HETC_R_ARM
 SG_ Saf_Estop m32 : 168|8@1+ (1,0) [0|0] "" HETC_R_ARM
 SG_ Saf_FatalLatched m32 : 176|16@1+ (1,0) [0|0] "" HETC_R_ARM
 SG_ Saf_ErrCode m32 : 192|32@1+ (1,0) [0|0] "" HETC_R_ARM

BO_ 2163303574 STATUS_HETC_M_MOB_to_HETC_R_TACT: 48 HETC_M_MOB
 SG_ SubCode M : 0|8@1+ (1,0) [0|0] "" HETC_R_TACT
 SG_ Ping_CanId m5 : 8|8@1+ (1,0) [0|0] "" HETC_R_TACT
 SG_ Ping_HostId m5 : 16|8@1+ (1,0) [0|0] "" HETC_R_TACT
 SG_ Ping_Pid m5 : 24|16@1+ (1,0) [0|0] "" HETC_R_TACT
 SG_ Ping_Bid m5 : 40|16@1+ (1,0) [0|0] "" HETC_R_TACT
 SG_ Ping_Mid m5 : 56|16@1+ (1,0) [0|0] "" HETC_R_TACT
 SG_ Ping_VerMajor m5 : 72|8@1+ (1,0) [0|0] "" HETC_R_TACT
 SG_ Ping_VerMinor m5 : 80|8@1+ (1,0) [0|0] "" HETC_R_TACT
 SG_ Ping_VerPatch m5 : 88|8@1+ (1,0) [0|0] "" HETC_R_TACT
 SG_ Ping_Name0 m5 : 96|8@1+ (1,0) [0|0] "" HETC_R_TACT
 SG_ Ping_Name1 m5 : 104|8@1+ (1,0) [0|0] "" HETC_R_TACT
 SG_ Ping_Name2 m5 : 112|8@1+ (1,0) [0|0] "" HETC_R_TACT
 SG_ Ping_Name3 m5 : 120|8@1+ (1,0) [0|0] "" HETC_R_TACT
 SG_ Ping_Name4 m5 : 128|8@1+ (1,0) [0|0] "" HETC_R_TACT
 SG_ Ping_Name5 m5 : 136|8@1+ (1,0) [0|0] "" HETC_R_TACT
 SG_ Ping_Name6 m5 : 144|8@1+ (1,0) [0|0] "" HETC_R_TACT
 SG_ Ping_Name7 m5 : 152|8@1+ (1,0) [0|0] "" HETC_R_TACT
 SG_ Ping_Name8 m5 : 160|8@1+ (1,0) [0|0] "" HETC_R_TACT
 SG_ Ping_Name9 m5 : 168|8@1+ (1,0) [0|0] "" HETC_R_TACT
 SG_ Ping_Name10 m5 : 176|8@1+ (1,0) [0|0] "" HETC_R_TACT
 SG_ Ping_Name11 m5 : 184|8@1+ (1,0) [0|0] "" HETC_R_TACT
 SG_ Ping_Name12 m5 : 192|8@1+ (1,0) [0|0] "" HETC_R_TACT
 SG_ Ping_Name13 m5 : 200|8@1+ (1,0) [0|0] "" HETC_R_TACT
 SG_ Ping_Name14 m5 : 208|8@1+ (1,0) [0|0] "" HETC_R_TACT
 SG_ Ping_Name15 m5 : 216|8@1+ (1,0) [0|0] "" HETC_R_TACT
 SG_ Ping_FmtVer m5 : 224|8@1+ (1,0) [0|0] "" HETC_R_TACT
 SG_ Ping_GitRev m5 : 232|32@1+ (1,0) [0|0] "" HETC_R_TACT
 SG_ Ping_FwCrc m5 : 264|16@1+ (1,0) [0|0] "" HETC_R_TACT
 SG_ Ping_UptimeS m5 : 280|16@1+ (1,0) [0|0] "s" HETC_R_TACT
 SG_ Ecat_CanId m31 : 8|8@1+ (1,0) [0|0] "" HETC_R_TACT
 SG_ Ecat_Name0 m31 : 16|8@1+ (1,0) [0|0] "" HETC_R_TACT
 SG_ Ecat_Name1 m31 : 24|8@1+ (1,0) [0|0] "" HETC_R_TACT
 SG_ Ecat_Name2 m31 : 32|8@1+ (1,0) [0|0] "" HETC_R_TACT
 SG_ Ecat_Name3 m31 : 40|8@1+ (1,0) [0|0] "" HETC_R_TACT
 SG_ Ecat_Name4 m31 : 48|8@1+ (1,0) [0|0] "" HETC_R_TACT
 SG_ Ecat_Name5 m31 : 56|8@1+ (1,0) [0|0] "" HETC_R_TACT
 SG_ Ecat_Name6 m31 : 64|8@1+ (1,0) [0|0] "" HETC_R_TACT
 SG_ Ecat_Name7 m31 : 72|8@1+ (1,0) [0|0] "" HETC_R_TACT
 SG_ Ecat_Name8 m31 : 80|8@1+ (1,0) [0|0] "" HETC_R_TACT
 SG_ Ecat_Name9 m31 : 88|8@1+ (1,0) [0|0] "" HETC_R_TACT
 SG_ Ecat_Name10 m31 : 96|8@1+ (1,0) [0|0] "" HETC_R_TACT
 SG_ Ecat_Name11 m31 : 104|8@1+ (1,0) [0|0] "" HETC_R_TACT
 SG_ Ecat_Name12 m31 : 112|8@1+ (1,0) [0|0] "" HETC_R_TACT
 SG_ Ecat_Name13 m31 : 120|8@1+ (1,0) [0|0] "" HETC_R_TACT
 SG_ Ecat_Name14 m31 : 128|8@1+ (1,0) [0|0] "" HETC_R_TACT
 SG_ Ecat_Name15 m31 : 136|8@1+ (1,0) [0|0] "" HETC_R_TACT
 SG_ Ecat_Link m31 : 144|8@1+ (1,0) [0|0] "" HETC_R_TACT
 SG_ Ecat_InvalidFrame0 m31 : 152|8@1+ (1,0) [0|0] "" HETC_R_TACT
 SG_ Ecat_InvalidFrame1 m31 : 160|8@1+ (1,0) [0|0] "" HETC_R_TACT
 SG_ Ecat_InvalidFrame2 m31 : 168|8@1+ (1,0) [0|0] "" HETC_R_TACT
 SG_ Ecat_InvalidFrame3 m31 : 176|8@1+ (1,0) [0|0] "" HETC_R_TACT
 SG_ Ecat_RxError0 m31 : 184|8@1+ (1,0) [0|0] "" HETC_R_TACT
 SG_ Ecat_RxError1 m31 : 192|8@1+ (1,0) [0|0] "" HETC_R_TACT
 SG_ Ecat_RxError2 m31 : 200|8@1+ (1,0) [0|0] "" HETC_R_TACT
 SG_ Ecat_RxError3 m31 : 208|8@1+ (1,0) [0|0] "" HETC_R_TACT
 SG_ Ecat_FwdRxError0 m31 : 216|8@1+ (1,0) [0|0] "" HETC_R_TACT
 SG_ Ecat_FwdRxError1 m31 : 224|8@1+ (1,0) [0|0] "" HETC_R_TACT
 SG_ Ecat_FwdRxError2 m31 : 232|8@1+ (1,0) [0|0] "" HETC_R_TACT
 SG_ Ecat_FwdRxError3 m31 : 240|8@1+ (1,0) [0|0] "" HETC_R_TACT
 SG_ Ecat_PuError m31 : 248|8@1+ (1,0) [0|0] "" HETC_R_TACT
 SG_ Ecat_PdiError m31 : 256|8@1+ (1,0) [0|0] "" HETC_R_TACT
 SG_ Ecat_LostLink0 m31 : 264|8@1+ (1,0) [0|0] "" HETC_R_TACT
 SG_ Ecat_LostLink1 m31 : 272|8@1+ (1,0) [0|0] "" HETC_R_TACT
 SG_ Ecat_LostLink2 m31 : 280|8@1+ (1,0) [0|0] "" HETC_R_TACT
 SG_ Ecat_LostLink3 m31 : 288|8@1+ (1,0) [0|0] "" HETC_R_TACT
 SG_ Saf_CanId m32 : 8|8@1+ (1,0) [0|0] "" HETC_R_TACT
 SG_ Saf_Name0 m32 : 16|8@1+ (1,0) [0|0] "" HETC_R_TACT
 SG_ Saf_Name1 m32 : 24|8@1+ (1,0) [0|0] "" HETC_R_TACT
 SG_ Saf_Name2 m32 : 32|8@1+ (1,0) [0|0] "" HETC_R_TACT
 SG_ Saf_Name3 m32 : 40|8@1+ (1,0) [0|0] "" HETC_R_TACT
 SG_ Saf_Name4 m32 : 48|8@1+ (1,0) [0|0] "" HETC_R_TACT
 SG_ Saf_Name5 m32 : 56|8@1+ (1,0) [0|0] "" HETC_R_TACT
 SG_ Saf_Name6 m32 : 64|8@1+ (1,0) [0|0] "" HETC_R_TACT
 SG_ Saf_Name7 m32 : 72|8@1+ (1,0) [0|0] "" HETC_R_TACT
 SG_ Saf_Name8 m32 : 80|8@1+ (1,0) [0|0] "" HETC_R_TACT
 SG_ Saf_Name9 m32 : 88|8@1+ (1,0) [0|0] "" HETC_R_TACT
 SG_ Saf_Name10 m32 : 96|8@1+ (1,0) [0|0] "" HETC_R_TACT
 SG_ Saf_Name11 m32 : 104|8@1+ (1,0) [0|0] "" HETC_R_TACT
 SG_ Saf_Name12 m32 : 112|8@1+ (1,0) [0|0] "" HETC_R_TACT
 SG_ Saf_Name13 m32 : 120|8@1+ (1,0) [0|0] "" HETC_R_TACT
 SG_ Saf_Name14 m32 : 128|8@1+ (1,0) [0|0] "" HETC_R_TACT
 SG_ Saf_Name15 m32 : 136|8@1+ (1,0) [0|0] "" HETC_R_TACT
 SG_ Saf_State m32 : 144|8@1+ (1,0) [0|0] "" HETC_R_TACT
 SG_ Saf_Bits m32 : 152|16@1+ (1,0) [0|0] "" HETC_R_TACT
 SG_ Saf_Estop m32 : 168|8@1+ (1,0) [0|0] "" HETC_R_TACT
 SG_ Saf_FatalLatched m32 : 176|16@1+ (1,0) [0|0] "" HETC_R_TACT
 SG_ Saf_ErrCode m32 : 192|32@1+ (1,0) [0|0] "" HETC_R_TACT

BO_ 2163303625 STATUS_HETC_M_MOB_to_HMDH_201: 48 HETC_M_MOB
 SG_ SubCode M : 0|8@1+ (1,0) [0|0] "" HMDH_201
 SG_ Ping_CanId m5 : 8|8@1+ (1,0) [0|0] "" HMDH_201
 SG_ Ping_HostId m5 : 16|8@1+ (1,0) [0|0] "" HMDH_201
 SG_ Ping_Pid m5 : 24|16@1+ (1,0) [0|0] "" HMDH_201
 SG_ Ping_Bid m5 : 40|16@1+ (1,0) [0|0] "" HMDH_201
 SG_ Ping_Mid m5 : 56|16@1+ (1,0) [0|0] "" HMDH_201
 SG_ Ping_VerMajor m5 : 72|8@1+ (1,0) [0|0] "" HMDH_201
 SG_ Ping_VerMinor m5 : 80|8@1+ (1,0) [0|0] "" HMDH_201
 SG_ Ping_VerPatch m5 : 88|8@1+ (1,0) [0|0] "" HMDH_201
 SG_ Ping_Name0 m5 : 96|8@1+ (1,0) [0|0] "" HMDH_201
 SG_ Ping_Name1 m5 : 104|8@1+ (1,0) [0|0] "" HMDH_201
 SG_ Ping_Name2 m5 : 112|8@1+ (1,0) [0|0] "" HMDH_201
 SG_ Ping_Name3 m5 : 120|8@1+ (1,0) [0|0] "" HMDH_201
 SG_ Ping_Name4 m5 : 128|8@1+ (1,0) [0|0] "" HMDH_201
 SG_ Ping_Name5 m5 : 136|8@1+ (1,0) [0|0] "" HMDH_201
 SG_ Ping_Name6 m5 : 144|8@1+ (1,0) [0|0] "" HMDH_201
 SG_ Ping_Name7 m5 : 152|8@1+ (1,0) [0|0] "" HMDH_201
 SG_ Ping_Name8 m5 : 160|8@1+ (1,0) [0|0] "" HMDH_201
 SG_ Ping_Name9 m5 : 168|8@1+ (1,0) [0|0] "" HMDH_201
 SG_ Ping_Name10 m5 : 176|8@1+ (1,0) [0|0] "" HMDH_201
 SG_ Ping_Name11 m5 : 184|8@1+ (1,0) [0|0] "" HMDH_201
 SG_ Ping_Name12 m5 : 192|8@1+ (1,0) [0|0] "" HMDH_201
 SG_ Ping_Name13 m5 : 200|8@1+ (1,0) [0|0] "" HMDH_201
 SG_ Ping_Name14 m5 : 208|8@1+ (1,0) [0|0] "" HMDH_201
 SG_ Ping_Name15 m5 : 216|8@1+ (1,0) [0|0] "" HMDH_201
 SG_ Ping_FmtVer m5 : 224|8@1+ (1,0) [0|0] "" HMDH_201
 SG_ Ping_GitRev m5 : 232|32@1+ (1,0) [0|0] "" HMDH_201
 SG_ Ping_FwCrc m5 : 264|16@1+ (1,0) [0|0] "" HMDH_201
 SG_ Ping_UptimeS m5 : 280|16@1+ (1,0) [0|0] "s" HMDH_201
 SG_ Ecat_CanId m31 : 8|8@1+ (1,0) [0|0] "" HMDH_201
 SG_ Ecat_Name0 m31 : 16|8@1+ (1,0) [0|0] "" HMDH_201
 SG_ Ecat_Name1 m31 : 24|8@1+ (1,0) [0|0] "" HMDH_201
 SG_ Ecat_Name2 m31 : 32|8@1+ (1,0) [0|0] "" HMDH_201
 SG_ Ecat_Name3 m31 : 40|8@1+ (1,0) [0|0] "" HMDH_201
 SG_ Ecat_Name4 m31 : 48|8@1+ (1,0) [0|0] "" HMDH_201
 SG_ Ecat_Name5 m31 : 56|8@1+ (1,0) [0|0] "" HMDH_201
 SG_ Ecat_Name6 m31 : 64|8@1+ (1,0) [0|0] "" HMDH_201
 SG_ Ecat_Name7 m31 : 72|8@1+ (1,0) [0|0] "" HMDH_201
 SG_ Ecat_Name8 m31 : 80|8@1+ (1,0) [0|0] "" HMDH_201
 SG_ Ecat_Name9 m31 : 88|8@1+ (1,0) [0|0] "" HMDH_201
 SG_ Ecat_Name10 m31 : 96|8@1+ (1,0) [0|0] "" HMDH_201
 SG_ Ecat_Name11 m31 : 104|8@1+ (1,0) [0|0] "" HMDH_201
 SG_ Ecat_Name12 m31 : 112|8@1+ (1,0) [0|0] "" HMDH_201
 SG_ Ecat_Name13 m31 : 120|8@1+ (1,0) [0|0] "" HMDH_201
 SG_ Ecat_Name14 m31 : 128|8@1+ (1,0) [0|0] "" HMDH_201
 SG_ Ecat_Name15 m31 : 136|8@1+ (1,0) [0|0] "" HMDH_201
 SG_ Ecat_Link m31 : 144|8@1+ (1,0) [0|0] "" HMDH_201
 SG_ Ecat_InvalidFrame0 m31 : 152|8@1+ (1,0) [0|0] "" HMDH_201
 SG_ Ecat_InvalidFrame1 m31 : 160|8@1+ (1,0) [0|0] "" HMDH_201
 SG_ Ecat_InvalidFrame2 m31 : 168|8@1+ (1,0) [0|0] "" HMDH_201
 SG_ Ecat_InvalidFrame3 m31 : 176|8@1+ (1,0) [0|0] "" HMDH_201
 SG_ Ecat_RxError0 m31 : 184|8@1+ (1,0) [0|0] "" HMDH_201
 SG_ Ecat_RxError1 m31 : 192|8@1+ (1,0) [0|0] "" HMDH_201
 SG_ Ecat_RxError2 m31 : 200|8@1+ (1,0) [0|0] "" HMDH_201
 SG_ Ecat_RxError3 m31 : 208|8@1+ (1,0) [0|0] "" HMDH_201
 SG_ Ecat_FwdRxError0 m31 : 216|8@1+ (1,0) [0|0] "" HMDH_201
 SG_ Ecat_FwdRxError1 m31 : 224|8@1+ (1,0) [0|0] "" HMDH_201
 SG_ Ecat_FwdRxError2 m31 : 232|8@1+ (1,0) [0|0] "" HMDH_201
 SG_ Ecat_FwdRxError3 m31 : 240|8@1+ (1,0) [0|0] "" HMDH_201
 SG_ Ecat_PuError m31 : 248|8@1+ (1,0) [0|0] "" HMDH_201
 SG_ Ecat_PdiError m31 : 256|8@1+ (1,0) [0|0] "" HMDH_201
 SG_ Ecat_LostLink0 m31 : 264|8@1+ (1,0) [0|0] "" HMDH_201
 SG_ Ecat_LostLink1 m31 : 272|8@1+ (1,0) [0|0] "" HMDH_201
 SG_ Ecat_LostLink2 m31 : 280|8@1+ (1,0) [0|0] "" HMDH_201
 SG_ Ecat_LostLink3 m31 : 288|8@1+ (1,0) [0|0] "" HMDH_201
 SG_ Saf_CanId m32 : 8|8@1+ (1,0) [0|0] "" HMDH_201
 SG_ Saf_Name0 m32 : 16|8@1+ (1,0) [0|0] "" HMDH_201
 SG_ Saf_Name1 m32 : 24|8@1+ (1,0) [0|0] "" HMDH_201
 SG_ Saf_Name2 m32 : 32|8@1+ (1,0) [0|0] "" HMDH_201
 SG_ Saf_Name3 m32 : 40|8@1+ (1,0) [0|0] "" HMDH_201
 SG_ Saf_Name4 m32 : 48|8@1+ (1,0) [0|0] "" HMDH_201
 SG_ Saf_Name5 m32 : 56|8@1+ (1,0) [0|0] "" HMDH_201
 SG_ Saf_Name6 m32 : 64|8@1+ (1,0) [0|0] "" HMDH_201
 SG_ Saf_Name7 m32 : 72|8@1+ (1,0) [0|0] "" HMDH_201
 SG_ Saf_Name8 m32 : 80|8@1+ (1,0) [0|0] "" HMDH_201
 SG_ Saf_Name9 m32 : 88|8@1+ (1,0) [0|0] "" HMDH_201
 SG_ Saf_Name10 m32 : 96|8@1+ (1,0) [0|0] "" HMDH_201
 SG_ Saf_Name11 m32 : 104|8@1+ (1,0) [0|0] "" HMDH_201
 SG_ Saf_Name12 m32 : 112|8@1+ (1,0) [0|0] "" HMDH_201
 SG_ Saf_Name13 m32 : 120|8@1+ (1,0) [0|0] "" HMDH_201
 SG_ Saf_Name14 m32 : 128|8@1+ (1,0) [0|0] "" HMDH_201
 SG_ Saf_Name15 m32 : 136|8@1+ (1,0) [0|0] "" HMDH_201
 SG_ Saf_State m32 : 144|8@1+ (1,0) [0|0] "" HMDH_201
 SG_ Saf_Bits m32 : 152|16@1+ (1,0) [0|0] "" HMDH_201
 SG_ Saf_Estop m32 : 168|8@1+ (1,0) [0|0] "" HMDH_201
 SG_ Saf_FatalLatched m32 : 176|16@1+ (1,0) [0|0] "" HMDH_201
 SG_ Saf_ErrCode m32 : 192|32@1+ (1,0) [0|0] "" HMDH_201

BO_ 2163303626 STATUS_HETC_M_MOB_to_HMDH_202: 48 HETC_M_MOB
 SG_ SubCode M : 0|8@1+ (1,0) [0|0] "" HMDH_202
 SG_ Ping_CanId m5 : 8|8@1+ (1,0) [0|0] "" HMDH_202
 SG_ Ping_HostId m5 : 16|8@1+ (1,0) [0|0] "" HMDH_202
 SG_ Ping_Pid m5 : 24|16@1+ (1,0) [0|0] "" HMDH_202
 SG_ Ping_Bid m5 : 40|16@1+ (1,0) [0|0] "" HMDH_202
 SG_ Ping_Mid m5 : 56|16@1+ (1,0) [0|0] "" HMDH_202
 SG_ Ping_VerMajor m5 : 72|8@1+ (1,0) [0|0] "" HMDH_202
 SG_ Ping_VerMinor m5 : 80|8@1+ (1,0) [0|0] "" HMDH_202
 SG_ Ping_VerPatch m5 : 88|8@1+ (1,0) [0|0] "" HMDH_202
 SG_ Ping_Name0 m5 : 96|8@1+ (1,0) [0|0] "" HMDH_202
 SG_ Ping_Name1 m5 : 104|8@1+ (1,0) [0|0] "" HMDH_202
 SG_ Ping_Name2 m5 : 112|8@1+ (1,0) [0|0] "" HMDH_202
 SG_ Ping_Name3 m5 : 120|8@1+ (1,0) [0|0] "" HMDH_202
 SG_ Ping_Name4 m5 : 128|8@1+ (1,0) [0|0] "" HMDH_202
 SG_ Ping_Name5 m5 : 136|8@1+ (1,0) [0|0] "" HMDH_202
 SG_ Ping_Name6 m5 : 144|8@1+ (1,0) [0|0] "" HMDH_202
 SG_ Ping_Name7 m5 : 152|8@1+ (1,0) [0|0] "" HMDH_202
 SG_ Ping_Name8 m5 : 160|8@1+ (1,0) [0|0] "" HMDH_202
 SG_ Ping_Name9 m5 : 168|8@1+ (1,0) [0|0] "" HMDH_202
 SG_ Ping_Name10 m5 : 176|8@1+ (1,0) [0|0] "" HMDH_202
 SG_ Ping_Name11 m5 : 184|8@1+ (1,0) [0|0] "" HMDH_202
 SG_ Ping_Name12 m5 : 192|8@1+ (1,0) [0|0] "" HMDH_202
 SG_ Ping_Name13 m5 : 200|8@1+ (1,0) [0|0] "" HMDH_202
 SG_ Ping_Name14 m5 : 208|8@1+ (1,0) [0|0] "" HMDH_202
 SG_ Ping_Name15 m5 : 216|8@1+ (1,0) [0|0] "" HMDH_202
 SG_ Ping_FmtVer m5 : 224|8@1+ (1,0) [0|0] "" HMDH_202
 SG_ Ping_GitRev m5 : 232|32@1+ (1,0) [0|0] "" HMDH_202
 SG_ Ping_FwCrc m5 : 264|16@1+ (1,0) [0|0] "" HMDH_202
 SG_ Ping_UptimeS m5 : 280|16@1+ (1,0) [0|0] "s" HMDH_202
 SG_ Ecat_CanId m31 : 8|8@1+ (1,0) [0|0] "" HMDH_202
 SG_ Ecat_Name0 m31 : 16|8@1+ (1,0) [0|0] "" HMDH_202
 SG_ Ecat_Name1 m31 : 24|8@1+ (1,0) [0|0] "" HMDH_202
 SG_ Ecat_Name2 m31 : 32|8@1+ (1,0) [0|0] "" HMDH_202
 SG_ Ecat_Name3 m31 : 40|8@1+ (1,0) [0|0] "" HMDH_202
 SG_ Ecat_Name4 m31 : 48|8@1+ (1,0) [0|0] "" HMDH_202
 SG_ Ecat_Name5 m31 : 56|8@1+ (1,0) [0|0] "" HMDH_202
 SG_ Ecat_Name6 m31 : 64|8@1+ (1,0) [0|0] "" HMDH_202
 SG_ Ecat_Name7 m31 : 72|8@1+ (1,0) [0|0] "" HMDH_202
 SG_ Ecat_Name8 m31 : 80|8@1+ (1,0) [0|0] "" HMDH_202
 SG_ Ecat_Name9 m31 : 88|8@1+ (1,0) [0|0] "" HMDH_202
 SG_ Ecat_Name10 m31 : 96|8@1+ (1,0) [0|0] "" HMDH_202
 SG_ Ecat_Name11 m31 : 104|8@1+ (1,0) [0|0] "" HMDH_202
 SG_ Ecat_Name12 m31 : 112|8@1+ (1,0) [0|0] "" HMDH_202
 SG_ Ecat_Name13 m31 : 120|8@1+ (1,0) [0|0] "" HMDH_202
 SG_ Ecat_Name14 m31 : 128|8@1+ (1,0) [0|0] "" HMDH_202
 SG_ Ecat_Name15 m31 : 136|8@1+ (1,0) [0|0] "" HMDH_202
 SG_ Ecat_Link m31 : 144|8@1+ (1,0) [0|0] "" HMDH_202
 SG_ Ecat_InvalidFrame0 m31 : 152|8@1+ (1,0) [0|0] "" HMDH_202
 SG_ Ecat_InvalidFrame1 m31 : 160|8@1+ (1,0) [0|0] "" HMDH_202
 SG_ Ecat_InvalidFrame2 m31 : 168|8@1+ (1,0) [0|0] "" HMDH_202
 SG_ Ecat_InvalidFrame3 m31 : 176|8@1+ (1,0) [0|0] "" HMDH_202
 SG_ Ecat_RxError0 m31 : 184|8@1+ (1,0) [0|0] "" HMDH_202
 SG_ Ecat_RxError1 m31 : 192|8@1+ (1,0) [0|0] "" HMDH_202
 SG_ Ecat_RxError2 m31 : 200|8@1+ (1,0) [0|0] "" HMDH_202
 SG_ Ecat_RxError3 m31 : 208|8@1+ (1,0) [0|0] "" HMDH_202
 SG_ Ecat_FwdRxError0 m31 : 216|8@1+ (1,0) [0|0] "" HMDH_202
 SG_ Ecat_FwdRxError1 m31 : 224|8@1+ (1,0) [0|0] "" HMDH_202
 SG_ Ecat_FwdRxError2 m31 : 232|8@1+ (1,0) [0|0] "" HMDH_202
 SG_ Ecat_FwdRxError3 m31 : 240|8@1+ (1,0) [0|0] "" HMDH_202
 SG_ Ecat_PuError m31 : 248|8@1+ (1,0) [0|0] "" HMDH_202
 SG_ Ecat_PdiError m31 : 256|8@1+ (1,0) [0|0] "" HMDH_202
 SG_ Ecat_LostLink0 m31 : 264|8@1+ (1,0) [0|0] "" HMDH_202
 SG_ Ecat_LostLink1 m31 : 272|8@1+ (1,0) [0|0] "" HMDH_202
 SG_ Ecat_LostLink2 m31 : 280|8@1+ (1,0) [0|0] "" HMDH_202
 SG_ Ecat_LostLink3 m31 : 288|8@1+ (1,0) [0|0] "" HMDH_202
 SG_ Saf_CanId m32 : 8|8@1+ (1,0) [0|0] "" HMDH_202
 SG_ Saf_Name0 m32 : 16|8@1+ (1,0) [0|0] "" HMDH_202
 SG_ Saf_Name1 m32 : 24|8@1+ (1,0) [0|0] "" HMDH_202
 SG_ Saf_Name2 m32 : 32|8@1+ (1,0) [0|0] "" HMDH_202
 SG_ Saf_Name3 m32 : 40|8@1+ (1,0) [0|0] "" HMDH_202
 SG_ Saf_Name4 m32 : 48|8@1+ (1,0) [0|0] "" HMDH_202
 SG_ Saf_Name5 m32 : 56|8@1+ (1,0) [0|0] "" HMDH_202
 SG_ Saf_Name6 m32 : 64|8@1+ (1,0) [0|0] "" HMDH_202
 SG_ Saf_Name7 m32 : 72|8@1+ (1,0) [0|0] "" HMDH_202
 SG_ Saf_Name8 m32 : 80|8@1+ (1,0) [0|0] "" HMDH_202
 SG_ Saf_Name9 m32 : 88|8@1+ (1,0) [0|0] "" HMDH_202
 SG_ Saf_Name10 m32 : 96|8@1+ (1,0) [0|0] "" HMDH_202
 SG_ Saf_Name11 m32 : 104|8@1+ (1,0) [0|0] "" HMDH_202
 SG_ Saf_Name12 m32 : 112|8@1+ (1,0) [0|0] "" HMDH_202
 SG_ Saf_Name13 m32 : 120|8@1+ (1,0) [0|0] "" HMDH_202
 SG_ Saf_Name14 m32 : 128|8@1+ (1,0) [0|0] "" HMDH_202
 SG_ Saf_Name15 m32 : 136|8@1+ (1,0) [0|0] "" HMDH_202
 SG_ Saf_State m32 : 144|8@1+ (1,0) [0|0] "" HMDH_202
 SG_ Saf_Bits m32 : 152|16@1+ (1,0) [0|0] "" HMDH_202
 SG_ Saf_Estop m32 : 168|8@1+ (1,0) [0|0] "" HMDH_202
 SG_ Saf_FatalLatched m32 : 176|16@1+ (1,0) [0|0] "" HMDH_202
 SG_ Saf_ErrCode m32 : 192|32@1+ (1,0) [0|0] "" HMDH_202

BO_ 2163303627 STATUS_HETC_M_MOB_to_HMDH_203: 48 HETC_M_MOB
 SG_ SubCode M : 0|8@1+ (1,0) [0|0] "" HMDH_203
 SG_ Ping_CanId m5 : 8|8@1+ (1,0) [0|0] "" HMDH_203
 SG_ Ping_HostId m5 : 16|8@1+ (1,0) [0|0] "" HMDH_203
 SG_ Ping_Pid m5 : 24|16@1+ (1,0) [0|0] "" HMDH_203
 SG_ Ping_Bid m5 : 40|16@1+ (1,0) [0|0] "" HMDH_203
 SG_ Ping_Mid m5 : 56|16@1+ (1,0) [0|0] "" HMDH_203
 SG_ Ping_VerMajor m5 : 72|8@1+ (1,0) [0|0] "" HMDH_203
 SG_ Ping_VerMinor m5 : 80|8@1+ (1,0) [0|0] "" HMDH_203
 SG_ Ping_VerPatch m5 : 88|8@1+ (1,0) [0|0] "" HMDH_203
 SG_ Ping_Name0 m5 : 96|8@1+ (1,0) [0|0] "" HMDH_203
 SG_ Ping_Name1 m5 : 104|8@1+ (1,0) [0|0] "" HMDH_203
 SG_ Ping_Name2 m5 : 112|8@1+ (1,0) [0|0] "" HMDH_203
 SG_ Ping_Name3 m5 : 120|8@1+ (1,0) [0|0] "" HMDH_203
 SG_ Ping_Name4 m5 : 128|8@1+ (1,0) [0|0] "" HMDH_203
 SG_ Ping_Name5 m5 : 136|8@1+ (1,0) [0|0] "" HMDH_203
 SG_ Ping_Name6 m5 : 144|8@1+ (1,0) [0|0] "" HMDH_203
 SG_ Ping_Name7 m5 : 152|8@1+ (1,0) [0|0] "" HMDH_203
 SG_ Ping_Name8 m5 : 160|8@1+ (1,0) [0|0] "" HMDH_203
 SG_ Ping_Name9 m5 : 168|8@1+ (1,0) [0|0] "" HMDH_203
 SG_ Ping_Name10 m5 : 176|8@1+ (1,0) [0|0] "" HMDH_203
 SG_ Ping_Name11 m5 : 184|8@1+ (1,0) [0|0] "" HMDH_203
 SG_ Ping_Name12 m5 : 192|8@1+ (1,0) [0|0] "" HMDH_203
 SG_ Ping_Name13 m5 : 200|8@1+ (1,0) [0|0] "" HMDH_203
 SG_ Ping_Name14 m5 : 208|8@1+ (1,0) [0|0] "" HMDH_203
 SG_ Ping_Name15 m5 : 216|8@1+ (1,0) [0|0] "" HMDH_203
 SG_ Ping_FmtVer m5 : 224|8@1+ (1,0) [0|0] "" HMDH_203
 SG_ Ping_GitRev m5 : 232|32@1+ (1,0) [0|0] "" HMDH_203
 SG_ Ping_FwCrc m5 : 264|16@1+ (1,0) [0|0] "" HMDH_203
 SG_ Ping_UptimeS m5 : 280|16@1+ (1,0) [0|0] "s" HMDH_203
 SG_ Ecat_CanId m31 : 8|8@1+ (1,0) [0|0] "" HMDH_203
 SG_ Ecat_Name0 m31 : 16|8@1+ (1,0) [0|0] "" HMDH_203
 SG_ Ecat_Name1 m31 : 24|8@1+ (1,0) [0|0] "" HMDH_203
 SG_ Ecat_Name2 m31 : 32|8@1+ (1,0) [0|0] "" HMDH_203
 SG_ Ecat_Name3 m31 : 40|8@1+ (1,0) [0|0] "" HMDH_203
 SG_ Ecat_Name4 m31 : 48|8@1+ (1,0) [0|0] "" HMDH_203
 SG_ Ecat_Name5 m31 : 56|8@1+ (1,0) [0|0] "" HMDH_203
 SG_ Ecat_Name6 m31 : 64|8@1+ (1,0) [0|0] "" HMDH_203
 SG_ Ecat_Name7 m31 : 72|8@1+ (1,0) [0|0] "" HMDH_203
 SG_ Ecat_Name8 m31 : 80|8@1+ (1,0) [0|0] "" HMDH_203
 SG_ Ecat_Name9 m31 : 88|8@1+ (1,0) [0|0] "" HMDH_203
 SG_ Ecat_Name10 m31 : 96|8@1+ (1,0) [0|0] "" HMDH_203
 SG_ Ecat_Name11 m31 : 104|8@1+ (1,0) [0|0] "" HMDH_203
 SG_ Ecat_Name12 m31 : 112|8@1+ (1,0) [0|0] "" HMDH_203
 SG_ Ecat_Name13 m31 : 120|8@1+ (1,0) [0|0] "" HMDH_203
 SG_ Ecat_Name14 m31 : 128|8@1+ (1,0) [0|0] "" HMDH_203
 SG_ Ecat_Name15 m31 : 136|8@1+ (1,0) [0|0] "" HMDH_203
 SG_ Ecat_Link m31 : 144|8@1+ (1,0) [0|0] "" HMDH_203
 SG_ Ecat_InvalidFrame0 m31 : 152|8@1+ (1,0) [0|0] "" HMDH_203
 SG_ Ecat_InvalidFrame1 m31 : 160|8@1+ (1,0) [0|0] "" HMDH_203
 SG_ Ecat_InvalidFrame2 m31 : 168|8@1+ (1,0) [0|0] "" HMDH_203
 SG_ Ecat_InvalidFrame3 m31 : 176|8@1+ (1,0) [0|0] "" HMDH_203
 SG_ Ecat_RxError0 m31 : 184|8@1+ (1,0) [0|0] "" HMDH_203
 SG_ Ecat_RxError1 m31 : 192|8@1+ (1,0) [0|0] "" HMDH_203
 SG_ Ecat_RxError2 m31 : 200|8@1+ (1,0) [0|0] "" HMDH_203
 SG_ Ecat_RxError3 m31 : 208|8@1+ (1,0) [0|0] "" HMDH_203
 SG_ Ecat_FwdRxError0 m31 : 216|8@1+ (1,0) [0|0] "" HMDH_203
 SG_ Ecat_FwdRxError1 m31 : 224|8@1+ (1,0) [0|0] "" HMDH_203
 SG_ Ecat_FwdRxError2 m31 : 232|8@1+ (1,0) [0|0] "" HMDH_203
 SG_ Ecat_FwdRxError3 m31 : 240|8@1+ (1,0) [0|0] "" HMDH_203
 SG_ Ecat_PuError m31 : 248|8@1+ (1,0) [0|0] "" HMDH_203
 SG_ Ecat_PdiError m31 : 256|8@1+ (1,0) [0|0] "" HMDH_203
 SG_ Ecat_LostLink0 m31 : 264|8@1+ (1,0) [0|0] "" HMDH_203
 SG_ Ecat_LostLink1 m31 : 272|8@1+ (1,0) [0|0] "" HMDH_203
 SG_ Ecat_LostLink2 m31 : 280|8@1+ (1,0) [0|0] "" HMDH_203
 SG_ Ecat_LostLink3 m31 : 288|8@1+ (1,0) [0|0] "" HMDH_203
 SG_ Saf_CanId m32 : 8|8@1+ (1,0) [0|0] "" HMDH_203
 SG_ Saf_Name0 m32 : 16|8@1+ (1,0) [0|0] "" HMDH_203
 SG_ Saf_Name1 m32 : 24|8@1+ (1,0) [0|0] "" HMDH_203
 SG_ Saf_Name2 m32 : 32|8@1+ (1,0) [0|0] "" HMDH_203
 SG_ Saf_Name3 m32 : 40|8@1+ (1,0) [0|0] "" HMDH_203
 SG_ Saf_Name4 m32 : 48|8@1+ (1,0) [0|0] "" HMDH_203
 SG_ Saf_Name5 m32 : 56|8@1+ (1,0) [0|0] "" HMDH_203
 SG_ Saf_Name6 m32 : 64|8@1+ (1,0) [0|0] "" HMDH_203
 SG_ Saf_Name7 m32 : 72|8@1+ (1,0) [0|0] "" HMDH_203
 SG_ Saf_Name8 m32 : 80|8@1+ (1,0) [0|0] "" HMDH_203
 SG_ Saf_Name9 m32 : 88|8@1+ (1,0) [0|0] "" HMDH_203
 SG_ Saf_Name10 m32 : 96|8@1+ (1,0) [0|0] "" HMDH_203
 SG_ Saf_Name11 m32 : 104|8@1+ (1,0) [0|0] "" HMDH_203
 SG_ Saf_Name12 m32 : 112|8@1+ (1,0) [0|0] "" HMDH_203
 SG_ Saf_Name13 m32 : 120|8@1+ (1,0) [0|0] "" HMDH_203
 SG_ Saf_Name14 m32 : 128|8@1+ (1,0) [0|0] "" HMDH_203
 SG_ Saf_Name15 m32 : 136|8@1+ (1,0) [0|0] "" HMDH_203
 SG_ Saf_State m32 : 144|8@1+ (1,0) [0|0] "" HMDH_203
 SG_ Saf_Bits m32 : 152|16@1+ (1,0) [0|0] "" HMDH_203
 SG_ Saf_Estop m32 : 168|8@1+ (1,0) [0|0] "" HMDH_203
 SG_ Saf_FatalLatched m32 : 176|16@1+ (1,0) [0|0] "" HMDH_203
 SG_ Saf_ErrCode m32 : 192|32@1+ (1,0) [0|0] "" HMDH_203

BO_ 2163303628 STATUS_HETC_M_MOB_to_HMDH_204: 48 HETC_M_MOB
 SG_ SubCode M : 0|8@1+ (1,0) [0|0] "" HMDH_204
 SG_ Ping_CanId m5 : 8|8@1+ (1,0) [0|0] "" HMDH_204
 SG_ Ping_HostId m5 : 16|8@1+ (1,0) [0|0] "" HMDH_204
 SG_ Ping_Pid m5 : 24|16@1+ (1,0) [0|0] "" HMDH_204
 SG_ Ping_Bid m5 : 40|16@1+ (1,0) [0|0] "" HMDH_204
 SG_ Ping_Mid m5 : 56|16@1+ (1,0) [0|0] "" HMDH_204
 SG_ Ping_VerMajor m5 : 72|8@1+ (1,0) [0|0] "" HMDH_204
 SG_ Ping_VerMinor m5 : 80|8@1+ (1,0) [0|0] "" HMDH_204
 SG_ Ping_VerPatch m5 : 88|8@1+ (1,0) [0|0] "" HMDH_204
 SG_ Ping_Name0 m5 : 96|8@1+ (1,0) [0|0] "" HMDH_204
 SG_ Ping_Name1 m5 : 104|8@1+ (1,0) [0|0] "" HMDH_204
 SG_ Ping_Name2 m5 : 112|8@1+ (1,0) [0|0] "" HMDH_204
 SG_ Ping_Name3 m5 : 120|8@1+ (1,0) [0|0] "" HMDH_204
 SG_ Ping_Name4 m5 : 128|8@1+ (1,0) [0|0] "" HMDH_204
 SG_ Ping_Name5 m5 : 136|8@1+ (1,0) [0|0] "" HMDH_204
 SG_ Ping_Name6 m5 : 144|8@1+ (1,0) [0|0] "" HMDH_204
 SG_ Ping_Name7 m5 : 152|8@1+ (1,0) [0|0] "" HMDH_204
 SG_ Ping_Name8 m5 : 160|8@1+ (1,0) [0|0] "" HMDH_204
 SG_ Ping_Name9 m5 : 168|8@1+ (1,0) [0|0] "" HMDH_204
 SG_ Ping_Name10 m5 : 176|8@1+ (1,0) [0|0] "" HMDH_204
 SG_ Ping_Name11 m5 : 184|8@1+ (1,0) [0|0] "" HMDH_204
 SG_ Ping_Name12 m5 : 192|8@1+ (1,0) [0|0] "" HMDH_204
 SG_ Ping_Name13 m5 : 200|8@1+ (1,0) [0|0] "" HMDH_204
 SG_ Ping_Name14 m5 : 208|8@1+ (1,0) [0|0] "" HMDH_204
 SG_ Ping_Name15 m5 : 216|8@1+ (1,0) [0|0] "" HMDH_204
 SG_ Ping_FmtVer m5 : 224|8@1+ (1,0) [0|0] "" HMDH_204
 SG_ Ping_GitRev m5 : 232|32@1+ (1,0) [0|0] "" HMDH_204
 SG_ Ping_FwCrc m5 : 264|16@1+ (1,0) [0|0] "" HMDH_204
 SG_ Ping_UptimeS m5 : 280|16@1+ (1,0) [0|0] "s" HMDH_204
 SG_ Ecat_CanId m31 : 8|8@1+ (1,0) [0|0] "" HMDH_204
 SG_ Ecat_Name0 m31 : 16|8@1+ (1,0) [0|0] "" HMDH_204
 SG_ Ecat_Name1 m31 : 24|8@1+ (1,0) [0|0] "" HMDH_204
 SG_ Ecat_Name2 m31 : 32|8@1+ (1,0) [0|0] "" HMDH_204
 SG_ Ecat_Name3 m31 : 40|8@1+ (1,0) [0|0] "" HMDH_204
 SG_ Ecat_Name4 m31 : 48|8@1+ (1,0) [0|0] "" HMDH_204
 SG_ Ecat_Name5 m31 : 56|8@1+ (1,0) [0|0] "" HMDH_204
 SG_ Ecat_Name6 m31 : 64|8@1+ (1,0) [0|0] "" HMDH_204
 SG_ Ecat_Name7 m31 : 72|8@1+ (1,0) [0|0] "" HMDH_204
 SG_ Ecat_Name8 m31 : 80|8@1+ (1,0) [0|0] "" HMDH_204
 SG_ Ecat_Name9 m31 : 88|8@1+ (1,0) [0|0] "" HMDH_204
 SG_ Ecat_Name10 m31 : 96|8@1+ (1,0) [0|0] "" HMDH_204
 SG_ Ecat_Name11 m31 : 104|8@1+ (1,0) [0|0] "" HMDH_204
 SG_ Ecat_Name12 m31 : 112|8@1+ (1,0) [0|0] "" HMDH_204
 SG_ Ecat_Name13 m31 : 120|8@1+ (1,0) [0|0] "" HMDH_204
 SG_ Ecat_Name14 m31 : 128|8@1+ (1,0) [0|0] "" HMDH_204
 SG_ Ecat_Name15 m31 : 136|8@1+ (1,0) [0|0] "" HMDH_204
 SG_ Ecat_Link m31 : 144|8@1+ (1,0) [0|0] "" HMDH_204
 SG_ Ecat_InvalidFrame0 m31 : 152|8@1+ (1,0) [0|0] "" HMDH_204
 SG_ Ecat_InvalidFrame1 m31 : 160|8@1+ (1,0) [0|0] "" HMDH_204
 SG_ Ecat_InvalidFrame2 m31 : 168|8@1+ (1,0) [0|0] "" HMDH_204
 SG_ Ecat_InvalidFrame3 m31 : 176|8@1+ (1,0) [0|0] "" HMDH_204
 SG_ Ecat_RxError0 m31 : 184|8@1+ (1,0) [0|0] "" HMDH_204
 SG_ Ecat_RxError1 m31 : 192|8@1+ (1,0) [0|0] "" HMDH_204
 SG_ Ecat_RxError2 m31 : 200|8@1+ (1,0) [0|0] "" HMDH_204
 SG_ Ecat_RxError3 m31 : 208|8@1+ (1,0) [0|0] "" HMDH_204
 SG_ Ecat_FwdRxError0 m31 : 216|8@1+ (1,0) [0|0] "" HMDH_204
 SG_ Ecat_FwdRxError1 m31 : 224|8@1+ (1,0) [0|0] "" HMDH_204
 SG_ Ecat_FwdRxError2 m31 : 232|8@1+ (1,0) [0|0] "" HMDH_204
 SG_ Ecat_FwdRxError3 m31 : 240|8@1+ (1,0) [0|0] "" HMDH_204
 SG_ Ecat_PuError m31 : 248|8@1+ (1,0) [0|0] "" HMDH_204
 SG_ Ecat_PdiError m31 : 256|8@1+ (1,0) [0|0] "" HMDH_204
 SG_ Ecat_LostLink0 m31 : 264|8@1+ (1,0) [0|0] "" HMDH_204
 SG_ Ecat_LostLink1 m31 : 272|8@1+ (1,0) [0|0] "" HMDH_204
 SG_ Ecat_LostLink2 m31 : 280|8@1+ (1,0) [0|0] "" HMDH_204
 SG_ Ecat_LostLink3 m31 : 288|8@1+ (1,0) [0|0] "" HMDH_204
 SG_ Saf_CanId m32 : 8|8@1+ (1,0) [0|0] "" HMDH_204
 SG_ Saf_Name0 m32 : 16|8@1+ (1,0) [0|0] "" HMDH_204
 SG_ Saf_Name1 m32 : 24|8@1+ (1,0) [0|0] "" HMDH_204
 SG_ Saf_Name2 m32 : 32|8@1+ (1,0) [0|0] "" HMDH_204
 SG_ Saf_Name3 m32 : 40|8@1+ (1,0) [0|0] "" HMDH_204
 SG_ Saf_Name4 m32 : 48|8@1+ (1,0) [0|0] "" HMDH_204
 SG_ Saf_Name5 m32 : 56|8@1+ (1,0) [0|0] "" HMDH_204
 SG_ Saf_Name6 m32 : 64|8@1+ (1,0) [0|0] "" HMDH_204
 SG_ Saf_Name7 m32 : 72|8@1+ (1,0) [0|0] "" HMDH_204
 SG_ Saf_Name8 m32 : 80|8@1+ (1,0) [0|0] "" HMDH_204
 SG_ Saf_Name9 m32 : 88|8@1+ (1,0) [0|0] "" HMDH_204
 SG_ Saf_Name10 m32 : 96|8@1+ (1,0) [0|0] "" HMDH_204
 SG_ Saf_Name11 m32 : 104|8@1+ (1,0) [0|0] "" HMDH_204
 SG_ Saf_Name12 m32 : 112|8@1+ (1,0) [0|0] "" HMDH_204
 SG_ Saf_Name13 m32 : 120|8@1+ (1,0) [0|0] "" HMDH_204
 SG_ Saf_Name14 m32 : 128|8@1+ (1,0) [0|0] "" HMDH_204
 SG_ Saf_Name15 m32 : 136|8@1+ (1,0) [0|0] "" HMDH_204
 SG_ Saf_State m32 : 144|8@1+ (1,0) [0|0] "" HMDH_204
 SG_ Saf_Bits m32 : 152|16@1+ (1,0) [0|0] "" HMDH_204
 SG_ Saf_Estop m32 : 168|8@1+ (1,0) [0|0] "" HMDH_204
 SG_ Saf_FatalLatched m32 : 176|16@1+ (1,0) [0|0] "" HMDH_204
 SG_ Saf_ErrCode m32 : 192|32@1+ (1,0) [0|0] "" HMDH_204

BO_ 2163303629 STATUS_HETC_M_MOB_to_HMDH_205: 48 HETC_M_MOB
 SG_ SubCode M : 0|8@1+ (1,0) [0|0] "" HMDH_205
 SG_ Ping_CanId m5 : 8|8@1+ (1,0) [0|0] "" HMDH_205
 SG_ Ping_HostId m5 : 16|8@1+ (1,0) [0|0] "" HMDH_205
 SG_ Ping_Pid m5 : 24|16@1+ (1,0) [0|0] "" HMDH_205
 SG_ Ping_Bid m5 : 40|16@1+ (1,0) [0|0] "" HMDH_205
 SG_ Ping_Mid m5 : 56|16@1+ (1,0) [0|0] "" HMDH_205
 SG_ Ping_VerMajor m5 : 72|8@1+ (1,0) [0|0] "" HMDH_205
 SG_ Ping_VerMinor m5 : 80|8@1+ (1,0) [0|0] "" HMDH_205
 SG_ Ping_VerPatch m5 : 88|8@1+ (1,0) [0|0] "" HMDH_205
 SG_ Ping_Name0 m5 : 96|8@1+ (1,0) [0|0] "" HMDH_205
 SG_ Ping_Name1 m5 : 104|8@1+ (1,0) [0|0] "" HMDH_205
 SG_ Ping_Name2 m5 : 112|8@1+ (1,0) [0|0] "" HMDH_205
 SG_ Ping_Name3 m5 : 120|8@1+ (1,0) [0|0] "" HMDH_205
 SG_ Ping_Name4 m5 : 128|8@1+ (1,0) [0|0] "" HMDH_205
 SG_ Ping_Name5 m5 : 136|8@1+ (1,0) [0|0] "" HMDH_205
 SG_ Ping_Name6 m5 : 144|8@1+ (1,0) [0|0] "" HMDH_205
 SG_ Ping_Name7 m5 : 152|8@1+ (1,0) [0|0] "" HMDH_205
 SG_ Ping_Name8 m5 : 160|8@1+ (1,0) [0|0] "" HMDH_205
 SG_ Ping_Name9 m5 : 168|8@1+ (1,0) [0|0] "" HMDH_205
 SG_ Ping_Name10 m5 : 176|8@1+ (1,0) [0|0] "" HMDH_205
 SG_ Ping_Name11 m5 : 184|8@1+ (1,0) [0|0] "" HMDH_205
 SG_ Ping_Name12 m5 : 192|8@1+ (1,0) [0|0] "" HMDH_205
 SG_ Ping_Name13 m5 : 200|8@1+ (1,0) [0|0] "" HMDH_205
 SG_ Ping_Name14 m5 : 208|8@1+ (1,0) [0|0] "" HMDH_205
 SG_ Ping_Name15 m5 : 216|8@1+ (1,0) [0|0] "" HMDH_205
 SG_ Ping_FmtVer m5 : 224|8@1+ (1,0) [0|0] "" HMDH_205
 SG_ Ping_GitRev m5 : 232|32@1+ (1,0) [0|0] "" HMDH_205
 SG_ Ping_FwCrc m5 : 264|16@1+ (1,0) [0|0] "" HMDH_205
 SG_ Ping_UptimeS m5 : 280|16@1+ (1,0) [0|0] "s" HMDH_205
 SG_ Ecat_CanId m31 : 8|8@1+ (1,0) [0|0] "" HMDH_205
 SG_ Ecat_Name0 m31 : 16|8@1+ (1,0) [0|0] "" HMDH_205
 SG_ Ecat_Name1 m31 : 24|8@1+ (1,0) [0|0] "" HMDH_205
 SG_ Ecat_Name2 m31 : 32|8@1+ (1,0) [0|0] "" HMDH_205
 SG_ Ecat_Name3 m31 : 40|8@1+ (1,0) [0|0] "" HMDH_205
 SG_ Ecat_Name4 m31 : 48|8@1+ (1,0) [0|0] "" HMDH_205
 SG_ Ecat_Name5 m31 : 56|8@1+ (1,0) [0|0] "" HMDH_205
 SG_ Ecat_Name6 m31 : 64|8@1+ (1,0) [0|0] "" HMDH_205
 SG_ Ecat_Name7 m31 : 72|8@1+ (1,0) [0|0] "" HMDH_205
 SG_ Ecat_Name8 m31 : 80|8@1+ (1,0) [0|0] "" HMDH_205
 SG_ Ecat_Name9 m31 : 88|8@1+ (1,0) [0|0] "" HMDH_205
 SG_ Ecat_Name10 m31 : 96|8@1+ (1,0) [0|0] "" HMDH_205
 SG_ Ecat_Name11 m31 : 104|8@1+ (1,0) [0|0] "" HMDH_205
 SG_ Ecat_Name12 m31 : 112|8@1+ (1,0) [0|0] "" HMDH_205
 SG_ Ecat_Name13 m31 : 120|8@1+ (1,0) [0|0] "" HMDH_205
 SG_ Ecat_Name14 m31 : 128|8@1+ (1,0) [0|0] "" HMDH_205
 SG_ Ecat_Name15 m31 : 136|8@1+ (1,0) [0|0] "" HMDH_205
 SG_ Ecat_Link m31 : 144|8@1+ (1,0) [0|0] "" HMDH_205
 SG_ Ecat_InvalidFrame0 m31 : 152|8@1+ (1,0) [0|0] "" HMDH_205
 SG_ Ecat_InvalidFrame1 m31 : 160|8@1+ (1,0) [0|0] "" HMDH_205
 SG_ Ecat_InvalidFrame2 m31 : 168|8@1+ (1,0) [0|0] "" HMDH_205
 SG_ Ecat_InvalidFrame3 m31 : 176|8@1+ (1,0) [0|0] "" HMDH_205
 SG_ Ecat_RxError0 m31 : 184|8@1+ (1,0) [0|0] "" HMDH_205
 SG_ Ecat_RxError1 m31 : 192|8@1+ (1,0) [0|0] "" HMDH_205
 SG_ Ecat_RxError2 m31 : 200|8@1+ (1,0) [0|0] "" HMDH_205
 SG_ Ecat_RxError3 m31 : 208|8@1+ (1,0) [0|0] "" HMDH_205
 SG_ Ecat_FwdRxError0 m31 : 216|8@1+ (1,0) [0|0] "" HMDH_205
 SG_ Ecat_FwdRxError1 m31 : 224|8@1+ (1,0) [0|0] "" HMDH_205
 SG_ Ecat_FwdRxError2 m31 : 232|8@1+ (1,0) [0|0] "" HMDH_205
 SG_ Ecat_FwdRxError3 m31 : 240|8@1+ (1,0) [0|0] "" HMDH_205
 SG_ Ecat_PuError m31 : 248|8@1+ (1,0) [0|0] "" HMDH_205
 SG_ Ecat_PdiError m31 : 256|8@1+ (1,0) [0|0] "" HMDH_205
 SG_ Ecat_LostLink0 m31 : 264|8@1+ (1,0) [0|0] "" HMDH_205
 SG_ Ecat_LostLink1 m31 : 272|8@1+ (1,0) [0|0] "" HMDH_205
 SG_ Ecat_LostLink2 m31 : 280|8@1+ (1,0) [0|0] "" HMDH_205
 SG_ Ecat_LostLink3 m31 : 288|8@1+ (1,0) [0|0] "" HMDH_205
 SG_ Saf_CanId m32 : 8|8@1+ (1,0) [0|0] "" HMDH_205
 SG_ Saf_Name0 m32 : 16|8@1+ (1,0) [0|0] "" HMDH_205
 SG_ Saf_Name1 m32 : 24|8@1+ (1,0) [0|0] "" HMDH_205
 SG_ Saf_Name2 m32 : 32|8@1+ (1,0) [0|0] "" HMDH_205
 SG_ Saf_Name3 m32 : 40|8@1+ (1,0) [0|0] "" HMDH_205
 SG_ Saf_Name4 m32 : 48|8@1+ (1,0) [0|0] "" HMDH_205
 SG_ Saf_Name5 m32 : 56|8@1+ (1,0) [0|0] "" HMDH_205
 SG_ Saf_Name6 m32 : 64|8@1+ (1,0) [0|0] "" HMDH_205
 SG_ Saf_Name7 m32 : 72|8@1+ (1,0) [0|0] "" HMDH_205
 SG_ Saf_Name8 m32 : 80|8@1+ (1,0) [0|0] "" HMDH_205
 SG_ Saf_Name9 m32 : 88|8@1+ (1,0) [0|0] "" HMDH_205
 SG_ Saf_Name10 m32 : 96|8@1+ (1,0) [0|0] "" HMDH_205
 SG_ Saf_Name11 m32 : 104|8@1+ (1,0) [0|0] "" HMDH_205
 SG_ Saf_Name12 m32 : 112|8@1+ (1,0) [0|0] "" HMDH_205
 SG_ Saf_Name13 m32 : 120|8@1+ (1,0) [0|0] "" HMDH_205
 SG_ Saf_Name14 m32 : 128|8@1+ (1,0) [0|0] "" HMDH_205
 SG_ Saf_Name15 m32 : 136|8@1+ (1,0) [0|0] "" HMDH_205
 SG_ Saf_State m32 : 144|8@1+ (1,0) [0|0] "" HMDH_205
 SG_ Saf_Bits m32 : 152|16@1+ (1,0) [0|0] "" HMDH_205
 SG_ Saf_Estop m32 : 168|8@1+ (1,0) [0|0] "" HMDH_205
 SG_ Saf_FatalLatched m32 : 176|16@1+ (1,0) [0|0] "" HMDH_205
 SG_ Saf_ErrCode m32 : 192|32@1+ (1,0) [0|0] "" HMDH_205

BO_ 2163303630 STATUS_HETC_M_MOB_to_HMDH_206: 48 HETC_M_MOB
 SG_ SubCode M : 0|8@1+ (1,0) [0|0] "" HMDH_206
 SG_ Ping_CanId m5 : 8|8@1+ (1,0) [0|0] "" HMDH_206
 SG_ Ping_HostId m5 : 16|8@1+ (1,0) [0|0] "" HMDH_206
 SG_ Ping_Pid m5 : 24|16@1+ (1,0) [0|0] "" HMDH_206
 SG_ Ping_Bid m5 : 40|16@1+ (1,0) [0|0] "" HMDH_206
 SG_ Ping_Mid m5 : 56|16@1+ (1,0) [0|0] "" HMDH_206
 SG_ Ping_VerMajor m5 : 72|8@1+ (1,0) [0|0] "" HMDH_206
 SG_ Ping_VerMinor m5 : 80|8@1+ (1,0) [0|0] "" HMDH_206
 SG_ Ping_VerPatch m5 : 88|8@1+ (1,0) [0|0] "" HMDH_206
 SG_ Ping_Name0 m5 : 96|8@1+ (1,0) [0|0] "" HMDH_206
 SG_ Ping_Name1 m5 : 104|8@1+ (1,0) [0|0] "" HMDH_206
 SG_ Ping_Name2 m5 : 112|8@1+ (1,0) [0|0] "" HMDH_206
 SG_ Ping_Name3 m5 : 120|8@1+ (1,0) [0|0] "" HMDH_206
 SG_ Ping_Name4 m5 : 128|8@1+ (1,0) [0|0] "" HMDH_206
 SG_ Ping_Name5 m5 : 136|8@1+ (1,0) [0|0] "" HMDH_206
 SG_ Ping_Name6 m5 : 144|8@1+ (1,0) [0|0] "" HMDH_206
 SG_ Ping_Name7 m5 : 152|8@1+ (1,0) [0|0] "" HMDH_206
 SG_ Ping_Name8 m5 : 160|8@1+ (1,0) [0|0] "" HMDH_206
 SG_ Ping_Name9 m5 : 168|8@1+ (1,0) [0|0] "" HMDH_206
 SG_ Ping_Name10 m5 : 176|8@1+ (1,0) [0|0] "" HMDH_206
 SG_ Ping_Name11 m5 : 184|8@1+ (1,0) [0|0] "" HMDH_206
 SG_ Ping_Name12 m5 : 192|8@1+ (1,0) [0|0] "" HMDH_206
 SG_ Ping_Name13 m5 : 200|8@1+ (1,0) [0|0] "" HMDH_206
 SG_ Ping_Name14 m5 : 208|8@1+ (1,0) [0|0] "" HMDH_206
 SG_ Ping_Name15 m5 : 216|8@1+ (1,0) [0|0] "" HMDH_206
 SG_ Ping_FmtVer m5 : 224|8@1+ (1,0) [0|0] "" HMDH_206
 SG_ Ping_GitRev m5 : 232|32@1+ (1,0) [0|0] "" HMDH_206
 SG_ Ping_FwCrc m5 : 264|16@1+ (1,0) [0|0] "" HMDH_206
 SG_ Ping_UptimeS m5 : 280|16@1+ (1,0) [0|0] "s" HMDH_206
 SG_ Ecat_CanId m31 : 8|8@1+ (1,0) [0|0] "" HMDH_206
 SG_ Ecat_Name0 m31 : 16|8@1+ (1,0) [0|0] "" HMDH_206
 SG_ Ecat_Name1 m31 : 24|8@1+ (1,0) [0|0] "" HMDH_206
 SG_ Ecat_Name2 m31 : 32|8@1+ (1,0) [0|0] "" HMDH_206
 SG_ Ecat_Name3 m31 : 40|8@1+ (1,0) [0|0] "" HMDH_206
 SG_ Ecat_Name4 m31 : 48|8@1+ (1,0) [0|0] "" HMDH_206
 SG_ Ecat_Name5 m31 : 56|8@1+ (1,0) [0|0] "" HMDH_206
 SG_ Ecat_Name6 m31 : 64|8@1+ (1,0) [0|0] "" HMDH_206
 SG_ Ecat_Name7 m31 : 72|8@1+ (1,0) [0|0] "" HMDH_206
 SG_ Ecat_Name8 m31 : 80|8@1+ (1,0) [0|0] "" HMDH_206
 SG_ Ecat_Name9 m31 : 88|8@1+ (1,0) [0|0] "" HMDH_206
 SG_ Ecat_Name10 m31 : 96|8@1+ (1,0) [0|0] "" HMDH_206
 SG_ Ecat_Name11 m31 : 104|8@1+ (1,0) [0|0] "" HMDH_206
 SG_ Ecat_Name12 m31 : 112|8@1+ (1,0) [0|0] "" HMDH_206
 SG_ Ecat_Name13 m31 : 120|8@1+ (1,0) [0|0] "" HMDH_206
 SG_ Ecat_Name14 m31 : 128|8@1+ (1,0) [0|0] "" HMDH_206
 SG_ Ecat_Name15 m31 : 136|8@1+ (1,0) [0|0] "" HMDH_206
 SG_ Ecat_Link m31 : 144|8@1+ (1,0) [0|0] "" HMDH_206
 SG_ Ecat_InvalidFrame0 m31 : 152|8@1+ (1,0) [0|0] "" HMDH_206
 SG_ Ecat_InvalidFrame1 m31 : 160|8@1+ (1,0) [0|0] "" HMDH_206
 SG_ Ecat_InvalidFrame2 m31 : 168|8@1+ (1,0) [0|0] "" HMDH_206
 SG_ Ecat_InvalidFrame3 m31 : 176|8@1+ (1,0) [0|0] "" HMDH_206
 SG_ Ecat_RxError0 m31 : 184|8@1+ (1,0) [0|0] "" HMDH_206
 SG_ Ecat_RxError1 m31 : 192|8@1+ (1,0) [0|0] "" HMDH_206
 SG_ Ecat_RxError2 m31 : 200|8@1+ (1,0) [0|0] "" HMDH_206
 SG_ Ecat_RxError3 m31 : 208|8@1+ (1,0) [0|0] "" HMDH_206
 SG_ Ecat_FwdRxError0 m31 : 216|8@1+ (1,0) [0|0] "" HMDH_206
 SG_ Ecat_FwdRxError1 m31 : 224|8@1+ (1,0) [0|0] "" HMDH_206
 SG_ Ecat_FwdRxError2 m31 : 232|8@1+ (1,0) [0|0] "" HMDH_206
 SG_ Ecat_FwdRxError3 m31 : 240|8@1+ (1,0) [0|0] "" HMDH_206
 SG_ Ecat_PuError m31 : 248|8@1+ (1,0) [0|0] "" HMDH_206
 SG_ Ecat_PdiError m31 : 256|8@1+ (1,0) [0|0] "" HMDH_206
 SG_ Ecat_LostLink0 m31 : 264|8@1+ (1,0) [0|0] "" HMDH_206
 SG_ Ecat_LostLink1 m31 : 272|8@1+ (1,0) [0|0] "" HMDH_206
 SG_ Ecat_LostLink2 m31 : 280|8@1+ (1,0) [0|0] "" HMDH_206
 SG_ Ecat_LostLink3 m31 : 288|8@1+ (1,0) [0|0] "" HMDH_206
 SG_ Saf_CanId m32 : 8|8@1+ (1,0) [0|0] "" HMDH_206
 SG_ Saf_Name0 m32 : 16|8@1+ (1,0) [0|0] "" HMDH_206
 SG_ Saf_Name1 m32 : 24|8@1+ (1,0) [0|0] "" HMDH_206
 SG_ Saf_Name2 m32 : 32|8@1+ (1,0) [0|0] "" HMDH_206
 SG_ Saf_Name3 m32 : 40|8@1+ (1,0) [0|0] "" HMDH_206
 SG_ Saf_Name4 m32 : 48|8@1+ (1,0) [0|0] "" HMDH_206
 SG_ Saf_Name5 m32 : 56|8@1+ (1,0) [0|0] "" HMDH_206
 SG_ Saf_Name6 m32 : 64|8@1+ (1,0) [0|0] "" HMDH_206
 SG_ Saf_Name7 m32 : 72|8@1+ (1,0) [0|0] "" HMDH_206
 SG_ Saf_Name8 m32 : 80|8@1+ (1,0) [0|0] "" HMDH_206
 SG_ Saf_Name9 m32 : 88|8@1+ (1,0) [0|0] "" HMDH_206
 SG_ Saf_Name10 m32 : 96|8@1+ (1,0) [0|0] "" HMDH_206
 SG_ Saf_Name11 m32 : 104|8@1+ (1,0) [0|0] "" HMDH_206
 SG_ Saf_Name12 m32 : 112|8@1+ (1,0) [0|0] "" HMDH_206
 SG_ Saf_Name13 m32 : 120|8@1+ (1,0) [0|0] "" HMDH_206
 SG_ Saf_Name14 m32 : 128|8@1+ (1,0) [0|0] "" HMDH_206
 SG_ Saf_Name15 m32 : 136|8@1+ (1,0) [0|0] "" HMDH_206
 SG_ Saf_State m32 : 144|8@1+ (1,0) [0|0] "" HMDH_206
 SG_ Saf_Bits m32 : 152|16@1+ (1,0) [0|0] "" HMDH_206
 SG_ Saf_Estop m32 : 168|8@1+ (1,0) [0|0] "" HMDH_206
 SG_ Saf_FatalLatched m32 : 176|16@1+ (1,0) [0|0] "" HMDH_206
 SG_ Saf_ErrCode m32 : 192|32@1+ (1,0) [0|0] "" HMDH_206

BO_ 2163303631 STATUS_HETC_M_MOB_to_HMDH_207: 48 HETC_M_MOB
 SG_ SubCode M : 0|8@1+ (1,0) [0|0] "" HMDH_207
 SG_ Ping_CanId m5 : 8|8@1+ (1,0) [0|0] "" HMDH_207
 SG_ Ping_HostId m5 : 16|8@1+ (1,0) [0|0] "" HMDH_207
 SG_ Ping_Pid m5 : 24|16@1+ (1,0) [0|0] "" HMDH_207
 SG_ Ping_Bid m5 : 40|16@1+ (1,0) [0|0] "" HMDH_207
 SG_ Ping_Mid m5 : 56|16@1+ (1,0) [0|0] "" HMDH_207
 SG_ Ping_VerMajor m5 : 72|8@1+ (1,0) [0|0] "" HMDH_207
 SG_ Ping_VerMinor m5 : 80|8@1+ (1,0) [0|0] "" HMDH_207
 SG_ Ping_VerPatch m5 : 88|8@1+ (1,0) [0|0] "" HMDH_207
 SG_ Ping_Name0 m5 : 96|8@1+ (1,0) [0|0] "" HMDH_207
 SG_ Ping_Name1 m5 : 104|8@1+ (1,0) [0|0] "" HMDH_207
 SG_ Ping_Name2 m5 : 112|8@1+ (1,0) [0|0] "" HMDH_207
 SG_ Ping_Name3 m5 : 120|8@1+ (1,0) [0|0] "" HMDH_207
 SG_ Ping_Name4 m5 : 128|8@1+ (1,0) [0|0] "" HMDH_207
 SG_ Ping_Name5 m5 : 136|8@1+ (1,0) [0|0] "" HMDH_207
 SG_ Ping_Name6 m5 : 144|8@1+ (1,0) [0|0] "" HMDH_207
 SG_ Ping_Name7 m5 : 152|8@1+ (1,0) [0|0] "" HMDH_207
 SG_ Ping_Name8 m5 : 160|8@1+ (1,0) [0|0] "" HMDH_207
 SG_ Ping_Name9 m5 : 168|8@1+ (1,0) [0|0] "" HMDH_207
 SG_ Ping_Name10 m5 : 176|8@1+ (1,0) [0|0] "" HMDH_207
 SG_ Ping_Name11 m5 : 184|8@1+ (1,0) [0|0] "" HMDH_207
 SG_ Ping_Name12 m5 : 192|8@1+ (1,0) [0|0] "" HMDH_207
 SG_ Ping_Name13 m5 : 200|8@1+ (1,0) [0|0] "" HMDH_207
 SG_ Ping_Name14 m5 : 208|8@1+ (1,0) [0|0] "" HMDH_207
 SG_ Ping_Name15 m5 : 216|8@1+ (1,0) [0|0] "" HMDH_207
 SG_ Ping_FmtVer m5 : 224|8@1+ (1,0) [0|0] "" HMDH_207
 SG_ Ping_GitRev m5 : 232|32@1+ (1,0) [0|0] "" HMDH_207
 SG_ Ping_FwCrc m5 : 264|16@1+ (1,0) [0|0] "" HMDH_207
 SG_ Ping_UptimeS m5 : 280|16@1+ (1,0) [0|0] "s" HMDH_207
 SG_ Ecat_CanId m31 : 8|8@1+ (1,0) [0|0] "" HMDH_207
 SG_ Ecat_Name0 m31 : 16|8@1+ (1,0) [0|0] "" HMDH_207
 SG_ Ecat_Name1 m31 : 24|8@1+ (1,0) [0|0] "" HMDH_207
 SG_ Ecat_Name2 m31 : 32|8@1+ (1,0) [0|0] "" HMDH_207
 SG_ Ecat_Name3 m31 : 40|8@1+ (1,0) [0|0] "" HMDH_207
 SG_ Ecat_Name4 m31 : 48|8@1+ (1,0) [0|0] "" HMDH_207
 SG_ Ecat_Name5 m31 : 56|8@1+ (1,0) [0|0] "" HMDH_207
 SG_ Ecat_Name6 m31 : 64|8@1+ (1,0) [0|0] "" HMDH_207
 SG_ Ecat_Name7 m31 : 72|8@1+ (1,0) [0|0] "" HMDH_207
 SG_ Ecat_Name8 m31 : 80|8@1+ (1,0) [0|0] "" HMDH_207
 SG_ Ecat_Name9 m31 : 88|8@1+ (1,0) [0|0] "" HMDH_207
 SG_ Ecat_Name10 m31 : 96|8@1+ (1,0) [0|0] "" HMDH_207
 SG_ Ecat_Name11 m31 : 104|8@1+ (1,0) [0|0] "" HMDH_207
 SG_ Ecat_Name12 m31 : 112|8@1+ (1,0) [0|0] "" HMDH_207
 SG_ Ecat_Name13 m31 : 120|8@1+ (1,0) [0|0] "" HMDH_207
 SG_ Ecat_Name14 m31 : 128|8@1+ (1,0) [0|0] "" HMDH_207
 SG_ Ecat_Name15 m31 : 136|8@1+ (1,0) [0|0] "" HMDH_207
 SG_ Ecat_Link m31 : 144|8@1+ (1,0) [0|0] "" HMDH_207
 SG_ Ecat_InvalidFrame0 m31 : 152|8@1+ (1,0) [0|0] "" HMDH_207
 SG_ Ecat_InvalidFrame1 m31 : 160|8@1+ (1,0) [0|0] "" HMDH_207
 SG_ Ecat_InvalidFrame2 m31 : 168|8@1+ (1,0) [0|0] "" HMDH_207
 SG_ Ecat_InvalidFrame3 m31 : 176|8@1+ (1,0) [0|0] "" HMDH_207
 SG_ Ecat_RxError0 m31 : 184|8@1+ (1,0) [0|0] "" HMDH_207
 SG_ Ecat_RxError1 m31 : 192|8@1+ (1,0) [0|0] "" HMDH_207
 SG_ Ecat_RxError2 m31 : 200|8@1+ (1,0) [0|0] "" HMDH_207
 SG_ Ecat_RxError3 m31 : 208|8@1+ (1,0) [0|0] "" HMDH_207
 SG_ Ecat_FwdRxError0 m31 : 216|8@1+ (1,0) [0|0] "" HMDH_207
 SG_ Ecat_FwdRxError1 m31 : 224|8@1+ (1,0) [0|0] "" HMDH_207
 SG_ Ecat_FwdRxError2 m31 : 232|8@1+ (1,0) [0|0] "" HMDH_207
 SG_ Ecat_FwdRxError3 m31 : 240|8@1+ (1,0) [0|0] "" HMDH_207
 SG_ Ecat_PuError m31 : 248|8@1+ (1,0) [0|0] "" HMDH_207
 SG_ Ecat_PdiError m31 : 256|8@1+ (1,0) [0|0] "" HMDH_207
 SG_ Ecat_LostLink0 m31 : 264|8@1+ (1,0) [0|0] "" HMDH_207
 SG_ Ecat_LostLink1 m31 : 272|8@1+ (1,0) [0|0] "" HMDH_207
 SG_ Ecat_LostLink2 m31 : 280|8@1+ (1,0) [0|0] "" HMDH_207
 SG_ Ecat_LostLink3 m31 : 288|8@1+ (1,0) [0|0] "" HMDH_207
 SG_ Saf_CanId m32 : 8|8@1+ (1,0) [0|0] "" HMDH_207
 SG_ Saf_Name0 m32 : 16|8@1+ (1,0) [0|0] "" HMDH_207
 SG_ Saf_Name1 m32 : 24|8@1+ (1,0) [0|0] "" HMDH_207
 SG_ Saf_Name2 m32 : 32|8@1+ (1,0) [0|0] "" HMDH_207
 SG_ Saf_Name3 m32 : 40|8@1+ (1,0) [0|0] "" HMDH_207
 SG_ Saf_Name4 m32 : 48|8@1+ (1,0) [0|0] "" HMDH_207
 SG_ Saf_Name5 m32 : 56|8@1+ (1,0) [0|0] "" HMDH_207
 SG_ Saf_Name6 m32 : 64|8@1+ (1,0) [0|0] "" HMDH_207
 SG_ Saf_Name7 m32 : 72|8@1+ (1,0) [0|0] "" HMDH_207
 SG_ Saf_Name8 m32 : 80|8@1+ (1,0) [0|0] "" HMDH_207
 SG_ Saf_Name9 m32 : 88|8@1+ (1,0) [0|0] "" HMDH_207
 SG_ Saf_Name10 m32 : 96|8@1+ (1,0) [0|0] "" HMDH_207
 SG_ Saf_Name11 m32 : 104|8@1+ (1,0) [0|0] "" HMDH_207
 SG_ Saf_Name12 m32 : 112|8@1+ (1,0) [0|0] "" HMDH_207
 SG_ Saf_Name13 m32 : 120|8@1+ (1,0) [0|0] "" HMDH_207
 SG_ Saf_Name14 m32 : 128|8@1+ (1,0) [0|0] "" HMDH_207
 SG_ Saf_Name15 m32 : 136|8@1+ (1,0) [0|0] "" HMDH_207
 SG_ Saf_State m32 : 144|8@1+ (1,0) [0|0] "" HMDH_207
 SG_ Saf_Bits m32 : 152|16@1+ (1,0) [0|0] "" HMDH_207
 SG_ Saf_Estop m32 : 168|8@1+ (1,0) [0|0] "" HMDH_207
 SG_ Saf_FatalLatched m32 : 176|16@1+ (1,0) [0|0] "" HMDH_207
 SG_ Saf_ErrCode m32 : 192|32@1+ (1,0) [0|0] "" HMDH_207

BO_ 2163306084 STATUS_HETC_M_WST_to_HETC_M_MOB: 48 HETC_M_WST
 SG_ SubCode M : 0|8@1+ (1,0) [0|0] "" HETC_M_MOB
 SG_ Ping_CanId m5 : 8|8@1+ (1,0) [0|0] "" HETC_M_MOB
 SG_ Ping_HostId m5 : 16|8@1+ (1,0) [0|0] "" HETC_M_MOB
 SG_ Ping_Pid m5 : 24|16@1+ (1,0) [0|0] "" HETC_M_MOB
 SG_ Ping_Bid m5 : 40|16@1+ (1,0) [0|0] "" HETC_M_MOB
 SG_ Ping_Mid m5 : 56|16@1+ (1,0) [0|0] "" HETC_M_MOB
 SG_ Ping_VerMajor m5 : 72|8@1+ (1,0) [0|0] "" HETC_M_MOB
 SG_ Ping_VerMinor m5 : 80|8@1+ (1,0) [0|0] "" HETC_M_MOB
 SG_ Ping_VerPatch m5 : 88|8@1+ (1,0) [0|0] "" HETC_M_MOB
 SG_ Ping_Name0 m5 : 96|8@1+ (1,0) [0|0] "" HETC_M_MOB
 SG_ Ping_Name1 m5 : 104|8@1+ (1,0) [0|0] "" HETC_M_MOB
 SG_ Ping_Name2 m5 : 112|8@1+ (1,0) [0|0] "" HETC_M_MOB
 SG_ Ping_Name3 m5 : 120|8@1+ (1,0) [0|0] "" HETC_M_MOB
 SG_ Ping_Name4 m5 : 128|8@1+ (1,0) [0|0] "" HETC_M_MOB
 SG_ Ping_Name5 m5 : 136|8@1+ (1,0) [0|0] "" HETC_M_MOB
 SG_ Ping_Name6 m5 : 144|8@1+ (1,0) [0|0] "" HETC_M_MOB
 SG_ Ping_Name7 m5 : 152|8@1+ (1,0) [0|0] "" HETC_M_MOB
 SG_ Ping_Name8 m5 : 160|8@1+ (1,0) [0|0] "" HETC_M_MOB
 SG_ Ping_Name9 m5 : 168|8@1+ (1,0) [0|0] "" HETC_M_MOB
 SG_ Ping_Name10 m5 : 176|8@1+ (1,0) [0|0] "" HETC_M_MOB
 SG_ Ping_Name11 m5 : 184|8@1+ (1,0) [0|0] "" HETC_M_MOB
 SG_ Ping_Name12 m5 : 192|8@1+ (1,0) [0|0] "" HETC_M_MOB
 SG_ Ping_Name13 m5 : 200|8@1+ (1,0) [0|0] "" HETC_M_MOB
 SG_ Ping_Name14 m5 : 208|8@1+ (1,0) [0|0] "" HETC_M_MOB
 SG_ Ping_Name15 m5 : 216|8@1+ (1,0) [0|0] "" HETC_M_MOB
 SG_ Ping_FmtVer m5 : 224|8@1+ (1,0) [0|0] "" HETC_M_MOB
 SG_ Ping_GitRev m5 : 232|32@1+ (1,0) [0|0] "" HETC_M_MOB
 SG_ Ping_FwCrc m5 : 264|16@1+ (1,0) [0|0] "" HETC_M_MOB
 SG_ Ping_UptimeS m5 : 280|16@1+ (1,0) [0|0] "s" HETC_M_MOB
 SG_ Ecat_CanId m31 : 8|8@1+ (1,0) [0|0] "" HETC_M_MOB
 SG_ Ecat_Name0 m31 : 16|8@1+ (1,0) [0|0] "" HETC_M_MOB
 SG_ Ecat_Name1 m31 : 24|8@1+ (1,0) [0|0] "" HETC_M_MOB
 SG_ Ecat_Name2 m31 : 32|8@1+ (1,0) [0|0] "" HETC_M_MOB
 SG_ Ecat_Name3 m31 : 40|8@1+ (1,0) [0|0] "" HETC_M_MOB
 SG_ Ecat_Name4 m31 : 48|8@1+ (1,0) [0|0] "" HETC_M_MOB
 SG_ Ecat_Name5 m31 : 56|8@1+ (1,0) [0|0] "" HETC_M_MOB
 SG_ Ecat_Name6 m31 : 64|8@1+ (1,0) [0|0] "" HETC_M_MOB
 SG_ Ecat_Name7 m31 : 72|8@1+ (1,0) [0|0] "" HETC_M_MOB
 SG_ Ecat_Name8 m31 : 80|8@1+ (1,0) [0|0] "" HETC_M_MOB
 SG_ Ecat_Name9 m31 : 88|8@1+ (1,0) [0|0] "" HETC_M_MOB
 SG_ Ecat_Name10 m31 : 96|8@1+ (1,0) [0|0] "" HETC_M_MOB
 SG_ Ecat_Name11 m31 : 104|8@1+ (1,0) [0|0] "" HETC_M_MOB
 SG_ Ecat_Name12 m31 : 112|8@1+ (1,0) [0|0] "" HETC_M_MOB
 SG_ Ecat_Name13 m31 : 120|8@1+ (1,0) [0|0] "" HETC_M_MOB
 SG_ Ecat_Name14 m31 : 128|8@1+ (1,0) [0|0] "" HETC_M_MOB
 SG_ Ecat_Name15 m31 : 136|8@1+ (1,0) [0|0] "" HETC_M_MOB
 SG_ Ecat_Link m31 : 144|8@1+ (1,0) [0|0] "" HETC_M_MOB
 SG_ Ecat_InvalidFrame0 m31 : 152|8@1+ (1,0) [0|0] "" HETC_M_MOB
 SG_ Ecat_InvalidFrame1 m31 : 160|8@1+ (1,0) [0|0] "" HETC_M_MOB
 SG_ Ecat_InvalidFrame2 m31 : 168|8@1+ (1,0) [0|0] "" HETC_M_MOB
 SG_ Ecat_InvalidFrame3 m31 : 176|8@1+ (1,0) [0|0] "" HETC_M_MOB
 SG_ Ecat_RxError0 m31 : 184|8@1+ (1,0) [0|0] "" HETC_M_MOB
 SG_ Ecat_RxError1 m31 : 192|8@1+ (1,0) [0|0] "" HETC_M_MOB
 SG_ Ecat_RxError2 m31 : 200|8@1+ (1,0) [0|0] "" HETC_M_MOB
 SG_ Ecat_RxError3 m31 : 208|8@1+ (1,0) [0|0] "" HETC_M_MOB
 SG_ Ecat_FwdRxError0 m31 : 216|8@1+ (1,0) [0|0] "" HETC_M_MOB
 SG_ Ecat_FwdRxError1 m31 : 224|8@1+ (1,0) [0|0] "" HETC_M_MOB
 SG_ Ecat_FwdRxError2 m31 : 232|8@1+ (1,0) [0|0] "" HETC_M_MOB
 SG_ Ecat_FwdRxError3 m31 : 240|8@1+ (1,0) [0|0] "" HETC_M_MOB
 SG_ Ecat_PuError m31 : 248|8@1+ (1,0) [0|0] "" HETC_M_MOB
 SG_ Ecat_PdiError m31 : 256|8@1+ (1,0) [0|0] "" HETC_M_MOB
 SG_ Ecat_LostLink0 m31 : 264|8@1+ (1,0) [0|0] "" HETC_M_MOB
 SG_ Ecat_LostLink1 m31 : 272|8@1+ (1,0) [0|0] "" HETC_M_MOB
 SG_ Ecat_LostLink2 m31 : 280|8@1+ (1,0) [0|0] "" HETC_M_MOB
 SG_ Ecat_LostLink3 m31 : 288|8@1+ (1,0) [0|0] "" HETC_M_MOB
 SG_ Saf_CanId m32 : 8|8@1+ (1,0) [0|0] "" HETC_M_MOB
 SG_ Saf_Name0 m32 : 16|8@1+ (1,0) [0|0] "" HETC_M_MOB
 SG_ Saf_Name1 m32 : 24|8@1+ (1,0) [0|0] "" HETC_M_MOB
 SG_ Saf_Name2 m32 : 32|8@1+ (1,0) [0|0] "" HETC_M_MOB
 SG_ Saf_Name3 m32 : 40|8@1+ (1,0) [0|0] "" HETC_M_MOB
 SG_ Saf_Name4 m32 : 48|8@1+ (1,0) [0|0] "" HETC_M_MOB
 SG_ Saf_Name5 m32 : 56|8@1+ (1,0) [0|0] "" HETC_M_MOB
 SG_ Saf_Name6 m32 : 64|8@1+ (1,0) [0|0] "" HETC_M_MOB
 SG_ Saf_Name7 m32 : 72|8@1+ (1,0) [0|0] "" HETC_M_MOB
 SG_ Saf_Name8 m32 : 80|8@1+ (1,0) [0|0] "" HETC_M_MOB
 SG_ Saf_Name9 m32 : 88|8@1+ (1,0) [0|0] "" HETC_M_MOB
 SG_ Saf_Name10 m32 : 96|8@1+ (1,0) [0|0] "" HETC_M_MOB
 SG_ Saf_Name11 m32 : 104|8@1+ (1,0) [0|0] "" HETC_M_MOB
 SG_ Saf_Name12 m32 : 112|8@1+ (1,0) [0|0] "" HETC_M_MOB
 SG_ Saf_Name13 m32 : 120|8@1+ (1,0) [0|0] "" HETC_M_MOB
 SG_ Saf_Name14 m32 : 128|8@1+ (1,0) [0|0] "" HETC_M_MOB
 SG_ Saf_Name15 m32 : 136|8@1+ (1,0) [0|0] "" HETC_M_MOB
 SG_ Saf_State m32 : 144|8@1+ (1,0) [0|0] "" HETC_M_MOB
 SG_ Saf_Bits m32 : 152|16@1+ (1,0) [0|0] "" HETC_M_MOB
 SG_ Saf_Estop m32 : 168|8@1+ (1,0) [0|0] "" HETC_M_MOB
 SG_ Saf_FatalLatched m32 : 176|16@1+ (1,0) [0|0] "" HETC_M_MOB
 SG_ Saf_ErrCode m32 : 192|32@1+ (1,0) [0|0] "" HETC_M_MOB

BO_ 2163306104 STATUS_HETC_M_WST_to_HETC_L_ARM: 48 HETC_M_WST
 SG_ SubCode M : 0|8@1+ (1,0) [0|0] "" HETC_L_ARM
 SG_ Ping_CanId m5 : 8|8@1+ (1,0) [0|0] "" HETC_L_ARM
 SG_ Ping_HostId m5 : 16|8@1+ (1,0) [0|0] "" HETC_L_ARM
 SG_ Ping_Pid m5 : 24|16@1+ (1,0) [0|0] "" HETC_L_ARM
 SG_ Ping_Bid m5 : 40|16@1+ (1,0) [0|0] "" HETC_L_ARM
 SG_ Ping_Mid m5 : 56|16@1+ (1,0) [0|0] "" HETC_L_ARM
 SG_ Ping_VerMajor m5 : 72|8@1+ (1,0) [0|0] "" HETC_L_ARM
 SG_ Ping_VerMinor m5 : 80|8@1+ (1,0) [0|0] "" HETC_L_ARM
 SG_ Ping_VerPatch m5 : 88|8@1+ (1,0) [0|0] "" HETC_L_ARM
 SG_ Ping_Name0 m5 : 96|8@1+ (1,0) [0|0] "" HETC_L_ARM
 SG_ Ping_Name1 m5 : 104|8@1+ (1,0) [0|0] "" HETC_L_ARM
 SG_ Ping_Name2 m5 : 112|8@1+ (1,0) [0|0] "" HETC_L_ARM
 SG_ Ping_Name3 m5 : 120|8@1+ (1,0) [0|0] "" HETC_L_ARM
 SG_ Ping_Name4 m5 : 128|8@1+ (1,0) [0|0] "" HETC_L_ARM
 SG_ Ping_Name5 m5 : 136|8@1+ (1,0) [0|0] "" HETC_L_ARM
 SG_ Ping_Name6 m5 : 144|8@1+ (1,0) [0|0] "" HETC_L_ARM
 SG_ Ping_Name7 m5 : 152|8@1+ (1,0) [0|0] "" HETC_L_ARM
 SG_ Ping_Name8 m5 : 160|8@1+ (1,0) [0|0] "" HETC_L_ARM
 SG_ Ping_Name9 m5 : 168|8@1+ (1,0) [0|0] "" HETC_L_ARM
 SG_ Ping_Name10 m5 : 176|8@1+ (1,0) [0|0] "" HETC_L_ARM
 SG_ Ping_Name11 m5 : 184|8@1+ (1,0) [0|0] "" HETC_L_ARM
 SG_ Ping_Name12 m5 : 192|8@1+ (1,0) [0|0] "" HETC_L_ARM
 SG_ Ping_Name13 m5 : 200|8@1+ (1,0) [0|0] "" HETC_L_ARM
 SG_ Ping_Name14 m5 : 208|8@1+ (1,0) [0|0] "" HETC_L_ARM
 SG_ Ping_Name15 m5 : 216|8@1+ (1,0) [0|0] "" HETC_L_ARM
 SG_ Ping_FmtVer m5 : 224|8@1+ (1,0) [0|0] "" HETC_L_ARM
 SG_ Ping_GitRev m5 : 232|32@1+ (1,0) [0|0] "" HETC_L_ARM
 SG_ Ping_FwCrc m5 : 264|16@1+ (1,0) [0|0] "" HETC_L_ARM
 SG_ Ping_UptimeS m5 : 280|16@1+ (1,0) [0|0] "s" HETC_L_ARM
 SG_ Ecat_CanId m31 : 8|8@1+ (1,0) [0|0] "" HETC_L_ARM
 SG_ Ecat_Name0 m31 : 16|8@1+ (1,0) [0|0] "" HETC_L_ARM
 SG_ Ecat_Name1 m31 : 24|8@1+ (1,0) [0|0] "" HETC_L_ARM
 SG_ Ecat_Name2 m31 : 32|8@1+ (1,0) [0|0] "" HETC_L_ARM
 SG_ Ecat_Name3 m31 : 40|8@1+ (1,0) [0|0] "" HETC_L_ARM
 SG_ Ecat_Name4 m31 : 48|8@1+ (1,0) [0|0] "" HETC_L_ARM
 SG_ Ecat_Name5 m31 : 56|8@1+ (1,0) [0|0] "" HETC_L_ARM
 SG_ Ecat_Name6 m31 : 64|8@1+ (1,0) [0|0] "" HETC_L_ARM
 SG_ Ecat_Name7 m31 : 72|8@1+ (1,0) [0|0] "" HETC_L_ARM
 SG_ Ecat_Name8 m31 : 80|8@1+ (1,0) [0|0] "" HETC_L_ARM
 SG_ Ecat_Name9 m31 : 88|8@1+ (1,0) [0|0] "" HETC_L_ARM
 SG_ Ecat_Name10 m31 : 96|8@1+ (1,0) [0|0] "" HETC_L_ARM
 SG_ Ecat_Name11 m31 : 104|8@1+ (1,0) [0|0] "" HETC_L_ARM
 SG_ Ecat_Name12 m31 : 112|8@1+ (1,0) [0|0] "" HETC_L_ARM
 SG_ Ecat_Name13 m31 : 120|8@1+ (1,0) [0|0] "" HETC_L_ARM
 SG_ Ecat_Name14 m31 : 128|8@1+ (1,0) [0|0] "" HETC_L_ARM
 SG_ Ecat_Name15 m31 : 136|8@1+ (1,0) [0|0] "" HETC_L_ARM
 SG_ Ecat_Link m31 : 144|8@1+ (1,0) [0|0] "" HETC_L_ARM
 SG_ Ecat_InvalidFrame0 m31 : 152|8@1+ (1,0) [0|0] "" HETC_L_ARM
 SG_ Ecat_InvalidFrame1 m31 : 160|8@1+ (1,0) [0|0] "" HETC_L_ARM
 SG_ Ecat_InvalidFrame2 m31 : 168|8@1+ (1,0) [0|0] "" HETC_L_ARM
 SG_ Ecat_InvalidFrame3 m31 : 176|8@1+ (1,0) [0|0] "" HETC_L_ARM
 SG_ Ecat_RxError0 m31 : 184|8@1+ (1,0) [0|0] "" HETC_L_ARM
 SG_ Ecat_RxError1 m31 : 192|8@1+ (1,0) [0|0] "" HETC_L_ARM
 SG_ Ecat_RxError2 m31 : 200|8@1+ (1,0) [0|0] "" HETC_L_ARM
 SG_ Ecat_RxError3 m31 : 208|8@1+ (1,0) [0|0] "" HETC_L_ARM
 SG_ Ecat_FwdRxError0 m31 : 216|8@1+ (1,0) [0|0] "" HETC_L_ARM
 SG_ Ecat_FwdRxError1 m31 : 224|8@1+ (1,0) [0|0] "" HETC_L_ARM
 SG_ Ecat_FwdRxError2 m31 : 232|8@1+ (1,0) [0|0] "" HETC_L_ARM
 SG_ Ecat_FwdRxError3 m31 : 240|8@1+ (1,0) [0|0] "" HETC_L_ARM
 SG_ Ecat_PuError m31 : 248|8@1+ (1,0) [0|0] "" HETC_L_ARM
 SG_ Ecat_PdiError m31 : 256|8@1+ (1,0) [0|0] "" HETC_L_ARM
 SG_ Ecat_LostLink0 m31 : 264|8@1+ (1,0) [0|0] "" HETC_L_ARM
 SG_ Ecat_LostLink1 m31 : 272|8@1+ (1,0) [0|0] "" HETC_L_ARM
 SG_ Ecat_LostLink2 m31 : 280|8@1+ (1,0) [0|0] "" HETC_L_ARM
 SG_ Ecat_LostLink3 m31 : 288|8@1+ (1,0) [0|0] "" HETC_L_ARM
 SG_ Saf_CanId m32 : 8|8@1+ (1,0) [0|0] "" HETC_L_ARM
 SG_ Saf_Name0 m32 : 16|8@1+ (1,0) [0|0] "" HETC_L_ARM
 SG_ Saf_Name1 m32 : 24|8@1+ (1,0) [0|0] "" HETC_L_ARM
 SG_ Saf_Name2 m32 : 32|8@1+ (1,0) [0|0] "" HETC_L_ARM
 SG_ Saf_Name3 m32 : 40|8@1+ (1,0) [0|0] "" HETC_L_ARM
 SG_ Saf_Name4 m32 : 48|8@1+ (1,0) [0|0] "" HETC_L_ARM
 SG_ Saf_Name5 m32 : 56|8@1+ (1,0) [0|0] "" HETC_L_ARM
 SG_ Saf_Name6 m32 : 64|8@1+ (1,0) [0|0] "" HETC_L_ARM
 SG_ Saf_Name7 m32 : 72|8@1+ (1,0) [0|0] "" HETC_L_ARM
 SG_ Saf_Name8 m32 : 80|8@1+ (1,0) [0|0] "" HETC_L_ARM
 SG_ Saf_Name9 m32 : 88|8@1+ (1,0) [0|0] "" HETC_L_ARM
 SG_ Saf_Name10 m32 : 96|8@1+ (1,0) [0|0] "" HETC_L_ARM
 SG_ Saf_Name11 m32 : 104|8@1+ (1,0) [0|0] "" HETC_L_ARM
 SG_ Saf_Name12 m32 : 112|8@1+ (1,0) [0|0] "" HETC_L_ARM
 SG_ Saf_Name13 m32 : 120|8@1+ (1,0) [0|0] "" HETC_L_ARM
 SG_ Saf_Name14 m32 : 128|8@1+ (1,0) [0|0] "" HETC_L_ARM
 SG_ Saf_Name15 m32 : 136|8@1+ (1,0) [0|0] "" HETC_L_ARM
 SG_ Saf_State m32 : 144|8@1+ (1,0) [0|0] "" HETC_L_ARM
 SG_ Saf_Bits m32 : 152|16@1+ (1,0) [0|0] "" HETC_L_ARM
 SG_ Saf_Estop m32 : 168|8@1+ (1,0) [0|0] "" HETC_L_ARM
 SG_ Saf_FatalLatched m32 : 176|16@1+ (1,0) [0|0] "" HETC_L_ARM
 SG_ Saf_ErrCode m32 : 192|32@1+ (1,0) [0|0] "" HETC_L_ARM

BO_ 2163306114 STATUS_HETC_M_WST_to_HETC_L_TACT: 48 HETC_M_WST
 SG_ SubCode M : 0|8@1+ (1,0) [0|0] "" HETC_L_TACT
 SG_ Ping_CanId m5 : 8|8@1+ (1,0) [0|0] "" HETC_L_TACT
 SG_ Ping_HostId m5 : 16|8@1+ (1,0) [0|0] "" HETC_L_TACT
 SG_ Ping_Pid m5 : 24|16@1+ (1,0) [0|0] "" HETC_L_TACT
 SG_ Ping_Bid m5 : 40|16@1+ (1,0) [0|0] "" HETC_L_TACT
 SG_ Ping_Mid m5 : 56|16@1+ (1,0) [0|0] "" HETC_L_TACT
 SG_ Ping_VerMajor m5 : 72|8@1+ (1,0) [0|0] "" HETC_L_TACT
 SG_ Ping_VerMinor m5 : 80|8@1+ (1,0) [0|0] "" HETC_L_TACT
 SG_ Ping_VerPatch m5 : 88|8@1+ (1,0) [0|0] "" HETC_L_TACT
 SG_ Ping_Name0 m5 : 96|8@1+ (1,0) [0|0] "" HETC_L_TACT
 SG_ Ping_Name1 m5 : 104|8@1+ (1,0) [0|0] "" HETC_L_TACT
 SG_ Ping_Name2 m5 : 112|8@1+ (1,0) [0|0] "" HETC_L_TACT
 SG_ Ping_Name3 m5 : 120|8@1+ (1,0) [0|0] "" HETC_L_TACT
 SG_ Ping_Name4 m5 : 128|8@1+ (1,0) [0|0] "" HETC_L_TACT
 SG_ Ping_Name5 m5 : 136|8@1+ (1,0) [0|0] "" HETC_L_TACT
 SG_ Ping_Name6 m5 : 144|8@1+ (1,0) [0|0] "" HETC_L_TACT
 SG_ Ping_Name7 m5 : 152|8@1+ (1,0) [0|0] "" HETC_L_TACT
 SG_ Ping_Name8 m5 : 160|8@1+ (1,0) [0|0] "" HETC_L_TACT
 SG_ Ping_Name9 m5 : 168|8@1+ (1,0) [0|0] "" HETC_L_TACT
 SG_ Ping_Name10 m5 : 176|8@1+ (1,0) [0|0] "" HETC_L_TACT
 SG_ Ping_Name11 m5 : 184|8@1+ (1,0) [0|0] "" HETC_L_TACT
 SG_ Ping_Name12 m5 : 192|8@1+ (1,0) [0|0] "" HETC_L_TACT
 SG_ Ping_Name13 m5 : 200|8@1+ (1,0) [0|0] "" HETC_L_TACT
 SG_ Ping_Name14 m5 : 208|8@1+ (1,0) [0|0] "" HETC_L_TACT
 SG_ Ping_Name15 m5 : 216|8@1+ (1,0) [0|0] "" HETC_L_TACT
 SG_ Ping_FmtVer m5 : 224|8@1+ (1,0) [0|0] "" HETC_L_TACT
 SG_ Ping_GitRev m5 : 232|32@1+ (1,0) [0|0] "" HETC_L_TACT
 SG_ Ping_FwCrc m5 : 264|16@1+ (1,0) [0|0] "" HETC_L_TACT
 SG_ Ping_UptimeS m5 : 280|16@1+ (1,0) [0|0] "s" HETC_L_TACT
 SG_ Ecat_CanId m31 : 8|8@1+ (1,0) [0|0] "" HETC_L_TACT
 SG_ Ecat_Name0 m31 : 16|8@1+ (1,0) [0|0] "" HETC_L_TACT
 SG_ Ecat_Name1 m31 : 24|8@1+ (1,0) [0|0] "" HETC_L_TACT
 SG_ Ecat_Name2 m31 : 32|8@1+ (1,0) [0|0] "" HETC_L_TACT
 SG_ Ecat_Name3 m31 : 40|8@1+ (1,0) [0|0] "" HETC_L_TACT
 SG_ Ecat_Name4 m31 : 48|8@1+ (1,0) [0|0] "" HETC_L_TACT
 SG_ Ecat_Name5 m31 : 56|8@1+ (1,0) [0|0] "" HETC_L_TACT
 SG_ Ecat_Name6 m31 : 64|8@1+ (1,0) [0|0] "" HETC_L_TACT
 SG_ Ecat_Name7 m31 : 72|8@1+ (1,0) [0|0] "" HETC_L_TACT
 SG_ Ecat_Name8 m31 : 80|8@1+ (1,0) [0|0] "" HETC_L_TACT
 SG_ Ecat_Name9 m31 : 88|8@1+ (1,0) [0|0] "" HETC_L_TACT
 SG_ Ecat_Name10 m31 : 96|8@1+ (1,0) [0|0] "" HETC_L_TACT
 SG_ Ecat_Name11 m31 : 104|8@1+ (1,0) [0|0] "" HETC_L_TACT
 SG_ Ecat_Name12 m31 : 112|8@1+ (1,0) [0|0] "" HETC_L_TACT
 SG_ Ecat_Name13 m31 : 120|8@1+ (1,0) [0|0] "" HETC_L_TACT
 SG_ Ecat_Name14 m31 : 128|8@1+ (1,0) [0|0] "" HETC_L_TACT
 SG_ Ecat_Name15 m31 : 136|8@1+ (1,0) [0|0] "" HETC_L_TACT
 SG_ Ecat_Link m31 : 144|8@1+ (1,0) [0|0] "" HETC_L_TACT
 SG_ Ecat_InvalidFrame0 m31 : 152|8@1+ (1,0) [0|0] "" HETC_L_TACT
 SG_ Ecat_InvalidFrame1 m31 : 160|8@1+ (1,0) [0|0] "" HETC_L_TACT
 SG_ Ecat_InvalidFrame2 m31 : 168|8@1+ (1,0) [0|0] "" HETC_L_TACT
 SG_ Ecat_InvalidFrame3 m31 : 176|8@1+ (1,0) [0|0] "" HETC_L_TACT
 SG_ Ecat_RxError0 m31 : 184|8@1+ (1,0) [0|0] "" HETC_L_TACT
 SG_ Ecat_RxError1 m31 : 192|8@1+ (1,0) [0|0] "" HETC_L_TACT
 SG_ Ecat_RxError2 m31 : 200|8@1+ (1,0) [0|0] "" HETC_L_TACT
 SG_ Ecat_RxError3 m31 : 208|8@1+ (1,0) [0|0] "" HETC_L_TACT
 SG_ Ecat_FwdRxError0 m31 : 216|8@1+ (1,0) [0|0] "" HETC_L_TACT
 SG_ Ecat_FwdRxError1 m31 : 224|8@1+ (1,0) [0|0] "" HETC_L_TACT
 SG_ Ecat_FwdRxError2 m31 : 232|8@1+ (1,0) [0|0] "" HETC_L_TACT
 SG_ Ecat_FwdRxError3 m31 : 240|8@1+ (1,0) [0|0] "" HETC_L_TACT
 SG_ Ecat_PuError m31 : 248|8@1+ (1,0) [0|0] "" HETC_L_TACT
 SG_ Ecat_PdiError m31 : 256|8@1+ (1,0) [0|0] "" HETC_L_TACT
 SG_ Ecat_LostLink0 m31 : 264|8@1+ (1,0) [0|0] "" HETC_L_TACT
 SG_ Ecat_LostLink1 m31 : 272|8@1+ (1,0) [0|0] "" HETC_L_TACT
 SG_ Ecat_LostLink2 m31 : 280|8@1+ (1,0) [0|0] "" HETC_L_TACT
 SG_ Ecat_LostLink3 m31 : 288|8@1+ (1,0) [0|0] "" HETC_L_TACT
 SG_ Saf_CanId m32 : 8|8@1+ (1,0) [0|0] "" HETC_L_TACT
 SG_ Saf_Name0 m32 : 16|8@1+ (1,0) [0|0] "" HETC_L_TACT
 SG_ Saf_Name1 m32 : 24|8@1+ (1,0) [0|0] "" HETC_L_TACT
 SG_ Saf_Name2 m32 : 32|8@1+ (1,0) [0|0] "" HETC_L_TACT
 SG_ Saf_Name3 m32 : 40|8@1+ (1,0) [0|0] "" HETC_L_TACT
 SG_ Saf_Name4 m32 : 48|8@1+ (1,0) [0|0] "" HETC_L_TACT
 SG_ Saf_Name5 m32 : 56|8@1+ (1,0) [0|0] "" HETC_L_TACT
 SG_ Saf_Name6 m32 : 64|8@1+ (1,0) [0|0] "" HETC_L_TACT
 SG_ Saf_Name7 m32 : 72|8@1+ (1,0) [0|0] "" HETC_L_TACT
 SG_ Saf_Name8 m32 : 80|8@1+ (1,0) [0|0] "" HETC_L_TACT
 SG_ Saf_Name9 m32 : 88|8@1+ (1,0) [0|0] "" HETC_L_TACT
 SG_ Saf_Name10 m32 : 96|8@1+ (1,0) [0|0] "" HETC_L_TACT
 SG_ Saf_Name11 m32 : 104|8@1+ (1,0) [0|0] "" HETC_L_TACT
 SG_ Saf_Name12 m32 : 112|8@1+ (1,0) [0|0] "" HETC_L_TACT
 SG_ Saf_Name13 m32 : 120|8@1+ (1,0) [0|0] "" HETC_L_TACT
 SG_ Saf_Name14 m32 : 128|8@1+ (1,0) [0|0] "" HETC_L_TACT
 SG_ Saf_Name15 m32 : 136|8@1+ (1,0) [0|0] "" HETC_L_TACT
 SG_ Saf_State m32 : 144|8@1+ (1,0) [0|0] "" HETC_L_TACT
 SG_ Saf_Bits m32 : 152|16@1+ (1,0) [0|0] "" HETC_L_TACT
 SG_ Saf_Estop m32 : 168|8@1+ (1,0) [0|0] "" HETC_L_TACT
 SG_ Saf_FatalLatched m32 : 176|16@1+ (1,0) [0|0] "" HETC_L_TACT
 SG_ Saf_ErrCode m32 : 192|32@1+ (1,0) [0|0] "" HETC_L_TACT

BO_ 2163306124 STATUS_HETC_M_WST_to_HETC_R_ARM: 48 HETC_M_WST
 SG_ SubCode M : 0|8@1+ (1,0) [0|0] "" HETC_R_ARM
 SG_ Ping_CanId m5 : 8|8@1+ (1,0) [0|0] "" HETC_R_ARM
 SG_ Ping_HostId m5 : 16|8@1+ (1,0) [0|0] "" HETC_R_ARM
 SG_ Ping_Pid m5 : 24|16@1+ (1,0) [0|0] "" HETC_R_ARM
 SG_ Ping_Bid m5 : 40|16@1+ (1,0) [0|0] "" HETC_R_ARM
 SG_ Ping_Mid m5 : 56|16@1+ (1,0) [0|0] "" HETC_R_ARM
 SG_ Ping_VerMajor m5 : 72|8@1+ (1,0) [0|0] "" HETC_R_ARM
 SG_ Ping_VerMinor m5 : 80|8@1+ (1,0) [0|0] "" HETC_R_ARM
 SG_ Ping_VerPatch m5 : 88|8@1+ (1,0) [0|0] "" HETC_R_ARM
 SG_ Ping_Name0 m5 : 96|8@1+ (1,0) [0|0] "" HETC_R_ARM
 SG_ Ping_Name1 m5 : 104|8@1+ (1,0) [0|0] "" HETC_R_ARM
 SG_ Ping_Name2 m5 : 112|8@1+ (1,0) [0|0] "" HETC_R_ARM
 SG_ Ping_Name3 m5 : 120|8@1+ (1,0) [0|0] "" HETC_R_ARM
 SG_ Ping_Name4 m5 : 128|8@1+ (1,0) [0|0] "" HETC_R_ARM
 SG_ Ping_Name5 m5 : 136|8@1+ (1,0) [0|0] "" HETC_R_ARM
 SG_ Ping_Name6 m5 : 144|8@1+ (1,0) [0|0] "" HETC_R_ARM
 SG_ Ping_Name7 m5 : 152|8@1+ (1,0) [0|0] "" HETC_R_ARM
 SG_ Ping_Name8 m5 : 160|8@1+ (1,0) [0|0] "" HETC_R_ARM
 SG_ Ping_Name9 m5 : 168|8@1+ (1,0) [0|0] "" HETC_R_ARM
 SG_ Ping_Name10 m5 : 176|8@1+ (1,0) [0|0] "" HETC_R_ARM
 SG_ Ping_Name11 m5 : 184|8@1+ (1,0) [0|0] "" HETC_R_ARM
 SG_ Ping_Name12 m5 : 192|8@1+ (1,0) [0|0] "" HETC_R_ARM
 SG_ Ping_Name13 m5 : 200|8@1+ (1,0) [0|0] "" HETC_R_ARM
 SG_ Ping_Name14 m5 : 208|8@1+ (1,0) [0|0] "" HETC_R_ARM
 SG_ Ping_Name15 m5 : 216|8@1+ (1,0) [0|0] "" HETC_R_ARM
 SG_ Ping_FmtVer m5 : 224|8@1+ (1,0) [0|0] "" HETC_R_ARM
 SG_ Ping_GitRev m5 : 232|32@1+ (1,0) [0|0] "" HETC_R_ARM
 SG_ Ping_FwCrc m5 : 264|16@1+ (1,0) [0|0] "" HETC_R_ARM
 SG_ Ping_UptimeS m5 : 280|16@1+ (1,0) [0|0] "s" HETC_R_ARM
 SG_ Ecat_CanId m31 : 8|8@1+ (1,0) [0|0] "" HETC_R_ARM
 SG_ Ecat_Name0 m31 : 16|8@1+ (1,0) [0|0] "" HETC_R_ARM
 SG_ Ecat_Name1 m31 : 24|8@1+ (1,0) [0|0] "" HETC_R_ARM
 SG_ Ecat_Name2 m31 : 32|8@1+ (1,0) [0|0] "" HETC_R_ARM
 SG_ Ecat_Name3 m31 : 40|8@1+ (1,0) [0|0] "" HETC_R_ARM
 SG_ Ecat_Name4 m31 : 48|8@1+ (1,0) [0|0] "" HETC_R_ARM
 SG_ Ecat_Name5 m31 : 56|8@1+ (1,0) [0|0] "" HETC_R_ARM
 SG_ Ecat_Name6 m31 : 64|8@1+ (1,0) [0|0] "" HETC_R_ARM
 SG_ Ecat_Name7 m31 : 72|8@1+ (1,0) [0|0] "" HETC_R_ARM
 SG_ Ecat_Name8 m31 : 80|8@1+ (1,0) [0|0] "" HETC_R_ARM
 SG_ Ecat_Name9 m31 : 88|8@1+ (1,0) [0|0] "" HETC_R_ARM
 SG_ Ecat_Name10 m31 : 96|8@1+ (1,0) [0|0] "" HETC_R_ARM
 SG_ Ecat_Name11 m31 : 104|8@1+ (1,0) [0|0] "" HETC_R_ARM
 SG_ Ecat_Name12 m31 : 112|8@1+ (1,0) [0|0] "" HETC_R_ARM
 SG_ Ecat_Name13 m31 : 120|8@1+ (1,0) [0|0] "" HETC_R_ARM
 SG_ Ecat_Name14 m31 : 128|8@1+ (1,0) [0|0] "" HETC_R_ARM
 SG_ Ecat_Name15 m31 : 136|8@1+ (1,0) [0|0] "" HETC_R_ARM
 SG_ Ecat_Link m31 : 144|8@1+ (1,0) [0|0] "" HETC_R_ARM
 SG_ Ecat_InvalidFrame0 m31 : 152|8@1+ (1,0) [0|0] "" HETC_R_ARM
 SG_ Ecat_InvalidFrame1 m31 : 160|8@1+ (1,0) [0|0] "" HETC_R_ARM
 SG_ Ecat_InvalidFrame2 m31 : 168|8@1+ (1,0) [0|0] "" HETC_R_ARM
 SG_ Ecat_InvalidFrame3 m31 : 176|8@1+ (1,0) [0|0] "" HETC_R_ARM
 SG_ Ecat_RxError0 m31 : 184|8@1+ (1,0) [0|0] "" HETC_R_ARM
 SG_ Ecat_RxError1 m31 : 192|8@1+ (1,0) [0|0] "" HETC_R_ARM
 SG_ Ecat_RxError2 m31 : 200|8@1+ (1,0) [0|0] "" HETC_R_ARM
 SG_ Ecat_RxError3 m31 : 208|8@1+ (1,0) [0|0] "" HETC_R_ARM
 SG_ Ecat_FwdRxError0 m31 : 216|8@1+ (1,0) [0|0] "" HETC_R_ARM
 SG_ Ecat_FwdRxError1 m31 : 224|8@1+ (1,0) [0|0] "" HETC_R_ARM
 SG_ Ecat_FwdRxError2 m31 : 232|8@1+ (1,0) [0|0] "" HETC_R_ARM
 SG_ Ecat_FwdRxError3 m31 : 240|8@1+ (1,0) [0|0] "" HETC_R_ARM
 SG_ Ecat_PuError m31 : 248|8@1+ (1,0) [0|0] "" HETC_R_ARM
 SG_ Ecat_PdiError m31 : 256|8@1+ (1,0) [0|0] "" HETC_R_ARM
 SG_ Ecat_LostLink0 m31 : 264|8@1+ (1,0) [0|0] "" HETC_R_ARM
 SG_ Ecat_LostLink1 m31 : 272|8@1+ (1,0) [0|0] "" HETC_R_ARM
 SG_ Ecat_LostLink2 m31 : 280|8@1+ (1,0) [0|0] "" HETC_R_ARM
 SG_ Ecat_LostLink3 m31 : 288|8@1+ (1,0) [0|0] "" HETC_R_ARM
 SG_ Saf_CanId m32 : 8|8@1+ (1,0) [0|0] "" HETC_R_ARM
 SG_ Saf_Name0 m32 : 16|8@1+ (1,0) [0|0] "" HETC_R_ARM
 SG_ Saf_Name1 m32 : 24|8@1+ (1,0) [0|0] "" HETC_R_ARM
 SG_ Saf_Name2 m32 : 32|8@1+ (1,0) [0|0] "" HETC_R_ARM
 SG_ Saf_Name3 m32 : 40|8@1+ (1,0) [0|0] "" HETC_R_ARM
 SG_ Saf_Name4 m32 : 48|8@1+ (1,0) [0|0] "" HETC_R_ARM
 SG_ Saf_Name5 m32 : 56|8@1+ (1,0) [0|0] "" HETC_R_ARM
 SG_ Saf_Name6 m32 : 64|8@1+ (1,0) [0|0] "" HETC_R_ARM
 SG_ Saf_Name7 m32 : 72|8@1+ (1,0) [0|0] "" HETC_R_ARM
 SG_ Saf_Name8 m32 : 80|8@1+ (1,0) [0|0] "" HETC_R_ARM
 SG_ Saf_Name9 m32 : 88|8@1+ (1,0) [0|0] "" HETC_R_ARM
 SG_ Saf_Name10 m32 : 96|8@1+ (1,0) [0|0] "" HETC_R_ARM
 SG_ Saf_Name11 m32 : 104|8@1+ (1,0) [0|0] "" HETC_R_ARM
 SG_ Saf_Name12 m32 : 112|8@1+ (1,0) [0|0] "" HETC_R_ARM
 SG_ Saf_Name13 m32 : 120|8@1+ (1,0) [0|0] "" HETC_R_ARM
 SG_ Saf_Name14 m32 : 128|8@1+ (1,0) [0|0] "" HETC_R_ARM
 SG_ Saf_Name15 m32 : 136|8@1+ (1,0) [0|0] "" HETC_R_ARM
 SG_ Saf_State m32 : 144|8@1+ (1,0) [0|0] "" HETC_R_ARM
 SG_ Saf_Bits m32 : 152|16@1+ (1,0) [0|0] "" HETC_R_ARM
 SG_ Saf_Estop m32 : 168|8@1+ (1,0) [0|0] "" HETC_R_ARM
 SG_ Saf_FatalLatched m32 : 176|16@1+ (1,0) [0|0] "" HETC_R_ARM
 SG_ Saf_ErrCode m32 : 192|32@1+ (1,0) [0|0] "" HETC_R_ARM

BO_ 2163306134 STATUS_HETC_M_WST_to_HETC_R_TACT: 48 HETC_M_WST
 SG_ SubCode M : 0|8@1+ (1,0) [0|0] "" HETC_R_TACT
 SG_ Ping_CanId m5 : 8|8@1+ (1,0) [0|0] "" HETC_R_TACT
 SG_ Ping_HostId m5 : 16|8@1+ (1,0) [0|0] "" HETC_R_TACT
 SG_ Ping_Pid m5 : 24|16@1+ (1,0) [0|0] "" HETC_R_TACT
 SG_ Ping_Bid m5 : 40|16@1+ (1,0) [0|0] "" HETC_R_TACT
 SG_ Ping_Mid m5 : 56|16@1+ (1,0) [0|0] "" HETC_R_TACT
 SG_ Ping_VerMajor m5 : 72|8@1+ (1,0) [0|0] "" HETC_R_TACT
 SG_ Ping_VerMinor m5 : 80|8@1+ (1,0) [0|0] "" HETC_R_TACT
 SG_ Ping_VerPatch m5 : 88|8@1+ (1,0) [0|0] "" HETC_R_TACT
 SG_ Ping_Name0 m5 : 96|8@1+ (1,0) [0|0] "" HETC_R_TACT
 SG_ Ping_Name1 m5 : 104|8@1+ (1,0) [0|0] "" HETC_R_TACT
 SG_ Ping_Name2 m5 : 112|8@1+ (1,0) [0|0] "" HETC_R_TACT
 SG_ Ping_Name3 m5 : 120|8@1+ (1,0) [0|0] "" HETC_R_TACT
 SG_ Ping_Name4 m5 : 128|8@1+ (1,0) [0|0] "" HETC_R_TACT
 SG_ Ping_Name5 m5 : 136|8@1+ (1,0) [0|0] "" HETC_R_TACT
 SG_ Ping_Name6 m5 : 144|8@1+ (1,0) [0|0] "" HETC_R_TACT
 SG_ Ping_Name7 m5 : 152|8@1+ (1,0) [0|0] "" HETC_R_TACT
 SG_ Ping_Name8 m5 : 160|8@1+ (1,0) [0|0] "" HETC_R_TACT
 SG_ Ping_Name9 m5 : 168|8@1+ (1,0) [0|0] "" HETC_R_TACT
 SG_ Ping_Name10 m5 : 176|8@1+ (1,0) [0|0] "" HETC_R_TACT
 SG_ Ping_Name11 m5 : 184|8@1+ (1,0) [0|0] "" HETC_R_TACT
 SG_ Ping_Name12 m5 : 192|8@1+ (1,0) [0|0] "" HETC_R_TACT
 SG_ Ping_Name13 m5 : 200|8@1+ (1,0) [0|0] "" HETC_R_TACT
 SG_ Ping_Name14 m5 : 208|8@1+ (1,0) [0|0] "" HETC_R_TACT
 SG_ Ping_Name15 m5 : 216|8@1+ (1,0) [0|0] "" HETC_R_TACT
 SG_ Ping_FmtVer m5 : 224|8@1+ (1,0) [0|0] "" HETC_R_TACT
 SG_ Ping_GitRev m5 : 232|32@1+ (1,0) [0|0] "" HETC_R_TACT
 SG_ Ping_FwCrc m5 : 264|16@1+ (1,0) [0|0] "" HETC_R_TACT
 SG_ Ping_UptimeS m5 : 280|16@1+ (1,0) [0|0] "s" HETC_R_TACT
 SG_ Ecat_CanId m31 : 8|8@1+ (1,0) [0|0] "" HETC_R_TACT
 SG_ Ecat_Name0 m31 : 16|8@1+ (1,0) [0|0] "" HETC_R_TACT
 SG_ Ecat_Name1 m31 : 24|8@1+ (1,0) [0|0] "" HETC_R_TACT
 SG_ Ecat_Name2 m31 : 32|8@1+ (1,0) [0|0] "" HETC_R_TACT
 SG_ Ecat_Name3 m31 : 40|8@1+ (1,0) [0|0] "" HETC_R_TACT
 SG_ Ecat_Name4 m31 : 48|8@1+ (1,0) [0|0] "" HETC_R_TACT
 SG_ Ecat_Name5 m31 : 56|8@1+ (1,0) [0|0] "" HETC_R_TACT
 SG_ Ecat_Name6 m31 : 64|8@1+ (1,0) [0|0] "" HETC_R_TACT
 SG_ Ecat_Name7 m31 : 72|8@1+ (1,0) [0|0] "" HETC_R_TACT
 SG_ Ecat_Name8 m31 : 80|8@1+ (1,0) [0|0] "" HETC_R_TACT
 SG_ Ecat_Name9 m31 : 88|8@1+ (1,0) [0|0] "" HETC_R_TACT
 SG_ Ecat_Name10 m31 : 96|8@1+ (1,0) [0|0] "" HETC_R_TACT
 SG_ Ecat_Name11 m31 : 104|8@1+ (1,0) [0|0] "" HETC_R_TACT
 SG_ Ecat_Name12 m31 : 112|8@1+ (1,0) [0|0] "" HETC_R_TACT
 SG_ Ecat_Name13 m31 : 120|8@1+ (1,0) [0|0] "" HETC_R_TACT
 SG_ Ecat_Name14 m31 : 128|8@1+ (1,0) [0|0] "" HETC_R_TACT
 SG_ Ecat_Name15 m31 : 136|8@1+ (1,0) [0|0] "" HETC_R_TACT
 SG_ Ecat_Link m31 : 144|8@1+ (1,0) [0|0] "" HETC_R_TACT
 SG_ Ecat_InvalidFrame0 m31 : 152|8@1+ (1,0) [0|0] "" HETC_R_TACT
 SG_ Ecat_InvalidFrame1 m31 : 160|8@1+ (1,0) [0|0] "" HETC_R_TACT
 SG_ Ecat_InvalidFrame2 m31 : 168|8@1+ (1,0) [0|0] "" HETC_R_TACT
 SG_ Ecat_InvalidFrame3 m31 : 176|8@1+ (1,0) [0|0] "" HETC_R_TACT
 SG_ Ecat_RxError0 m31 : 184|8@1+ (1,0) [0|0] "" HETC_R_TACT
 SG_ Ecat_RxError1 m31 : 192|8@1+ (1,0) [0|0] "" HETC_R_TACT
 SG_ Ecat_RxError2 m31 : 200|8@1+ (1,0) [0|0] "" HETC_R_TACT
 SG_ Ecat_RxError3 m31 : 208|8@1+ (1,0) [0|0] "" HETC_R_TACT
 SG_ Ecat_FwdRxError0 m31 : 216|8@1+ (1,0) [0|0] "" HETC_R_TACT
 SG_ Ecat_FwdRxError1 m31 : 224|8@1+ (1,0) [0|0] "" HETC_R_TACT
 SG_ Ecat_FwdRxError2 m31 : 232|8@1+ (1,0) [0|0] "" HETC_R_TACT
 SG_ Ecat_FwdRxError3 m31 : 240|8@1+ (1,0) [0|0] "" HETC_R_TACT
 SG_ Ecat_PuError m31 : 248|8@1+ (1,0) [0|0] "" HETC_R_TACT
 SG_ Ecat_PdiError m31 : 256|8@1+ (1,0) [0|0] "" HETC_R_TACT
 SG_ Ecat_LostLink0 m31 : 264|8@1+ (1,0) [0|0] "" HETC_R_TACT
 SG_ Ecat_LostLink1 m31 : 272|8@1+ (1,0) [0|0] "" HETC_R_TACT
 SG_ Ecat_LostLink2 m31 : 280|8@1+ (1,0) [0|0] "" HETC_R_TACT
 SG_ Ecat_LostLink3 m31 : 288|8@1+ (1,0) [0|0] "" HETC_R_TACT
 SG_ Saf_CanId m32 : 8|8@1+ (1,0) [0|0] "" HETC_R_TACT
 SG_ Saf_Name0 m32 : 16|8@1+ (1,0) [0|0] "" HETC_R_TACT
 SG_ Saf_Name1 m32 : 24|8@1+ (1,0) [0|0] "" HETC_R_TACT
 SG_ Saf_Name2 m32 : 32|8@1+ (1,0) [0|0] "" HETC_R_TACT
 SG_ Saf_Name3 m32 : 40|8@1+ (1,0) [0|0] "" HETC_R_TACT
 SG_ Saf_Name4 m32 : 48|8@1+ (1,0) [0|0] "" HETC_R_TACT
 SG_ Saf_Name5 m32 : 56|8@1+ (1,0) [0|0] "" HETC_R_TACT
 SG_ Saf_Name6 m32 : 64|8@1+ (1,0) [0|0] "" HETC_R_TACT
 SG_ Saf_Name7 m32 : 72|8@1+ (1,0) [0|0] "" HETC_R_TACT
 SG_ Saf_Name8 m32 : 80|8@1+ (1,0) [0|0] "" HETC_R_TACT
 SG_ Saf_Name9 m32 : 88|8@1+ (1,0) [0|0] "" HETC_R_TACT
 SG_ Saf_Name10 m32 : 96|8@1+ (1,0) [0|0] "" HETC_R_TACT
 SG_ Saf_Name11 m32 : 104|8@1+ (1,0) [0|0] "" HETC_R_TACT
 SG_ Saf_Name12 m32 : 112|8@1+ (1,0) [0|0] "" HETC_R_TACT
 SG_ Saf_Name13 m32 : 120|8@1+ (1,0) [0|0] "" HETC_R_TACT
 SG_ Saf_Name14 m32 : 128|8@1+ (1,0) [0|0] "" HETC_R_TACT
 SG_ Saf_Name15 m32 : 136|8@1+ (1,0) [0|0] "" HETC_R_TACT
 SG_ Saf_State m32 : 144|8@1+ (1,0) [0|0] "" HETC_R_TACT
 SG_ Saf_Bits m32 : 152|16@1+ (1,0) [0|0] "" HETC_R_TACT
 SG_ Saf_Estop m32 : 168|8@1+ (1,0) [0|0] "" HETC_R_TACT
 SG_ Saf_FatalLatched m32 : 176|16@1+ (1,0) [0|0] "" HETC_R_TACT
 SG_ Saf_ErrCode m32 : 192|32@1+ (1,0) [0|0] "" HETC_R_TACT

BO_ 2163306185 STATUS_HETC_M_WST_to_HMDH_201: 48 HETC_M_WST
 SG_ SubCode M : 0|8@1+ (1,0) [0|0] "" HMDH_201
 SG_ Ping_CanId m5 : 8|8@1+ (1,0) [0|0] "" HMDH_201
 SG_ Ping_HostId m5 : 16|8@1+ (1,0) [0|0] "" HMDH_201
 SG_ Ping_Pid m5 : 24|16@1+ (1,0) [0|0] "" HMDH_201
 SG_ Ping_Bid m5 : 40|16@1+ (1,0) [0|0] "" HMDH_201
 SG_ Ping_Mid m5 : 56|16@1+ (1,0) [0|0] "" HMDH_201
 SG_ Ping_VerMajor m5 : 72|8@1+ (1,0) [0|0] "" HMDH_201
 SG_ Ping_VerMinor m5 : 80|8@1+ (1,0) [0|0] "" HMDH_201
 SG_ Ping_VerPatch m5 : 88|8@1+ (1,0) [0|0] "" HMDH_201
 SG_ Ping_Name0 m5 : 96|8@1+ (1,0) [0|0] "" HMDH_201
 SG_ Ping_Name1 m5 : 104|8@1+ (1,0) [0|0] "" HMDH_201
 SG_ Ping_Name2 m5 : 112|8@1+ (1,0) [0|0] "" HMDH_201
 SG_ Ping_Name3 m5 : 120|8@1+ (1,0) [0|0] "" HMDH_201
 SG_ Ping_Name4 m5 : 128|8@1+ (1,0) [0|0] "" HMDH_201
 SG_ Ping_Name5 m5 : 136|8@1+ (1,0) [0|0] "" HMDH_201
 SG_ Ping_Name6 m5 : 144|8@1+ (1,0) [0|0] "" HMDH_201
 SG_ Ping_Name7 m5 : 152|8@1+ (1,0) [0|0] "" HMDH_201
 SG_ Ping_Name8 m5 : 160|8@1+ (1,0) [0|0] "" HMDH_201
 SG_ Ping_Name9 m5 : 168|8@1+ (1,0) [0|0] "" HMDH_201
 SG_ Ping_Name10 m5 : 176|8@1+ (1,0) [0|0] "" HMDH_201
 SG_ Ping_Name11 m5 : 184|8@1+ (1,0) [0|0] "" HMDH_201
 SG_ Ping_Name12 m5 : 192|8@1+ (1,0) [0|0] "" HMDH_201
 SG_ Ping_Name13 m5 : 200|8@1+ (1,0) [0|0] "" HMDH_201
 SG_ Ping_Name14 m5 : 208|8@1+ (1,0) [0|0] "" HMDH_201
 SG_ Ping_Name15 m5 : 216|8@1+ (1,0) [0|0] "" HMDH_201
 SG_ Ping_FmtVer m5 : 224|8@1+ (1,0) [0|0] "" HMDH_201
 SG_ Ping_GitRev m5 : 232|32@1+ (1,0) [0|0] "" HMDH_201
 SG_ Ping_FwCrc m5 : 264|16@1+ (1,0) [0|0] "" HMDH_201
 SG_ Ping_UptimeS m5 : 280|16@1+ (1,0) [0|0] "s" HMDH_201
 SG_ Ecat_CanId m31 : 8|8@1+ (1,0) [0|0] "" HMDH_201
 SG_ Ecat_Name0 m31 : 16|8@1+ (1,0) [0|0] "" HMDH_201
 SG_ Ecat_Name1 m31 : 24|8@1+ (1,0) [0|0] "" HMDH_201
 SG_ Ecat_Name2 m31 : 32|8@1+ (1,0) [0|0] "" HMDH_201
 SG_ Ecat_Name3 m31 : 40|8@1+ (1,0) [0|0] "" HMDH_201
 SG_ Ecat_Name4 m31 : 48|8@1+ (1,0) [0|0] "" HMDH_201
 SG_ Ecat_Name5 m31 : 56|8@1+ (1,0) [0|0] "" HMDH_201
 SG_ Ecat_Name6 m31 : 64|8@1+ (1,0) [0|0] "" HMDH_201
 SG_ Ecat_Name7 m31 : 72|8@1+ (1,0) [0|0] "" HMDH_201
 SG_ Ecat_Name8 m31 : 80|8@1+ (1,0) [0|0] "" HMDH_201
 SG_ Ecat_Name9 m31 : 88|8@1+ (1,0) [0|0] "" HMDH_201
 SG_ Ecat_Name10 m31 : 96|8@1+ (1,0) [0|0] "" HMDH_201
 SG_ Ecat_Name11 m31 : 104|8@1+ (1,0) [0|0] "" HMDH_201
 SG_ Ecat_Name12 m31 : 112|8@1+ (1,0) [0|0] "" HMDH_201
 SG_ Ecat_Name13 m31 : 120|8@1+ (1,0) [0|0] "" HMDH_201
 SG_ Ecat_Name14 m31 : 128|8@1+ (1,0) [0|0] "" HMDH_201
 SG_ Ecat_Name15 m31 : 136|8@1+ (1,0) [0|0] "" HMDH_201
 SG_ Ecat_Link m31 : 144|8@1+ (1,0) [0|0] "" HMDH_201
 SG_ Ecat_InvalidFrame0 m31 : 152|8@1+ (1,0) [0|0] "" HMDH_201
 SG_ Ecat_InvalidFrame1 m31 : 160|8@1+ (1,0) [0|0] "" HMDH_201
 SG_ Ecat_InvalidFrame2 m31 : 168|8@1+ (1,0) [0|0] "" HMDH_201
 SG_ Ecat_InvalidFrame3 m31 : 176|8@1+ (1,0) [0|0] "" HMDH_201
 SG_ Ecat_RxError0 m31 : 184|8@1+ (1,0) [0|0] "" HMDH_201
 SG_ Ecat_RxError1 m31 : 192|8@1+ (1,0) [0|0] "" HMDH_201
 SG_ Ecat_RxError2 m31 : 200|8@1+ (1,0) [0|0] "" HMDH_201
 SG_ Ecat_RxError3 m31 : 208|8@1+ (1,0) [0|0] "" HMDH_201
 SG_ Ecat_FwdRxError0 m31 : 216|8@1+ (1,0) [0|0] "" HMDH_201
 SG_ Ecat_FwdRxError1 m31 : 224|8@1+ (1,0) [0|0] "" HMDH_201
 SG_ Ecat_FwdRxError2 m31 : 232|8@1+ (1,0) [0|0] "" HMDH_201
 SG_ Ecat_FwdRxError3 m31 : 240|8@1+ (1,0) [0|0] "" HMDH_201
 SG_ Ecat_PuError m31 : 248|8@1+ (1,0) [0|0] "" HMDH_201
 SG_ Ecat_PdiError m31 : 256|8@1+ (1,0) [0|0] "" HMDH_201
 SG_ Ecat_LostLink0 m31 : 264|8@1+ (1,0) [0|0] "" HMDH_201
 SG_ Ecat_LostLink1 m31 : 272|8@1+ (1,0) [0|0] "" HMDH_201
 SG_ Ecat_LostLink2 m31 : 280|8@1+ (1,0) [0|0] "" HMDH_201
 SG_ Ecat_LostLink3 m31 : 288|8@1+ (1,0) [0|0] "" HMDH_201
 SG_ Saf_CanId m32 : 8|8@1+ (1,0) [0|0] "" HMDH_201
 SG_ Saf_Name0 m32 : 16|8@1+ (1,0) [0|0] "" HMDH_201
 SG_ Saf_Name1 m32 : 24|8@1+ (1,0) [0|0] "" HMDH_201
 SG_ Saf_Name2 m32 : 32|8@1+ (1,0) [0|0] "" HMDH_201
 SG_ Saf_Name3 m32 : 40|8@1+ (1,0) [0|0] "" HMDH_201
 SG_ Saf_Name4 m32 : 48|8@1+ (1,0) [0|0] "" HMDH_201
 SG_ Saf_Name5 m32 : 56|8@1+ (1,0) [0|0] "" HMDH_201
 SG_ Saf_Name6 m32 : 64|8@1+ (1,0) [0|0] "" HMDH_201
 SG_ Saf_Name7 m32 : 72|8@1+ (1,0) [0|0] "" HMDH_201
 SG_ Saf_Name8 m32 : 80|8@1+ (1,0) [0|0] "" HMDH_201
 SG_ Saf_Name9 m32 : 88|8@1+ (1,0) [0|0] "" HMDH_201
 SG_ Saf_Name10 m32 : 96|8@1+ (1,0) [0|0] "" HMDH_201
 SG_ Saf_Name11 m32 : 104|8@1+ (1,0) [0|0] "" HMDH_201
 SG_ Saf_Name12 m32 : 112|8@1+ (1,0) [0|0] "" HMDH_201
 SG_ Saf_Name13 m32 : 120|8@1+ (1,0) [0|0] "" HMDH_201
 SG_ Saf_Name14 m32 : 128|8@1+ (1,0) [0|0] "" HMDH_201
 SG_ Saf_Name15 m32 : 136|8@1+ (1,0) [0|0] "" HMDH_201
 SG_ Saf_State m32 : 144|8@1+ (1,0) [0|0] "" HMDH_201
 SG_ Saf_Bits m32 : 152|16@1+ (1,0) [0|0] "" HMDH_201
 SG_ Saf_Estop m32 : 168|8@1+ (1,0) [0|0] "" HMDH_201
 SG_ Saf_FatalLatched m32 : 176|16@1+ (1,0) [0|0] "" HMDH_201
 SG_ Saf_ErrCode m32 : 192|32@1+ (1,0) [0|0] "" HMDH_201

BO_ 2163306186 STATUS_HETC_M_WST_to_HMDH_202: 48 HETC_M_WST
 SG_ SubCode M : 0|8@1+ (1,0) [0|0] "" HMDH_202
 SG_ Ping_CanId m5 : 8|8@1+ (1,0) [0|0] "" HMDH_202
 SG_ Ping_HostId m5 : 16|8@1+ (1,0) [0|0] "" HMDH_202
 SG_ Ping_Pid m5 : 24|16@1+ (1,0) [0|0] "" HMDH_202
 SG_ Ping_Bid m5 : 40|16@1+ (1,0) [0|0] "" HMDH_202
 SG_ Ping_Mid m5 : 56|16@1+ (1,0) [0|0] "" HMDH_202
 SG_ Ping_VerMajor m5 : 72|8@1+ (1,0) [0|0] "" HMDH_202
 SG_ Ping_VerMinor m5 : 80|8@1+ (1,0) [0|0] "" HMDH_202
 SG_ Ping_VerPatch m5 : 88|8@1+ (1,0) [0|0] "" HMDH_202
 SG_ Ping_Name0 m5 : 96|8@1+ (1,0) [0|0] "" HMDH_202
 SG_ Ping_Name1 m5 : 104|8@1+ (1,0) [0|0] "" HMDH_202
 SG_ Ping_Name2 m5 : 112|8@1+ (1,0) [0|0] "" HMDH_202
 SG_ Ping_Name3 m5 : 120|8@1+ (1,0) [0|0] "" HMDH_202
 SG_ Ping_Name4 m5 : 128|8@1+ (1,0) [0|0] "" HMDH_202
 SG_ Ping_Name5 m5 : 136|8@1+ (1,0) [0|0] "" HMDH_202
 SG_ Ping_Name6 m5 : 144|8@1+ (1,0) [0|0] "" HMDH_202
 SG_ Ping_Name7 m5 : 152|8@1+ (1,0) [0|0] "" HMDH_202
 SG_ Ping_Name8 m5 : 160|8@1+ (1,0) [0|0] "" HMDH_202
 SG_ Ping_Name9 m5 : 168|8@1+ (1,0) [0|0] "" HMDH_202
 SG_ Ping_Name10 m5 : 176|8@1+ (1,0) [0|0] "" HMDH_202
 SG_ Ping_Name11 m5 : 184|8@1+ (1,0) [0|0] "" HMDH_202
 SG_ Ping_Name12 m5 : 192|8@1+ (1,0) [0|0] "" HMDH_202
 SG_ Ping_Name13 m5 : 200|8@1+ (1,0) [0|0] "" HMDH_202
 SG_ Ping_Name14 m5 : 208|8@1+ (1,0) [0|0] "" HMDH_202
 SG_ Ping_Name15 m5 : 216|8@1+ (1,0) [0|0] "" HMDH_202
 SG_ Ping_FmtVer m5 : 224|8@1+ (1,0) [0|0] "" HMDH_202
 SG_ Ping_GitRev m5 : 232|32@1+ (1,0) [0|0] "" HMDH_202
 SG_ Ping_FwCrc m5 : 264|16@1+ (1,0) [0|0] "" HMDH_202
 SG_ Ping_UptimeS m5 : 280|16@1+ (1,0) [0|0] "s" HMDH_202
 SG_ Ecat_CanId m31 : 8|8@1+ (1,0) [0|0] "" HMDH_202
 SG_ Ecat_Name0 m31 : 16|8@1+ (1,0) [0|0] "" HMDH_202
 SG_ Ecat_Name1 m31 : 24|8@1+ (1,0) [0|0] "" HMDH_202
 SG_ Ecat_Name2 m31 : 32|8@1+ (1,0) [0|0] "" HMDH_202
 SG_ Ecat_Name3 m31 : 40|8@1+ (1,0) [0|0] "" HMDH_202
 SG_ Ecat_Name4 m31 : 48|8@1+ (1,0) [0|0] "" HMDH_202
 SG_ Ecat_Name5 m31 : 56|8@1+ (1,0) [0|0] "" HMDH_202
 SG_ Ecat_Name6 m31 : 64|8@1+ (1,0) [0|0] "" HMDH_202
 SG_ Ecat_Name7 m31 : 72|8@1+ (1,0) [0|0] "" HMDH_202
 SG_ Ecat_Name8 m31 : 80|8@1+ (1,0) [0|0] "" HMDH_202
 SG_ Ecat_Name9 m31 : 88|8@1+ (1,0) [0|0] "" HMDH_202
 SG_ Ecat_Name10 m31 : 96|8@1+ (1,0) [0|0] "" HMDH_202
 SG_ Ecat_Name11 m31 : 104|8@1+ (1,0) [0|0] "" HMDH_202
 SG_ Ecat_Name12 m31 : 112|8@1+ (1,0) [0|0] "" HMDH_202
 SG_ Ecat_Name13 m31 : 120|8@1+ (1,0) [0|0] "" HMDH_202
 SG_ Ecat_Name14 m31 : 128|8@1+ (1,0) [0|0] "" HMDH_202
 SG_ Ecat_Name15 m31 : 136|8@1+ (1,0) [0|0] "" HMDH_202
 SG_ Ecat_Link m31 : 144|8@1+ (1,0) [0|0] "" HMDH_202
 SG_ Ecat_InvalidFrame0 m31 : 152|8@1+ (1,0) [0|0] "" HMDH_202
 SG_ Ecat_InvalidFrame1 m31 : 160|8@1+ (1,0) [0|0] "" HMDH_202
 SG_ Ecat_InvalidFrame2 m31 : 168|8@1+ (1,0) [0|0] "" HMDH_202
 SG_ Ecat_InvalidFrame3 m31 : 176|8@1+ (1,0) [0|0] "" HMDH_202
 SG_ Ecat_RxError0 m31 : 184|8@1+ (1,0) [0|0] "" HMDH_202
 SG_ Ecat_RxError1 m31 : 192|8@1+ (1,0) [0|0] "" HMDH_202
 SG_ Ecat_RxError2 m31 : 200|8@1+ (1,0) [0|0] "" HMDH_202
 SG_ Ecat_RxError3 m31 : 208|8@1+ (1,0) [0|0] "" HMDH_202
 SG_ Ecat_FwdRxError0 m31 : 216|8@1+ (1,0) [0|0] "" HMDH_202
 SG_ Ecat_FwdRxError1 m31 : 224|8@1+ (1,0) [0|0] "" HMDH_202
 SG_ Ecat_FwdRxError2 m31 : 232|8@1+ (1,0) [0|0] "" HMDH_202
 SG_ Ecat_FwdRxError3 m31 : 240|8@1+ (1,0) [0|0] "" HMDH_202
 SG_ Ecat_PuError m31 : 248|8@1+ (1,0) [0|0] "" HMDH_202
 SG_ Ecat_PdiError m31 : 256|8@1+ (1,0) [0|0] "" HMDH_202
 SG_ Ecat_LostLink0 m31 : 264|8@1+ (1,0) [0|0] "" HMDH_202
 SG_ Ecat_LostLink1 m31 : 272|8@1+ (1,0) [0|0] "" HMDH_202
 SG_ Ecat_LostLink2 m31 : 280|8@1+ (1,0) [0|0] "" HMDH_202
 SG_ Ecat_LostLink3 m31 : 288|8@1+ (1,0) [0|0] "" HMDH_202
 SG_ Saf_CanId m32 : 8|8@1+ (1,0) [0|0] "" HMDH_202
 SG_ Saf_Name0 m32 : 16|8@1+ (1,0) [0|0] "" HMDH_202
 SG_ Saf_Name1 m32 : 24|8@1+ (1,0) [0|0] "" HMDH_202
 SG_ Saf_Name2 m32 : 32|8@1+ (1,0) [0|0] "" HMDH_202
 SG_ Saf_Name3 m32 : 40|8@1+ (1,0) [0|0] "" HMDH_202
 SG_ Saf_Name4 m32 : 48|8@1+ (1,0) [0|0] "" HMDH_202
 SG_ Saf_Name5 m32 : 56|8@1+ (1,0) [0|0] "" HMDH_202
 SG_ Saf_Name6 m32 : 64|8@1+ (1,0) [0|0] "" HMDH_202
 SG_ Saf_Name7 m32 : 72|8@1+ (1,0) [0|0] "" HMDH_202
 SG_ Saf_Name8 m32 : 80|8@1+ (1,0) [0|0] "" HMDH_202
 SG_ Saf_Name9 m32 : 88|8@1+ (1,0) [0|0] "" HMDH_202
 SG_ Saf_Name10 m32 : 96|8@1+ (1,0) [0|0] "" HMDH_202
 SG_ Saf_Name11 m32 : 104|8@1+ (1,0) [0|0] "" HMDH_202
 SG_ Saf_Name12 m32 : 112|8@1+ (1,0) [0|0] "" HMDH_202
 SG_ Saf_Name13 m32 : 120|8@1+ (1,0) [0|0] "" HMDH_202
 SG_ Saf_Name14 m32 : 128|8@1+ (1,0) [0|0] "" HMDH_202
 SG_ Saf_Name15 m32 : 136|8@1+ (1,0) [0|0] "" HMDH_202
 SG_ Saf_State m32 : 144|8@1+ (1,0) [0|0] "" HMDH_202
 SG_ Saf_Bits m32 : 152|16@1+ (1,0) [0|0] "" HMDH_202
 SG_ Saf_Estop m32 : 168|8@1+ (1,0) [0|0] "" HMDH_202
 SG_ Saf_FatalLatched m32 : 176|16@1+ (1,0) [0|0] "" HMDH_202
 SG_ Saf_ErrCode m32 : 192|32@1+ (1,0) [0|0] "" HMDH_202

BO_ 2163306187 STATUS_HETC_M_WST_to_HMDH_203: 48 HETC_M_WST
 SG_ SubCode M : 0|8@1+ (1,0) [0|0] "" HMDH_203
 SG_ Ping_CanId m5 : 8|8@1+ (1,0) [0|0] "" HMDH_203
 SG_ Ping_HostId m5 : 16|8@1+ (1,0) [0|0] "" HMDH_203
 SG_ Ping_Pid m5 : 24|16@1+ (1,0) [0|0] "" HMDH_203
 SG_ Ping_Bid m5 : 40|16@1+ (1,0) [0|0] "" HMDH_203
 SG_ Ping_Mid m5 : 56|16@1+ (1,0) [0|0] "" HMDH_203
 SG_ Ping_VerMajor m5 : 72|8@1+ (1,0) [0|0] "" HMDH_203
 SG_ Ping_VerMinor m5 : 80|8@1+ (1,0) [0|0] "" HMDH_203
 SG_ Ping_VerPatch m5 : 88|8@1+ (1,0) [0|0] "" HMDH_203
 SG_ Ping_Name0 m5 : 96|8@1+ (1,0) [0|0] "" HMDH_203
 SG_ Ping_Name1 m5 : 104|8@1+ (1,0) [0|0] "" HMDH_203
 SG_ Ping_Name2 m5 : 112|8@1+ (1,0) [0|0] "" HMDH_203
 SG_ Ping_Name3 m5 : 120|8@1+ (1,0) [0|0] "" HMDH_203
 SG_ Ping_Name4 m5 : 128|8@1+ (1,0) [0|0] "" HMDH_203
 SG_ Ping_Name5 m5 : 136|8@1+ (1,0) [0|0] "" HMDH_203
 SG_ Ping_Name6 m5 : 144|8@1+ (1,0) [0|0] "" HMDH_203
 SG_ Ping_Name7 m5 : 152|8@1+ (1,0) [0|0] "" HMDH_203
 SG_ Ping_Name8 m5 : 160|8@1+ (1,0) [0|0] "" HMDH_203
 SG_ Ping_Name9 m5 : 168|8@1+ (1,0) [0|0] "" HMDH_203
 SG_ Ping_Name10 m5 : 176|8@1+ (1,0) [0|0] "" HMDH_203
 SG_ Ping_Name11 m5 : 184|8@1+ (1,0) [0|0] "" HMDH_203
 SG_ Ping_Name12 m5 : 192|8@1+ (1,0) [0|0] "" HMDH_203
 SG_ Ping_Name13 m5 : 200|8@1+ (1,0) [0|0] "" HMDH_203
 SG_ Ping_Name14 m5 : 208|8@1+ (1,0) [0|0] "" HMDH_203
 SG_ Ping_Name15 m5 : 216|8@1+ (1,0) [0|0] "" HMDH_203
 SG_ Ping_FmtVer m5 : 224|8@1+ (1,0) [0|0] "" HMDH_203
 SG_ Ping_GitRev m5 : 232|32@1+ (1,0) [0|0] "" HMDH_203
 SG_ Ping_FwCrc m5 : 264|16@1+ (1,0) [0|0] "" HMDH_203
 SG_ Ping_UptimeS m5 : 280|16@1+ (1,0) [0|0] "s" HMDH_203
 SG_ Ecat_CanId m31 : 8|8@1+ (1,0) [0|0] "" HMDH_203
 SG_ Ecat_Name0 m31 : 16|8@1+ (1,0) [0|0] "" HMDH_203
 SG_ Ecat_Name1 m31 : 24|8@1+ (1,0) [0|0] "" HMDH_203
 SG_ Ecat_Name2 m31 : 32|8@1+ (1,0) [0|0] "" HMDH_203
 SG_ Ecat_Name3 m31 : 40|8@1+ (1,0) [0|0] "" HMDH_203
 SG_ Ecat_Name4 m31 : 48|8@1+ (1,0) [0|0] "" HMDH_203
 SG_ Ecat_Name5 m31 : 56|8@1+ (1,0) [0|0] "" HMDH_203
 SG_ Ecat_Name6 m31 : 64|8@1+ (1,0) [0|0] "" HMDH_203
 SG_ Ecat_Name7 m31 : 72|8@1+ (1,0) [0|0] "" HMDH_203
 SG_ Ecat_Name8 m31 : 80|8@1+ (1,0) [0|0] "" HMDH_203
 SG_ Ecat_Name9 m31 : 88|8@1+ (1,0) [0|0] "" HMDH_203
 SG_ Ecat_Name10 m31 : 96|8@1+ (1,0) [0|0] "" HMDH_203
 SG_ Ecat_Name11 m31 : 104|8@1+ (1,0) [0|0] "" HMDH_203
 SG_ Ecat_Name12 m31 : 112|8@1+ (1,0) [0|0] "" HMDH_203
 SG_ Ecat_Name13 m31 : 120|8@1+ (1,0) [0|0] "" HMDH_203
 SG_ Ecat_Name14 m31 : 128|8@1+ (1,0) [0|0] "" HMDH_203
 SG_ Ecat_Name15 m31 : 136|8@1+ (1,0) [0|0] "" HMDH_203
 SG_ Ecat_Link m31 : 144|8@1+ (1,0) [0|0] "" HMDH_203
 SG_ Ecat_InvalidFrame0 m31 : 152|8@1+ (1,0) [0|0] "" HMDH_203
 SG_ Ecat_InvalidFrame1 m31 : 160|8@1+ (1,0) [0|0] "" HMDH_203
 SG_ Ecat_InvalidFrame2 m31 : 168|8@1+ (1,0) [0|0] "" HMDH_203
 SG_ Ecat_InvalidFrame3 m31 : 176|8@1+ (1,0) [0|0] "" HMDH_203
 SG_ Ecat_RxError0 m31 : 184|8@1+ (1,0) [0|0] "" HMDH_203
 SG_ Ecat_RxError1 m31 : 192|8@1+ (1,0) [0|0] "" HMDH_203
 SG_ Ecat_RxError2 m31 : 200|8@1+ (1,0) [0|0] "" HMDH_203
 SG_ Ecat_RxError3 m31 : 208|8@1+ (1,0) [0|0] "" HMDH_203
 SG_ Ecat_FwdRxError0 m31 : 216|8@1+ (1,0) [0|0] "" HMDH_203
 SG_ Ecat_FwdRxError1 m31 : 224|8@1+ (1,0) [0|0] "" HMDH_203
 SG_ Ecat_FwdRxError2 m31 : 232|8@1+ (1,0) [0|0] "" HMDH_203
 SG_ Ecat_FwdRxError3 m31 : 240|8@1+ (1,0) [0|0] "" HMDH_203
 SG_ Ecat_PuError m31 : 248|8@1+ (1,0) [0|0] "" HMDH_203
 SG_ Ecat_PdiError m31 : 256|8@1+ (1,0) [0|0] "" HMDH_203
 SG_ Ecat_LostLink0 m31 : 264|8@1+ (1,0) [0|0] "" HMDH_203
 SG_ Ecat_LostLink1 m31 : 272|8@1+ (1,0) [0|0] "" HMDH_203
 SG_ Ecat_LostLink2 m31 : 280|8@1+ (1,0) [0|0] "" HMDH_203
 SG_ Ecat_LostLink3 m31 : 288|8@1+ (1,0) [0|0] "" HMDH_203
 SG_ Saf_CanId m32 : 8|8@1+ (1,0) [0|0] "" HMDH_203
 SG_ Saf_Name0 m32 : 16|8@1+ (1,0) [0|0] "" HMDH_203
 SG_ Saf_Name1 m32 : 24|8@1+ (1,0) [0|0] "" HMDH_203
 SG_ Saf_Name2 m32 : 32|8@1+ (1,0) [0|0] "" HMDH_203
 SG_ Saf_Name3 m32 : 40|8@1+ (1,0) [0|0] "" HMDH_203
 SG_ Saf_Name4 m32 : 48|8@1+ (1,0) [0|0] "" HMDH_203
 SG_ Saf_Name5 m32 : 56|8@1+ (1,0) [0|0] "" HMDH_203
 SG_ Saf_Name6 m32 : 64|8@1+ (1,0) [0|0] "" HMDH_203
 SG_ Saf_Name7 m32 : 72|8@1+ (1,0) [0|0] "" HMDH_203
 SG_ Saf_Name8 m32 : 80|8@1+ (1,0) [0|0] "" HMDH_203
 SG_ Saf_Name9 m32 : 88|8@1+ (1,0) [0|0] "" HMDH_203
 SG_ Saf_Name10 m32 : 96|8@1+ (1,0) [0|0] "" HMDH_203
 SG_ Saf_Name11 m32 : 104|8@1+ (1,0) [0|0] "" HMDH_203
 SG_ Saf_Name12 m32 : 112|8@1+ (1,0) [0|0] "" HMDH_203
 SG_ Saf_Name13 m32 : 120|8@1+ (1,0) [0|0] "" HMDH_203
 SG_ Saf_Name14 m32 : 128|8@1+ (1,0) [0|0] "" HMDH_203
 SG_ Saf_Name15 m32 : 136|8@1+ (1,0) [0|0] "" HMDH_203
 SG_ Saf_State m32 : 144|8@1+ (1,0) [0|0] "" HMDH_203
 SG_ Saf_Bits m32 : 152|16@1+ (1,0) [0|0] "" HMDH_203
 SG_ Saf_Estop m32 : 168|8@1+ (1,0) [0|0] "" HMDH_203
 SG_ Saf_FatalLatched m32 : 176|16@1+ (1,0) [0|0] "" HMDH_203
 SG_ Saf_ErrCode m32 : 192|32@1+ (1,0) [0|0] "" HMDH_203

BO_ 2163306188 STATUS_HETC_M_WST_to_HMDH_204: 48 HETC_M_WST
 SG_ SubCode M : 0|8@1+ (1,0) [0|0] "" HMDH_204
 SG_ Ping_CanId m5 : 8|8@1+ (1,0) [0|0] "" HMDH_204
 SG_ Ping_HostId m5 : 16|8@1+ (1,0) [0|0] "" HMDH_204
 SG_ Ping_Pid m5 : 24|16@1+ (1,0) [0|0] "" HMDH_204
 SG_ Ping_Bid m5 : 40|16@1+ (1,0) [0|0] "" HMDH_204
 SG_ Ping_Mid m5 : 56|16@1+ (1,0) [0|0] "" HMDH_204
 SG_ Ping_VerMajor m5 : 72|8@1+ (1,0) [0|0] "" HMDH_204
 SG_ Ping_VerMinor m5 : 80|8@1+ (1,0) [0|0] "" HMDH_204
 SG_ Ping_VerPatch m5 : 88|8@1+ (1,0) [0|0] "" HMDH_204
 SG_ Ping_Name0 m5 : 96|8@1+ (1,0) [0|0] "" HMDH_204
 SG_ Ping_Name1 m5 : 104|8@1+ (1,0) [0|0] "" HMDH_204
 SG_ Ping_Name2 m5 : 112|8@1+ (1,0) [0|0] "" HMDH_204
 SG_ Ping_Name3 m5 : 120|8@1+ (1,0) [0|0] "" HMDH_204
 SG_ Ping_Name4 m5 : 128|8@1+ (1,0) [0|0] "" HMDH_204
 SG_ Ping_Name5 m5 : 136|8@1+ (1,0) [0|0] "" HMDH_204
 SG_ Ping_Name6 m5 : 144|8@1+ (1,0) [0|0] "" HMDH_204
 SG_ Ping_Name7 m5 : 152|8@1+ (1,0) [0|0] "" HMDH_204
 SG_ Ping_Name8 m5 : 160|8@1+ (1,0) [0|0] "" HMDH_204
 SG_ Ping_Name9 m5 : 168|8@1+ (1,0) [0|0] "" HMDH_204
 SG_ Ping_Name10 m5 : 176|8@1+ (1,0) [0|0] "" HMDH_204
 SG_ Ping_Name11 m5 : 184|8@1+ (1,0) [0|0] "" HMDH_204
 SG_ Ping_Name12 m5 : 192|8@1+ (1,0) [0|0] "" HMDH_204
 SG_ Ping_Name13 m5 : 200|8@1+ (1,0) [0|0] "" HMDH_204
 SG_ Ping_Name14 m5 : 208|8@1+ (1,0) [0|0] "" HMDH_204
 SG_ Ping_Name15 m5 : 216|8@1+ (1,0) [0|0] "" HMDH_204
 SG_ Ping_FmtVer m5 : 224|8@1+ (1,0) [0|0] "" HMDH_204
 SG_ Ping_GitRev m5 : 232|32@1+ (1,0) [0|0] "" HMDH_204
 SG_ Ping_FwCrc m5 : 264|16@1+ (1,0) [0|0] "" HMDH_204
 SG_ Ping_UptimeS m5 : 280|16@1+ (1,0) [0|0] "s" HMDH_204
 SG_ Ecat_CanId m31 : 8|8@1+ (1,0) [0|0] "" HMDH_204
 SG_ Ecat_Name0 m31 : 16|8@1+ (1,0) [0|0] "" HMDH_204
 SG_ Ecat_Name1 m31 : 24|8@1+ (1,0) [0|0] "" HMDH_204
 SG_ Ecat_Name2 m31 : 32|8@1+ (1,0) [0|0] "" HMDH_204
 SG_ Ecat_Name3 m31 : 40|8@1+ (1,0) [0|0] "" HMDH_204
 SG_ Ecat_Name4 m31 : 48|8@1+ (1,0) [0|0] "" HMDH_204
 SG_ Ecat_Name5 m31 : 56|8@1+ (1,0) [0|0] "" HMDH_204
 SG_ Ecat_Name6 m31 : 64|8@1+ (1,0) [0|0] "" HMDH_204
 SG_ Ecat_Name7 m31 : 72|8@1+ (1,0) [0|0] "" HMDH_204
 SG_ Ecat_Name8 m31 : 80|8@1+ (1,0) [0|0] "" HMDH_204
 SG_ Ecat_Name9 m31 : 88|8@1+ (1,0) [0|0] "" HMDH_204
 SG_ Ecat_Name10 m31 : 96|8@1+ (1,0) [0|0] "" HMDH_204
 SG_ Ecat_Name11 m31 : 104|8@1+ (1,0) [0|0] "" HMDH_204
 SG_ Ecat_Name12 m31 : 112|8@1+ (1,0) [0|0] "" HMDH_204
 SG_ Ecat_Name13 m31 : 120|8@1+ (1,0) [0|0] "" HMDH_204
 SG_ Ecat_Name14 m31 : 128|8@1+ (1,0) [0|0] "" HMDH_204
 SG_ Ecat_Name15 m31 : 136|8@1+ (1,0) [0|0] "" HMDH_204
 SG_ Ecat_Link m31 : 144|8@1+ (1,0) [0|0] "" HMDH_204
 SG_ Ecat_InvalidFrame0 m31 : 152|8@1+ (1,0) [0|0] "" HMDH_204
 SG_ Ecat_InvalidFrame1 m31 : 160|8@1+ (1,0) [0|0] "" HMDH_204
 SG_ Ecat_InvalidFrame2 m31 : 168|8@1+ (1,0) [0|0] "" HMDH_204
 SG_ Ecat_InvalidFrame3 m31 : 176|8@1+ (1,0) [0|0] "" HMDH_204
 SG_ Ecat_RxError0 m31 : 184|8@1+ (1,0) [0|0] "" HMDH_204
 SG_ Ecat_RxError1 m31 : 192|8@1+ (1,0) [0|0] "" HMDH_204
 SG_ Ecat_RxError2 m31 : 200|8@1+ (1,0) [0|0] "" HMDH_204
 SG_ Ecat_RxError3 m31 : 208|8@1+ (1,0) [0|0] "" HMDH_204
 SG_ Ecat_FwdRxError0 m31 : 216|8@1+ (1,0) [0|0] "" HMDH_204
 SG_ Ecat_FwdRxError1 m31 : 224|8@1+ (1,0) [0|0] "" HMDH_204
 SG_ Ecat_FwdRxError2 m31 : 232|8@1+ (1,0) [0|0] "" HMDH_204
 SG_ Ecat_FwdRxError3 m31 : 240|8@1+ (1,0) [0|0] "" HMDH_204
 SG_ Ecat_PuError m31 : 248|8@1+ (1,0) [0|0] "" HMDH_204
 SG_ Ecat_PdiError m31 : 256|8@1+ (1,0) [0|0] "" HMDH_204
 SG_ Ecat_LostLink0 m31 : 264|8@1+ (1,0) [0|0] "" HMDH_204
 SG_ Ecat_LostLink1 m31 : 272|8@1+ (1,0) [0|0] "" HMDH_204
 SG_ Ecat_LostLink2 m31 : 280|8@1+ (1,0) [0|0] "" HMDH_204
 SG_ Ecat_LostLink3 m31 : 288|8@1+ (1,0) [0|0] "" HMDH_204
 SG_ Saf_CanId m32 : 8|8@1+ (1,0) [0|0] "" HMDH_204
 SG_ Saf_Name0 m32 : 16|8@1+ (1,0) [0|0] "" HMDH_204
 SG_ Saf_Name1 m32 : 24|8@1+ (1,0) [0|0] "" HMDH_204
 SG_ Saf_Name2 m32 : 32|8@1+ (1,0) [0|0] "" HMDH_204
 SG_ Saf_Name3 m32 : 40|8@1+ (1,0) [0|0] "" HMDH_204
 SG_ Saf_Name4 m32 : 48|8@1+ (1,0) [0|0] "" HMDH_204
 SG_ Saf_Name5 m32 : 56|8@1+ (1,0) [0|0] "" HMDH_204
 SG_ Saf_Name6 m32 : 64|8@1+ (1,0) [0|0] "" HMDH_204
 SG_ Saf_Name7 m32 : 72|8@1+ (1,0) [0|0] "" HMDH_204
 SG_ Saf_Name8 m32 : 80|8@1+ (1,0) [0|0] "" HMDH_204
 SG_ Saf_Name9 m32 : 88|8@1+ (1,0) [0|0] "" HMDH_204
 SG_ Saf_Name10 m32 : 96|8@1+ (1,0) [0|0] "" HMDH_204
 SG_ Saf_Name11 m32 : 104|8@1+ (1,0) [0|0] "" HMDH_204
 SG_ Saf_Name12 m32 : 112|8@1+ (1,0) [0|0] "" HMDH_204
 SG_ Saf_Name13 m32 : 120|8@1+ (1,0) [0|0] "" HMDH_204
 SG_ Saf_Name14 m32 : 128|8@1+ (1,0) [0|0] "" HMDH_204
 SG_ Saf_Name15 m32 : 136|8@1+ (1,0) [0|0] "" HMDH_204
 SG_ Saf_State m32 : 144|8@1+ (1,0) [0|0] "" HMDH_204
 SG_ Saf_Bits m32 : 152|16@1+ (1,0) [0|0] "" HMDH_204
 SG_ Saf_Estop m32 : 168|8@1+ (1,0) [0|0] "" HMDH_204
 SG_ Saf_FatalLatched m32 : 176|16@1+ (1,0) [0|0] "" HMDH_204
 SG_ Saf_ErrCode m32 : 192|32@1+ (1,0) [0|0] "" HMDH_204

BO_ 2163306189 STATUS_HETC_M_WST_to_HMDH_205: 48 HETC_M_WST
 SG_ SubCode M : 0|8@1+ (1,0) [0|0] "" HMDH_205
 SG_ Ping_CanId m5 : 8|8@1+ (1,0) [0|0] "" HMDH_205
 SG_ Ping_HostId m5 : 16|8@1+ (1,0) [0|0] "" HMDH_205
 SG_ Ping_Pid m5 : 24|16@1+ (1,0) [0|0] "" HMDH_205
 SG_ Ping_Bid m5 : 40|16@1+ (1,0) [0|0] "" HMDH_205
 SG_ Ping_Mid m5 : 56|16@1+ (1,0) [0|0] "" HMDH_205
 SG_ Ping_VerMajor m5 : 72|8@1+ (1,0) [0|0] "" HMDH_205
 SG_ Ping_VerMinor m5 : 80|8@1+ (1,0) [0|0] "" HMDH_205
 SG_ Ping_VerPatch m5 : 88|8@1+ (1,0) [0|0] "" HMDH_205
 SG_ Ping_Name0 m5 : 96|8@1+ (1,0) [0|0] "" HMDH_205
 SG_ Ping_Name1 m5 : 104|8@1+ (1,0) [0|0] "" HMDH_205
 SG_ Ping_Name2 m5 : 112|8@1+ (1,0) [0|0] "" HMDH_205
 SG_ Ping_Name3 m5 : 120|8@1+ (1,0) [0|0] "" HMDH_205
 SG_ Ping_Name4 m5 : 128|8@1+ (1,0) [0|0] "" HMDH_205
 SG_ Ping_Name5 m5 : 136|8@1+ (1,0) [0|0] "" HMDH_205
 SG_ Ping_Name6 m5 : 144|8@1+ (1,0) [0|0] "" HMDH_205
 SG_ Ping_Name7 m5 : 152|8@1+ (1,0) [0|0] "" HMDH_205
 SG_ Ping_Name8 m5 : 160|8@1+ (1,0) [0|0] "" HMDH_205
 SG_ Ping_Name9 m5 : 168|8@1+ (1,0) [0|0] "" HMDH_205
 SG_ Ping_Name10 m5 : 176|8@1+ (1,0) [0|0] "" HMDH_205
 SG_ Ping_Name11 m5 : 184|8@1+ (1,0) [0|0] "" HMDH_205
 SG_ Ping_Name12 m5 : 192|8@1+ (1,0) [0|0] "" HMDH_205
 SG_ Ping_Name13 m5 : 200|8@1+ (1,0) [0|0] "" HMDH_205
 SG_ Ping_Name14 m5 : 208|8@1+ (1,0) [0|0] "" HMDH_205
 SG_ Ping_Name15 m5 : 216|8@1+ (1,0) [0|0] "" HMDH_205
 SG_ Ping_FmtVer m5 : 224|8@1+ (1,0) [0|0] "" HMDH_205
 SG_ Ping_GitRev m5 : 232|32@1+ (1,0) [0|0] "" HMDH_205
 SG_ Ping_FwCrc m5 : 264|16@1+ (1,0) [0|0] "" HMDH_205
 SG_ Ping_UptimeS m5 : 280|16@1+ (1,0) [0|0] "s" HMDH_205
 SG_ Ecat_CanId m31 : 8|8@1+ (1,0) [0|0] "" HMDH_205
 SG_ Ecat_Name0 m31 : 16|8@1+ (1,0) [0|0] "" HMDH_205
 SG_ Ecat_Name1 m31 : 24|8@1+ (1,0) [0|0] "" HMDH_205
 SG_ Ecat_Name2 m31 : 32|8@1+ (1,0) [0|0] "" HMDH_205
 SG_ Ecat_Name3 m31 : 40|8@1+ (1,0) [0|0] "" HMDH_205
 SG_ Ecat_Name4 m31 : 48|8@1+ (1,0) [0|0] "" HMDH_205
 SG_ Ecat_Name5 m31 : 56|8@1+ (1,0) [0|0] "" HMDH_205
 SG_ Ecat_Name6 m31 : 64|8@1+ (1,0) [0|0] "" HMDH_205
 SG_ Ecat_Name7 m31 : 72|8@1+ (1,0) [0|0] "" HMDH_205
 SG_ Ecat_Name8 m31 : 80|8@1+ (1,0) [0|0] "" HMDH_205
 SG_ Ecat_Name9 m31 : 88|8@1+ (1,0) [0|0] "" HMDH_205
 SG_ Ecat_Name10 m31 : 96|8@1+ (1,0) [0|0] "" HMDH_205
 SG_ Ecat_Name11 m31 : 104|8@1+ (1,0) [0|0] "" HMDH_205
 SG_ Ecat_Name12 m31 : 112|8@1+ (1,0) [0|0] "" HMDH_205
 SG_ Ecat_Name13 m31 : 120|8@1+ (1,0) [0|0] "" HMDH_205
 SG_ Ecat_Name14 m31 : 128|8@1+ (1,0) [0|0] "" HMDH_205
 SG_ Ecat_Name15 m31 : 136|8@1+ (1,0) [0|0] "" HMDH_205
 SG_ Ecat_Link m31 : 144|8@1+ (1,0) [0|0] "" HMDH_205
 SG_ Ecat_InvalidFrame0 m31 : 152|8@1+ (1,0) [0|0] "" HMDH_205
 SG_ Ecat_InvalidFrame1 m31 : 160|8@1+ (1,0) [0|0] "" HMDH_205
 SG_ Ecat_InvalidFrame2 m31 : 168|8@1+ (1,0) [0|0] "" HMDH_205
 SG_ Ecat_InvalidFrame3 m31 : 176|8@1+ (1,0) [0|0] "" HMDH_205
 SG_ Ecat_RxError0 m31 : 184|8@1+ (1,0) [0|0] "" HMDH_205
 SG_ Ecat_RxError1 m31 : 192|8@1+ (1,0) [0|0] "" HMDH_205
 SG_ Ecat_RxError2 m31 : 200|8@1+ (1,0) [0|0] "" HMDH_205
 SG_ Ecat_RxError3 m31 : 208|8@1+ (1,0) [0|0] "" HMDH_205
 SG_ Ecat_FwdRxError0 m31 : 216|8@1+ (1,0) [0|0] "" HMDH_205
 SG_ Ecat_FwdRxError1 m31 : 224|8@1+ (1,0) [0|0] "" HMDH_205
 SG_ Ecat_FwdRxError2 m31 : 232|8@1+ (1,0) [0|0] "" HMDH_205
 SG_ Ecat_FwdRxError3 m31 : 240|8@1+ (1,0) [0|0] "" HMDH_205
 SG_ Ecat_PuError m31 : 248|8@1+ (1,0) [0|0] "" HMDH_205
 SG_ Ecat_PdiError m31 : 256|8@1+ (1,0) [0|0] "" HMDH_205
 SG_ Ecat_LostLink0 m31 : 264|8@1+ (1,0) [0|0] "" HMDH_205
 SG_ Ecat_LostLink1 m31 : 272|8@1+ (1,0) [0|0] "" HMDH_205
 SG_ Ecat_LostLink2 m31 : 280|8@1+ (1,0) [0|0] "" HMDH_205
 SG_ Ecat_LostLink3 m31 : 288|8@1+ (1,0) [0|0] "" HMDH_205
 SG_ Saf_CanId m32 : 8|8@1+ (1,0) [0|0] "" HMDH_205
 SG_ Saf_Name0 m32 : 16|8@1+ (1,0) [0|0] "" HMDH_205
 SG_ Saf_Name1 m32 : 24|8@1+ (1,0) [0|0] "" HMDH_205
 SG_ Saf_Name2 m32 : 32|8@1+ (1,0) [0|0] "" HMDH_205
 SG_ Saf_Name3 m32 : 40|8@1+ (1,0) [0|0] "" HMDH_205
 SG_ Saf_Name4 m32 : 48|8@1+ (1,0) [0|0] "" HMDH_205
 SG_ Saf_Name5 m32 : 56|8@1+ (1,0) [0|0] "" HMDH_205
 SG_ Saf_Name6 m32 : 64|8@1+ (1,0) [0|0] "" HMDH_205
 SG_ Saf_Name7 m32 : 72|8@1+ (1,0) [0|0] "" HMDH_205
 SG_ Saf_Name8 m32 : 80|8@1+ (1,0) [0|0] "" HMDH_205
 SG_ Saf_Name9 m32 : 88|8@1+ (1,0) [0|0] "" HMDH_205
 SG_ Saf_Name10 m32 : 96|8@1+ (1,0) [0|0] "" HMDH_205
 SG_ Saf_Name11 m32 : 104|8@1+ (1,0) [0|0] "" HMDH_205
 SG_ Saf_Name12 m32 : 112|8@1+ (1,0) [0|0] "" HMDH_205
 SG_ Saf_Name13 m32 : 120|8@1+ (1,0) [0|0] "" HMDH_205
 SG_ Saf_Name14 m32 : 128|8@1+ (1,0) [0|0] "" HMDH_205
 SG_ Saf_Name15 m32 : 136|8@1+ (1,0) [0|0] "" HMDH_205
 SG_ Saf_State m32 : 144|8@1+ (1,0) [0|0] "" HMDH_205
 SG_ Saf_Bits m32 : 152|16@1+ (1,0) [0|0] "" HMDH_205
 SG_ Saf_Estop m32 : 168|8@1+ (1,0) [0|0] "" HMDH_205
 SG_ Saf_FatalLatched m32 : 176|16@1+ (1,0) [0|0] "" HMDH_205
 SG_ Saf_ErrCode m32 : 192|32@1+ (1,0) [0|0] "" HMDH_205

BO_ 2163306190 STATUS_HETC_M_WST_to_HMDH_206: 48 HETC_M_WST
 SG_ SubCode M : 0|8@1+ (1,0) [0|0] "" HMDH_206
 SG_ Ping_CanId m5 : 8|8@1+ (1,0) [0|0] "" HMDH_206
 SG_ Ping_HostId m5 : 16|8@1+ (1,0) [0|0] "" HMDH_206
 SG_ Ping_Pid m5 : 24|16@1+ (1,0) [0|0] "" HMDH_206
 SG_ Ping_Bid m5 : 40|16@1+ (1,0) [0|0] "" HMDH_206
 SG_ Ping_Mid m5 : 56|16@1+ (1,0) [0|0] "" HMDH_206
 SG_ Ping_VerMajor m5 : 72|8@1+ (1,0) [0|0] "" HMDH_206
 SG_ Ping_VerMinor m5 : 80|8@1+ (1,0) [0|0] "" HMDH_206
 SG_ Ping_VerPatch m5 : 88|8@1+ (1,0) [0|0] "" HMDH_206
 SG_ Ping_Name0 m5 : 96|8@1+ (1,0) [0|0] "" HMDH_206
 SG_ Ping_Name1 m5 : 104|8@1+ (1,0) [0|0] "" HMDH_206
 SG_ Ping_Name2 m5 : 112|8@1+ (1,0) [0|0] "" HMDH_206
 SG_ Ping_Name3 m5 : 120|8@1+ (1,0) [0|0] "" HMDH_206
 SG_ Ping_Name4 m5 : 128|8@1+ (1,0) [0|0] "" HMDH_206
 SG_ Ping_Name5 m5 : 136|8@1+ (1,0) [0|0] "" HMDH_206
 SG_ Ping_Name6 m5 : 144|8@1+ (1,0) [0|0] "" HMDH_206
 SG_ Ping_Name7 m5 : 152|8@1+ (1,0) [0|0] "" HMDH_206
 SG_ Ping_Name8 m5 : 160|8@1+ (1,0) [0|0] "" HMDH_206
 SG_ Ping_Name9 m5 : 168|8@1+ (1,0) [0|0] "" HMDH_206
 SG_ Ping_Name10 m5 : 176|8@1+ (1,0) [0|0] "" HMDH_206
 SG_ Ping_Name11 m5 : 184|8@1+ (1,0) [0|0] "" HMDH_206
 SG_ Ping_Name12 m5 : 192|8@1+ (1,0) [0|0] "" HMDH_206
 SG_ Ping_Name13 m5 : 200|8@1+ (1,0) [0|0] "" HMDH_206
 SG_ Ping_Name14 m5 : 208|8@1+ (1,0) [0|0] "" HMDH_206
 SG_ Ping_Name15 m5 : 216|8@1+ (1,0) [0|0] "" HMDH_206
 SG_ Ping_FmtVer m5 : 224|8@1+ (1,0) [0|0] "" HMDH_206
 SG_ Ping_GitRev m5 : 232|32@1+ (1,0) [0|0] "" HMDH_206
 SG_ Ping_FwCrc m5 : 264|16@1+ (1,0) [0|0] "" HMDH_206
 SG_ Ping_UptimeS m5 : 280|16@1+ (1,0) [0|0] "s" HMDH_206
 SG_ Ecat_CanId m31 : 8|8@1+ (1,0) [0|0] "" HMDH_206
 SG_ Ecat_Name0 m31 : 16|8@1+ (1,0) [0|0] "" HMDH_206
 SG_ Ecat_Name1 m31 : 24|8@1+ (1,0) [0|0] "" HMDH_206
 SG_ Ecat_Name2 m31 : 32|8@1+ (1,0) [0|0] "" HMDH_206
 SG_ Ecat_Name3 m31 : 40|8@1+ (1,0) [0|0] "" HMDH_206
 SG_ Ecat_Name4 m31 : 48|8@1+ (1,0) [0|0] "" HMDH_206
 SG_ Ecat_Name5 m31 : 56|8@1+ (1,0) [0|0] "" HMDH_206
 SG_ Ecat_Name6 m31 : 64|8@1+ (1,0) [0|0] "" HMDH_206
 SG_ Ecat_Name7 m31 : 72|8@1+ (1,0) [0|0] "" HMDH_206
 SG_ Ecat_Name8 m31 : 80|8@1+ (1,0) [0|0] "" HMDH_206
 SG_ Ecat_Name9 m31 : 88|8@1+ (1,0) [0|0] "" HMDH_206
 SG_ Ecat_Name10 m31 : 96|8@1+ (1,0) [0|0] "" HMDH_206
 SG_ Ecat_Name11 m31 : 104|8@1+ (1,0) [0|0] "" HMDH_206
 SG_ Ecat_Name12 m31 : 112|8@1+ (1,0) [0|0] "" HMDH_206
 SG_ Ecat_Name13 m31 : 120|8@1+ (1,0) [0|0] "" HMDH_206
 SG_ Ecat_Name14 m31 : 128|8@1+ (1,0) [0|0] "" HMDH_206
 SG_ Ecat_Name15 m31 : 136|8@1+ (1,0) [0|0] "" HMDH_206
 SG_ Ecat_Link m31 : 144|8@1+ (1,0) [0|0] "" HMDH_206
 SG_ Ecat_InvalidFrame0 m31 : 152|8@1+ (1,0) [0|0] "" HMDH_206
 SG_ Ecat_InvalidFrame1 m31 : 160|8@1+ (1,0) [0|0] "" HMDH_206
 SG_ Ecat_InvalidFrame2 m31 : 168|8@1+ (1,0) [0|0] "" HMDH_206
 SG_ Ecat_InvalidFrame3 m31 : 176|8@1+ (1,0) [0|0] "" HMDH_206
 SG_ Ecat_RxError0 m31 : 184|8@1+ (1,0) [0|0] "" HMDH_206
 SG_ Ecat_RxError1 m31 : 192|8@1+ (1,0) [0|0] "" HMDH_206
 SG_ Ecat_RxError2 m31 : 200|8@1+ (1,0) [0|0] "" HMDH_206
 SG_ Ecat_RxError3 m31 : 208|8@1+ (1,0) [0|0] "" HMDH_206
 SG_ Ecat_FwdRxError0 m31 : 216|8@1+ (1,0) [0|0] "" HMDH_206
 SG_ Ecat_FwdRxError1 m31 : 224|8@1+ (1,0) [0|0] "" HMDH_206
 SG_ Ecat_FwdRxError2 m31 : 232|8@1+ (1,0) [0|0] "" HMDH_206
 SG_ Ecat_FwdRxError3 m31 : 240|8@1+ (1,0) [0|0] "" HMDH_206
 SG_ Ecat_PuError m31 : 248|8@1+ (1,0) [0|0] "" HMDH_206
 SG_ Ecat_PdiError m31 : 256|8@1+ (1,0) [0|0] "" HMDH_206
 SG_ Ecat_LostLink0 m31 : 264|8@1+ (1,0) [0|0] "" HMDH_206
 SG_ Ecat_LostLink1 m31 : 272|8@1+ (1,0) [0|0] "" HMDH_206
 SG_ Ecat_LostLink2 m31 : 280|8@1+ (1,0) [0|0] "" HMDH_206
 SG_ Ecat_LostLink3 m31 : 288|8@1+ (1,0) [0|0] "" HMDH_206
 SG_ Saf_CanId m32 : 8|8@1+ (1,0) [0|0] "" HMDH_206
 SG_ Saf_Name0 m32 : 16|8@1+ (1,0) [0|0] "" HMDH_206
 SG_ Saf_Name1 m32 : 24|8@1+ (1,0) [0|0] "" HMDH_206
 SG_ Saf_Name2 m32 : 32|8@1+ (1,0) [0|0] "" HMDH_206
 SG_ Saf_Name3 m32 : 40|8@1+ (1,0) [0|0] "" HMDH_206
 SG_ Saf_Name4 m32 : 48|8@1+ (1,0) [0|0] "" HMDH_206
 SG_ Saf_Name5 m32 : 56|8@1+ (1,0) [0|0] "" HMDH_206
 SG_ Saf_Name6 m32 : 64|8@1+ (1,0) [0|0] "" HMDH_206
 SG_ Saf_Name7 m32 : 72|8@1+ (1,0) [0|0] "" HMDH_206
 SG_ Saf_Name8 m32 : 80|8@1+ (1,0) [0|0] "" HMDH_206
 SG_ Saf_Name9 m32 : 88|8@1+ (1,0) [0|0] "" HMDH_206
 SG_ Saf_Name10 m32 : 96|8@1+ (1,0) [0|0] "" HMDH_206
 SG_ Saf_Name11 m32 : 104|8@1+ (1,0) [0|0] "" HMDH_206
 SG_ Saf_Name12 m32 : 112|8@1+ (1,0) [0|0] "" HMDH_206
 SG_ Saf_Name13 m32 : 120|8@1+ (1,0) [0|0] "" HMDH_206
 SG_ Saf_Name14 m32 : 128|8@1+ (1,0) [0|0] "" HMDH_206
 SG_ Saf_Name15 m32 : 136|8@1+ (1,0) [0|0] "" HMDH_206
 SG_ Saf_State m32 : 144|8@1+ (1,0) [0|0] "" HMDH_206
 SG_ Saf_Bits m32 : 152|16@1+ (1,0) [0|0] "" HMDH_206
 SG_ Saf_Estop m32 : 168|8@1+ (1,0) [0|0] "" HMDH_206
 SG_ Saf_FatalLatched m32 : 176|16@1+ (1,0) [0|0] "" HMDH_206
 SG_ Saf_ErrCode m32 : 192|32@1+ (1,0) [0|0] "" HMDH_206

BO_ 2163306191 STATUS_HETC_M_WST_to_HMDH_207: 48 HETC_M_WST
 SG_ SubCode M : 0|8@1+ (1,0) [0|0] "" HMDH_207
 SG_ Ping_CanId m5 : 8|8@1+ (1,0) [0|0] "" HMDH_207
 SG_ Ping_HostId m5 : 16|8@1+ (1,0) [0|0] "" HMDH_207
 SG_ Ping_Pid m5 : 24|16@1+ (1,0) [0|0] "" HMDH_207
 SG_ Ping_Bid m5 : 40|16@1+ (1,0) [0|0] "" HMDH_207
 SG_ Ping_Mid m5 : 56|16@1+ (1,0) [0|0] "" HMDH_207
 SG_ Ping_VerMajor m5 : 72|8@1+ (1,0) [0|0] "" HMDH_207
 SG_ Ping_VerMinor m5 : 80|8@1+ (1,0) [0|0] "" HMDH_207
 SG_ Ping_VerPatch m5 : 88|8@1+ (1,0) [0|0] "" HMDH_207
 SG_ Ping_Name0 m5 : 96|8@1+ (1,0) [0|0] "" HMDH_207
 SG_ Ping_Name1 m5 : 104|8@1+ (1,0) [0|0] "" HMDH_207
 SG_ Ping_Name2 m5 : 112|8@1+ (1,0) [0|0] "" HMDH_207
 SG_ Ping_Name3 m5 : 120|8@1+ (1,0) [0|0] "" HMDH_207
 SG_ Ping_Name4 m5 : 128|8@1+ (1,0) [0|0] "" HMDH_207
 SG_ Ping_Name5 m5 : 136|8@1+ (1,0) [0|0] "" HMDH_207
 SG_ Ping_Name6 m5 : 144|8@1+ (1,0) [0|0] "" HMDH_207
 SG_ Ping_Name7 m5 : 152|8@1+ (1,0) [0|0] "" HMDH_207
 SG_ Ping_Name8 m5 : 160|8@1+ (1,0) [0|0] "" HMDH_207
 SG_ Ping_Name9 m5 : 168|8@1+ (1,0) [0|0] "" HMDH_207
 SG_ Ping_Name10 m5 : 176|8@1+ (1,0) [0|0] "" HMDH_207
 SG_ Ping_Name11 m5 : 184|8@1+ (1,0) [0|0] "" HMDH_207
 SG_ Ping_Name12 m5 : 192|8@1+ (1,0) [0|0] "" HMDH_207
 SG_ Ping_Name13 m5 : 200|8@1+ (1,0) [0|0] "" HMDH_207
 SG_ Ping_Name14 m5 : 208|8@1+ (1,0) [0|0] "" HMDH_207
 SG_ Ping_Name15 m5 : 216|8@1+ (1,0) [0|0] "" HMDH_207
 SG_ Ping_FmtVer m5 : 224|8@1+ (1,0) [0|0] "" HMDH_207
 SG_ Ping_GitRev m5 : 232|32@1+ (1,0) [0|0] "" HMDH_207
 SG_ Ping_FwCrc m5 : 264|16@1+ (1,0) [0|0] "" HMDH_207
 SG_ Ping_UptimeS m5 : 280|16@1+ (1,0) [0|0] "s" HMDH_207
 SG_ Ecat_CanId m31 : 8|8@1+ (1,0) [0|0] "" HMDH_207
 SG_ Ecat_Name0 m31 : 16|8@1+ (1,0) [0|0] "" HMDH_207
 SG_ Ecat_Name1 m31 : 24|8@1+ (1,0) [0|0] "" HMDH_207
 SG_ Ecat_Name2 m31 : 32|8@1+ (1,0) [0|0] "" HMDH_207
 SG_ Ecat_Name3 m31 : 40|8@1+ (1,0) [0|0] "" HMDH_207
 SG_ Ecat_Name4 m31 : 48|8@1+ (1,0) [0|0] "" HMDH_207
 SG_ Ecat_Name5 m31 : 56|8@1+ (1,0) [0|0] "" HMDH_207
 SG_ Ecat_Name6 m31 : 64|8@1+ (1,0) [0|0] "" HMDH_207
 SG_ Ecat_Name7 m31 : 72|8@1+ (1,0) [0|0] "" HMDH_207
 SG_ Ecat_Name8 m31 : 80|8@1+ (1,0) [0|0] "" HMDH_207
 SG_ Ecat_Name9 m31 : 88|8@1+ (1,0) [0|0] "" HMDH_207
 SG_ Ecat_Name10 m31 : 96|8@1+ (1,0) [0|0] "" HMDH_207
 SG_ Ecat_Name11 m31 : 104|8@1+ (1,0) [0|0] "" HMDH_207
 SG_ Ecat_Name12 m31 : 112|8@1+ (1,0) [0|0] "" HMDH_207
 SG_ Ecat_Name13 m31 : 120|8@1+ (1,0) [0|0] "" HMDH_207
 SG_ Ecat_Name14 m31 : 128|8@1+ (1,0) [0|0] "" HMDH_207
 SG_ Ecat_Name15 m31 : 136|8@1+ (1,0) [0|0] "" HMDH_207
 SG_ Ecat_Link m31 : 144|8@1+ (1,0) [0|0] "" HMDH_207
 SG_ Ecat_InvalidFrame0 m31 : 152|8@1+ (1,0) [0|0] "" HMDH_207
 SG_ Ecat_InvalidFrame1 m31 : 160|8@1+ (1,0) [0|0] "" HMDH_207
 SG_ Ecat_InvalidFrame2 m31 : 168|8@1+ (1,0) [0|0] "" HMDH_207
 SG_ Ecat_InvalidFrame3 m31 : 176|8@1+ (1,0) [0|0] "" HMDH_207
 SG_ Ecat_RxError0 m31 : 184|8@1+ (1,0) [0|0] "" HMDH_207
 SG_ Ecat_RxError1 m31 : 192|8@1+ (1,0) [0|0] "" HMDH_207
 SG_ Ecat_RxError2 m31 : 200|8@1+ (1,0) [0|0] "" HMDH_207
 SG_ Ecat_RxError3 m31 : 208|8@1+ (1,0) [0|0] "" HMDH_207
 SG_ Ecat_FwdRxError0 m31 : 216|8@1+ (1,0) [0|0] "" HMDH_207
 SG_ Ecat_FwdRxError1 m31 : 224|8@1+ (1,0) [0|0] "" HMDH_207
 SG_ Ecat_FwdRxError2 m31 : 232|8@1+ (1,0) [0|0] "" HMDH_207
 SG_ Ecat_FwdRxError3 m31 : 240|8@1+ (1,0) [0|0] "" HMDH_207
 SG_ Ecat_PuError m31 : 248|8@1+ (1,0) [0|0] "" HMDH_207
 SG_ Ecat_PdiError m31 : 256|8@1+ (1,0) [0|0] "" HMDH_207
 SG_ Ecat_LostLink0 m31 : 264|8@1+ (1,0) [0|0] "" HMDH_207
 SG_ Ecat_LostLink1 m31 : 272|8@1+ (1,0) [0|0] "" HMDH_207
 SG_ Ecat_LostLink2 m31 : 280|8@1+ (1,0) [0|0] "" HMDH_207
 SG_ Ecat_LostLink3 m31 : 288|8@1+ (1,0) [0|0] "" HMDH_207
 SG_ Saf_CanId m32 : 8|8@1+ (1,0) [0|0] "" HMDH_207
 SG_ Saf_Name0 m32 : 16|8@1+ (1,0) [0|0] "" HMDH_207
 SG_ Saf_Name1 m32 : 24|8@1+ (1,0) [0|0] "" HMDH_207
 SG_ Saf_Name2 m32 : 32|8@1+ (1,0) [0|0] "" HMDH_207
 SG_ Saf_Name3 m32 : 40|8@1+ (1,0) [0|0] "" HMDH_207
 SG_ Saf_Name4 m32 : 48|8@1+ (1,0) [0|0] "" HMDH_207
 SG_ Saf_Name5 m32 : 56|8@1+ (1,0) [0|0] "" HMDH_207
 SG_ Saf_Name6 m32 : 64|8@1+ (1,0) [0|0] "" HMDH_207
 SG_ Saf_Name7 m32 : 72|8@1+ (1,0) [0|0] "" HMDH_207
 SG_ Saf_Name8 m32 : 80|8@1+ (1,0) [0|0] "" HMDH_207
 SG_ Saf_Name9 m32 : 88|8@1+ (1,0) [0|0] "" HMDH_207
 SG_ Saf_Name10 m32 : 96|8@1+ (1,0) [0|0] "" HMDH_207
 SG_ Saf_Name11 m32 : 104|8@1+ (1,0) [0|0] "" HMDH_207
 SG_ Saf_Name12 m32 : 112|8@1+ (1,0) [0|0] "" HMDH_207
 SG_ Saf_Name13 m32 : 120|8@1+ (1,0) [0|0] "" HMDH_207
 SG_ Saf_Name14 m32 : 128|8@1+ (1,0) [0|0] "" HMDH_207
 SG_ Saf_Name15 m32 : 136|8@1+ (1,0) [0|0] "" HMDH_207
 SG_ Saf_State m32 : 144|8@1+ (1,0) [0|0] "" HMDH_207
 SG_ Saf_Bits m32 : 152|16@1+ (1,0) [0|0] "" HMDH_207
 SG_ Saf_Estop m32 : 168|8@1+ (1,0) [0|0] "" HMDH_207
 SG_ Saf_FatalLatched m32 : 176|16@1+ (1,0) [0|0] "" HMDH_207
 SG_ Saf_ErrCode m32 : 192|32@1+ (1,0) [0|0] "" HMDH_207

BO_ 2163308644 STATUS_HETC_L_ARM_to_HETC_M_MOB: 48 HETC_L_ARM
 SG_ SubCode M : 0|8@1+ (1,0) [0|0] "" HETC_M_MOB
 SG_ Ping_CanId m5 : 8|8@1+ (1,0) [0|0] "" HETC_M_MOB
 SG_ Ping_HostId m5 : 16|8@1+ (1,0) [0|0] "" HETC_M_MOB
 SG_ Ping_Pid m5 : 24|16@1+ (1,0) [0|0] "" HETC_M_MOB
 SG_ Ping_Bid m5 : 40|16@1+ (1,0) [0|0] "" HETC_M_MOB
 SG_ Ping_Mid m5 : 56|16@1+ (1,0) [0|0] "" HETC_M_MOB
 SG_ Ping_VerMajor m5 : 72|8@1+ (1,0) [0|0] "" HETC_M_MOB
 SG_ Ping_VerMinor m5 : 80|8@1+ (1,0) [0|0] "" HETC_M_MOB
 SG_ Ping_VerPatch m5 : 88|8@1+ (1,0) [0|0] "" HETC_M_MOB
 SG_ Ping_Name0 m5 : 96|8@1+ (1,0) [0|0] "" HETC_M_MOB
 SG_ Ping_Name1 m5 : 104|8@1+ (1,0) [0|0] "" HETC_M_MOB
 SG_ Ping_Name2 m5 : 112|8@1+ (1,0) [0|0] "" HETC_M_MOB
 SG_ Ping_Name3 m5 : 120|8@1+ (1,0) [0|0] "" HETC_M_MOB
 SG_ Ping_Name4 m5 : 128|8@1+ (1,0) [0|0] "" HETC_M_MOB
 SG_ Ping_Name5 m5 : 136|8@1+ (1,0) [0|0] "" HETC_M_MOB
 SG_ Ping_Name6 m5 : 144|8@1+ (1,0) [0|0] "" HETC_M_MOB
 SG_ Ping_Name7 m5 : 152|8@1+ (1,0) [0|0] "" HETC_M_MOB
 SG_ Ping_Name8 m5 : 160|8@1+ (1,0) [0|0] "" HETC_M_MOB
 SG_ Ping_Name9 m5 : 168|8@1+ (1,0) [0|0] "" HETC_M_MOB
 SG_ Ping_Name10 m5 : 176|8@1+ (1,0) [0|0] "" HETC_M_MOB
 SG_ Ping_Name11 m5 : 184|8@1+ (1,0) [0|0] "" HETC_M_MOB
 SG_ Ping_Name12 m5 : 192|8@1+ (1,0) [0|0] "" HETC_M_MOB
 SG_ Ping_Name13 m5 : 200|8@1+ (1,0) [0|0] "" HETC_M_MOB
 SG_ Ping_Name14 m5 : 208|8@1+ (1,0) [0|0] "" HETC_M_MOB
 SG_ Ping_Name15 m5 : 216|8@1+ (1,0) [0|0] "" HETC_M_MOB
 SG_ Ping_FmtVer m5 : 224|8@1+ (1,0) [0|0] "" HETC_M_MOB
 SG_ Ping_GitRev m5 : 232|32@1+ (1,0) [0|0] "" HETC_M_MOB
 SG_ Ping_FwCrc m5 : 264|16@1+ (1,0) [0|0] "" HETC_M_MOB
 SG_ Ping_UptimeS m5 : 280|16@1+ (1,0) [0|0] "s" HETC_M_MOB
 SG_ Ecat_CanId m31 : 8|8@1+ (1,0) [0|0] "" HETC_M_MOB
 SG_ Ecat_Name0 m31 : 16|8@1+ (1,0) [0|0] "" HETC_M_MOB
 SG_ Ecat_Name1 m31 : 24|8@1+ (1,0) [0|0] "" HETC_M_MOB
 SG_ Ecat_Name2 m31 : 32|8@1+ (1,0) [0|0] "" HETC_M_MOB
 SG_ Ecat_Name3 m31 : 40|8@1+ (1,0) [0|0] "" HETC_M_MOB
 SG_ Ecat_Name4 m31 : 48|8@1+ (1,0) [0|0] "" HETC_M_MOB
 SG_ Ecat_Name5 m31 : 56|8@1+ (1,0) [0|0] "" HETC_M_MOB
 SG_ Ecat_Name6 m31 : 64|8@1+ (1,0) [0|0] "" HETC_M_MOB
 SG_ Ecat_Name7 m31 : 72|8@1+ (1,0) [0|0] "" HETC_M_MOB
 SG_ Ecat_Name8 m31 : 80|8@1+ (1,0) [0|0] "" HETC_M_MOB
 SG_ Ecat_Name9 m31 : 88|8@1+ (1,0) [0|0] "" HETC_M_MOB
 SG_ Ecat_Name10 m31 : 96|8@1+ (1,0) [0|0] "" HETC_M_MOB
 SG_ Ecat_Name11 m31 : 104|8@1+ (1,0) [0|0] "" HETC_M_MOB
 SG_ Ecat_Name12 m31 : 112|8@1+ (1,0) [0|0] "" HETC_M_MOB
 SG_ Ecat_Name13 m31 : 120|8@1+ (1,0) [0|0] "" HETC_M_MOB
 SG_ Ecat_Name14 m31 : 128|8@1+ (1,0) [0|0] "" HETC_M_MOB
 SG_ Ecat_Name15 m31 : 136|8@1+ (1,0) [0|0] "" HETC_M_MOB
 SG_ Ecat_Link m31 : 144|8@1+ (1,0) [0|0] "" HETC_M_MOB
 SG_ Ecat_InvalidFrame0 m31 : 152|8@1+ (1,0) [0|0] "" HETC_M_MOB
 SG_ Ecat_InvalidFrame1 m31 : 160|8@1+ (1,0) [0|0] "" HETC_M_MOB
 SG_ Ecat_InvalidFrame2 m31 : 168|8@1+ (1,0) [0|0] "" HETC_M_MOB
 SG_ Ecat_InvalidFrame3 m31 : 176|8@1+ (1,0) [0|0] "" HETC_M_MOB
 SG_ Ecat_RxError0 m31 : 184|8@1+ (1,0) [0|0] "" HETC_M_MOB
 SG_ Ecat_RxError1 m31 : 192|8@1+ (1,0) [0|0] "" HETC_M_MOB
 SG_ Ecat_RxError2 m31 : 200|8@1+ (1,0) [0|0] "" HETC_M_MOB
 SG_ Ecat_RxError3 m31 : 208|8@1+ (1,0) [0|0] "" HETC_M_MOB
 SG_ Ecat_FwdRxError0 m31 : 216|8@1+ (1,0) [0|0] "" HETC_M_MOB
 SG_ Ecat_FwdRxError1 m31 : 224|8@1+ (1,0) [0|0] "" HETC_M_MOB
 SG_ Ecat_FwdRxError2 m31 : 232|8@1+ (1,0) [0|0] "" HETC_M_MOB
 SG_ Ecat_FwdRxError3 m31 : 240|8@1+ (1,0) [0|0] "" HETC_M_MOB
 SG_ Ecat_PuError m31 : 248|8@1+ (1,0) [0|0] "" HETC_M_MOB
 SG_ Ecat_PdiError m31 : 256|8@1+ (1,0) [0|0] "" HETC_M_MOB
 SG_ Ecat_LostLink0 m31 : 264|8@1+ (1,0) [0|0] "" HETC_M_MOB
 SG_ Ecat_LostLink1 m31 : 272|8@1+ (1,0) [0|0] "" HETC_M_MOB
 SG_ Ecat_LostLink2 m31 : 280|8@1+ (1,0) [0|0] "" HETC_M_MOB
 SG_ Ecat_LostLink3 m31 : 288|8@1+ (1,0) [0|0] "" HETC_M_MOB
 SG_ Saf_CanId m32 : 8|8@1+ (1,0) [0|0] "" HETC_M_MOB
 SG_ Saf_Name0 m32 : 16|8@1+ (1,0) [0|0] "" HETC_M_MOB
 SG_ Saf_Name1 m32 : 24|8@1+ (1,0) [0|0] "" HETC_M_MOB
 SG_ Saf_Name2 m32 : 32|8@1+ (1,0) [0|0] "" HETC_M_MOB
 SG_ Saf_Name3 m32 : 40|8@1+ (1,0) [0|0] "" HETC_M_MOB
 SG_ Saf_Name4 m32 : 48|8@1+ (1,0) [0|0] "" HETC_M_MOB
 SG_ Saf_Name5 m32 : 56|8@1+ (1,0) [0|0] "" HETC_M_MOB
 SG_ Saf_Name6 m32 : 64|8@1+ (1,0) [0|0] "" HETC_M_MOB
 SG_ Saf_Name7 m32 : 72|8@1+ (1,0) [0|0] "" HETC_M_MOB
 SG_ Saf_Name8 m32 : 80|8@1+ (1,0) [0|0] "" HETC_M_MOB
 SG_ Saf_Name9 m32 : 88|8@1+ (1,0) [0|0] "" HETC_M_MOB
 SG_ Saf_Name10 m32 : 96|8@1+ (1,0) [0|0] "" HETC_M_MOB
 SG_ Saf_Name11 m32 : 104|8@1+ (1,0) [0|0] "" HETC_M_MOB
 SG_ Saf_Name12 m32 : 112|8@1+ (1,0) [0|0] "" HETC_M_MOB
 SG_ Saf_Name13 m32 : 120|8@1+ (1,0) [0|0] "" HETC_M_MOB
 SG_ Saf_Name14 m32 : 128|8@1+ (1,0) [0|0] "" HETC_M_MOB
 SG_ Saf_Name15 m32 : 136|8@1+ (1,0) [0|0] "" HETC_M_MOB
 SG_ Saf_State m32 : 144|8@1+ (1,0) [0|0] "" HETC_M_MOB
 SG_ Saf_Bits m32 : 152|16@1+ (1,0) [0|0] "" HETC_M_MOB
 SG_ Saf_Estop m32 : 168|8@1+ (1,0) [0|0] "" HETC_M_MOB
 SG_ Saf_FatalLatched m32 : 176|16@1+ (1,0) [0|0] "" HETC_M_MOB
 SG_ Saf_ErrCode m32 : 192|32@1+ (1,0) [0|0] "" HETC_M_MOB

BO_ 2163308654 STATUS_HETC_L_ARM_to_HETC_M_WST: 48 HETC_L_ARM
 SG_ SubCode M : 0|8@1+ (1,0) [0|0] "" HETC_M_WST
 SG_ Ping_CanId m5 : 8|8@1+ (1,0) [0|0] "" HETC_M_WST
 SG_ Ping_HostId m5 : 16|8@1+ (1,0) [0|0] "" HETC_M_WST
 SG_ Ping_Pid m5 : 24|16@1+ (1,0) [0|0] "" HETC_M_WST
 SG_ Ping_Bid m5 : 40|16@1+ (1,0) [0|0] "" HETC_M_WST
 SG_ Ping_Mid m5 : 56|16@1+ (1,0) [0|0] "" HETC_M_WST
 SG_ Ping_VerMajor m5 : 72|8@1+ (1,0) [0|0] "" HETC_M_WST
 SG_ Ping_VerMinor m5 : 80|8@1+ (1,0) [0|0] "" HETC_M_WST
 SG_ Ping_VerPatch m5 : 88|8@1+ (1,0) [0|0] "" HETC_M_WST
 SG_ Ping_Name0 m5 : 96|8@1+ (1,0) [0|0] "" HETC_M_WST
 SG_ Ping_Name1 m5 : 104|8@1+ (1,0) [0|0] "" HETC_M_WST
 SG_ Ping_Name2 m5 : 112|8@1+ (1,0) [0|0] "" HETC_M_WST
 SG_ Ping_Name3 m5 : 120|8@1+ (1,0) [0|0] "" HETC_M_WST
 SG_ Ping_Name4 m5 : 128|8@1+ (1,0) [0|0] "" HETC_M_WST
 SG_ Ping_Name5 m5 : 136|8@1+ (1,0) [0|0] "" HETC_M_WST
 SG_ Ping_Name6 m5 : 144|8@1+ (1,0) [0|0] "" HETC_M_WST
 SG_ Ping_Name7 m5 : 152|8@1+ (1,0) [0|0] "" HETC_M_WST
 SG_ Ping_Name8 m5 : 160|8@1+ (1,0) [0|0] "" HETC_M_WST
 SG_ Ping_Name9 m5 : 168|8@1+ (1,0) [0|0] "" HETC_M_WST
 SG_ Ping_Name10 m5 : 176|8@1+ (1,0) [0|0] "" HETC_M_WST
 SG_ Ping_Name11 m5 : 184|8@1+ (1,0) [0|0] "" HETC_M_WST
 SG_ Ping_Name12 m5 : 192|8@1+ (1,0) [0|0] "" HETC_M_WST
 SG_ Ping_Name13 m5 : 200|8@1+ (1,0) [0|0] "" HETC_M_WST
 SG_ Ping_Name14 m5 : 208|8@1+ (1,0) [0|0] "" HETC_M_WST
 SG_ Ping_Name15 m5 : 216|8@1+ (1,0) [0|0] "" HETC_M_WST
 SG_ Ping_FmtVer m5 : 224|8@1+ (1,0) [0|0] "" HETC_M_WST
 SG_ Ping_GitRev m5 : 232|32@1+ (1,0) [0|0] "" HETC_M_WST
 SG_ Ping_FwCrc m5 : 264|16@1+ (1,0) [0|0] "" HETC_M_WST
 SG_ Ping_UptimeS m5 : 280|16@1+ (1,0) [0|0] "s" HETC_M_WST
 SG_ Ecat_CanId m31 : 8|8@1+ (1,0) [0|0] "" HETC_M_WST
 SG_ Ecat_Name0 m31 : 16|8@1+ (1,0) [0|0] "" HETC_M_WST
 SG_ Ecat_Name1 m31 : 24|8@1+ (1,0) [0|0] "" HETC_M_WST
 SG_ Ecat_Name2 m31 : 32|8@1+ (1,0) [0|0] "" HETC_M_WST
 SG_ Ecat_Name3 m31 : 40|8@1+ (1,0) [0|0] "" HETC_M_WST
 SG_ Ecat_Name4 m31 : 48|8@1+ (1,0) [0|0] "" HETC_M_WST
 SG_ Ecat_Name5 m31 : 56|8@1+ (1,0) [0|0] "" HETC_M_WST
 SG_ Ecat_Name6 m31 : 64|8@1+ (1,0) [0|0] "" HETC_M_WST
 SG_ Ecat_Name7 m31 : 72|8@1+ (1,0) [0|0] "" HETC_M_WST
 SG_ Ecat_Name8 m31 : 80|8@1+ (1,0) [0|0] "" HETC_M_WST
 SG_ Ecat_Name9 m31 : 88|8@1+ (1,0) [0|0] "" HETC_M_WST
 SG_ Ecat_Name10 m31 : 96|8@1+ (1,0) [0|0] "" HETC_M_WST
 SG_ Ecat_Name11 m31 : 104|8@1+ (1,0) [0|0] "" HETC_M_WST
 SG_ Ecat_Name12 m31 : 112|8@1+ (1,0) [0|0] "" HETC_M_WST
 SG_ Ecat_Name13 m31 : 120|8@1+ (1,0) [0|0] "" HETC_M_WST
 SG_ Ecat_Name14 m31 : 128|8@1+ (1,0) [0|0] "" HETC_M_WST
 SG_ Ecat_Name15 m31 : 136|8@1+ (1,0) [0|0] "" HETC_M_WST
 SG_ Ecat_Link m31 : 144|8@1+ (1,0) [0|0] "" HETC_M_WST
 SG_ Ecat_InvalidFrame0 m31 : 152|8@1+ (1,0) [0|0] "" HETC_M_WST
 SG_ Ecat_InvalidFrame1 m31 : 160|8@1+ (1,0) [0|0] "" HETC_M_WST
 SG_ Ecat_InvalidFrame2 m31 : 168|8@1+ (1,0) [0|0] "" HETC_M_WST
 SG_ Ecat_InvalidFrame3 m31 : 176|8@1+ (1,0) [0|0] "" HETC_M_WST
 SG_ Ecat_RxError0 m31 : 184|8@1+ (1,0) [0|0] "" HETC_M_WST
 SG_ Ecat_RxError1 m31 : 192|8@1+ (1,0) [0|0] "" HETC_M_WST
 SG_ Ecat_RxError2 m31 : 200|8@1+ (1,0) [0|0] "" HETC_M_WST
 SG_ Ecat_RxError3 m31 : 208|8@1+ (1,0) [0|0] "" HETC_M_WST
 SG_ Ecat_FwdRxError0 m31 : 216|8@1+ (1,0) [0|0] "" HETC_M_WST
 SG_ Ecat_FwdRxError1 m31 : 224|8@1+ (1,0) [0|0] "" HETC_M_WST
 SG_ Ecat_FwdRxError2 m31 : 232|8@1+ (1,0) [0|0] "" HETC_M_WST
 SG_ Ecat_FwdRxError3 m31 : 240|8@1+ (1,0) [0|0] "" HETC_M_WST
 SG_ Ecat_PuError m31 : 248|8@1+ (1,0) [0|0] "" HETC_M_WST
 SG_ Ecat_PdiError m31 : 256|8@1+ (1,0) [0|0] "" HETC_M_WST
 SG_ Ecat_LostLink0 m31 : 264|8@1+ (1,0) [0|0] "" HETC_M_WST
 SG_ Ecat_LostLink1 m31 : 272|8@1+ (1,0) [0|0] "" HETC_M_WST
 SG_ Ecat_LostLink2 m31 : 280|8@1+ (1,0) [0|0] "" HETC_M_WST
 SG_ Ecat_LostLink3 m31 : 288|8@1+ (1,0) [0|0] "" HETC_M_WST
 SG_ Saf_CanId m32 : 8|8@1+ (1,0) [0|0] "" HETC_M_WST
 SG_ Saf_Name0 m32 : 16|8@1+ (1,0) [0|0] "" HETC_M_WST
 SG_ Saf_Name1 m32 : 24|8@1+ (1,0) [0|0] "" HETC_M_WST
 SG_ Saf_Name2 m32 : 32|8@1+ (1,0) [0|0] "" HETC_M_WST
 SG_ Saf_Name3 m32 : 40|8@1+ (1,0) [0|0] "" HETC_M_WST
 SG_ Saf_Name4 m32 : 48|8@1+ (1,0) [0|0] "" HETC_M_WST
 SG_ Saf_Name5 m32 : 56|8@1+ (1,0) [0|0] "" HETC_M_WST
 SG_ Saf_Name6 m32 : 64|8@1+ (1,0) [0|0] "" HETC_M_WST
 SG_ Saf_Name7 m32 : 72|8@1+ (1,0) [0|0] "" HETC_M_WST
 SG_ Saf_Name8 m32 : 80|8@1+ (1,0) [0|0] "" HETC_M_WST
 SG_ Saf_Name9 m32 : 88|8@1+ (1,0) [0|0] "" HETC_M_WST
 SG_ Saf_Name10 m32 : 96|8@1+ (1,0) [0|0] "" HETC_M_WST
 SG_ Saf_Name11 m32 : 104|8@1+ (1,0) [0|0] "" HETC_M_WST
 SG_ Saf_Name12 m32 : 112|8@1+ (1,0) [0|0] "" HETC_M_WST
 SG_ Saf_Name13 m32 : 120|8@1+ (1,0) [0|0] "" HETC_M_WST
 SG_ Saf_Name14 m32 : 128|8@1+ (1,0) [0|0] "" HETC_M_WST
 SG_ Saf_Name15 m32 : 136|8@1+ (1,0) [0|0] "" HETC_M_WST
 SG_ Saf_State m32 : 144|8@1+ (1,0) [0|0] "" HETC_M_WST
 SG_ Saf_Bits m32 : 152|16@1+ (1,0) [0|0] "" HETC_M_WST
 SG_ Saf_Estop m32 : 168|8@1+ (1,0) [0|0] "" HETC_M_WST
 SG_ Saf_FatalLatched m32 : 176|16@1+ (1,0) [0|0] "" HETC_M_WST
 SG_ Saf_ErrCode m32 : 192|32@1+ (1,0) [0|0] "" HETC_M_WST

CM_ "FM26C D-CAN. CAN ID = type<<16 | sender<<8 | dest. Generated from friday-firmware-2.0 dev c0ace19f. Design values, not measured.";
CM_ BO_ 2163238143 "CLI diagnostics";
CM_ BO_ 2147640575 "EVENT_ERR_CLEAR fault-reset fan-out";
CM_ BO_ 2163240703 "CLI diagnostics";
CM_ BO_ 2147643135 "EVENT_ERR_CLEAR fault-reset fan-out";
CM_ BO_ 2163243263 "CLI diagnostics";
CM_ BO_ 2147645695 "EVENT_ERR_CLEAR fault-reset fan-out";
CM_ BO_ 2163245823 "CLI diagnostics";
CM_ BO_ 2147648255 "EVENT_ERR_CLEAR fault-reset fan-out";
CM_ BO_ 2163248383 "CLI diagnostics";
CM_ BO_ 2147650815 "EVENT_ERR_CLEAR fault-reset fan-out";
CM_ BO_ 2163250943 "CLI diagnostics";
CM_ BO_ 2147653375 "EVENT_ERR_CLEAR fault-reset fan-out";
CM_ BO_ 2163263999 "CLI diagnostics";
CM_ BO_ 2163264255 "CLI diagnostics";
CM_ BO_ 2163264511 "CLI diagnostics";
CM_ BO_ 2163264767 "CLI diagnostics";
CM_ BO_ 2163265023 "CLI diagnostics";
CM_ BO_ 2163265279 "CLI diagnostics";
CM_ BO_ 2163265535 "CLI diagnostics";
CM_ BO_ 2163303534 "diagnostic response";
CM_ BO_ 2163303544 "diagnostic response";
CM_ BO_ 2163303554 "diagnostic response";
CM_ BO_ 2163303564 "diagnostic response";
CM_ BO_ 2163303574 "diagnostic response";
CM_ BO_ 2163303625 "diagnostic response";
CM_ BO_ 2163303626 "diagnostic response";
CM_ BO_ 2163303627 "diagnostic response";
CM_ BO_ 2163303628 "diagnostic response";
CM_ BO_ 2163303629 "diagnostic response";
CM_ BO_ 2163303630 "diagnostic response";
CM_ BO_ 2163303631 "diagnostic response";
CM_ BO_ 2163306084 "diagnostic response";
CM_ BO_ 2163306104 "diagnostic response";
CM_ BO_ 2163306114 "diagnostic response";
CM_ BO_ 2163306124 "diagnostic response";
CM_ BO_ 2163306134 "diagnostic response";
CM_ BO_ 2163306185 "diagnostic response";
CM_ BO_ 2163306186 "diagnostic response";
CM_ BO_ 2163306187 "diagnostic response";
CM_ BO_ 2163306188 "diagnostic response";
CM_ BO_ 2163306189 "diagnostic response";
CM_ BO_ 2163306190 "diagnostic response";
CM_ BO_ 2163306191 "diagnostic response";
CM_ BO_ 2163308644 "diagnostic response";
CM_ BO_ 2163308654 "diagnostic response";
BA_DEF_ "DBName" STRING ;
BA_DEF_ "BusType" STRING ;
BA_DEF_ "Baudrate" INT 0 8000000;
BA_DEF_ "BaudRateCANFD" INT 0 16000000;
BA_DEF_ BO_ "GenMsgCycleTime" INT 0 65535;
BA_DEF_ BO_ "VFrameFormat" ENUM "StandardCAN","ExtendedCAN","reserved","reserved","reserved","reserved","reserved","reserved","reserved","reserved","reserved","reserved","reserved","reserved","StandardCAN_FD","ExtendedCAN_FD";
BA_DEF_ BO_ "CANFD_BRS" ENUM "0","1";
BA_DEF_ BO_ "SubCodeCycles" STRING ;
BA_DEF_ BO_ "SubCodeLengths" STRING ;
BA_DEF_DEF_ "DBName" "";
BA_DEF_DEF_ "BusType" "CAN FD";
BA_DEF_DEF_ "Baudrate" 1000000;
BA_DEF_DEF_ "BaudRateCANFD" 5000000;
BA_DEF_DEF_ "GenMsgCycleTime" 0;
BA_DEF_DEF_ "VFrameFormat" "ExtendedCAN_FD";
BA_DEF_DEF_ "CANFD_BRS" "1";
BA_DEF_DEF_ "SubCodeCycles" "";
BA_DEF_DEF_ "SubCodeLengths" "";
BA_ "DBName" "D_CAN";
BA_ "Baudrate" 125000;
BA_ "BaudRateCANFD" 1000000;
BA_ "SubCodeLengths" BO_ 2163238143 "2:1;6:1;7:1;8:1;9:7";
BA_ "SubCodeLengths" BO_ 2163240703 "2:1;6:1;7:1;8:1;9:7";
BA_ "SubCodeLengths" BO_ 2163243263 "2:1;6:1;7:1;8:1;9:7";
BA_ "SubCodeLengths" BO_ 2163245823 "2:1;6:1;7:1;8:1;9:7";
BA_ "SubCodeLengths" BO_ 2163248383 "2:1;6:1;7:1;8:1;9:7";
BA_ "SubCodeLengths" BO_ 2163250943 "2:1;6:1;7:1;8:1;9:7";
BA_ "SubCodeLengths" BO_ 2163263999 "2:1;6:1;7:1;8:1;9:7";
BA_ "SubCodeLengths" BO_ 2163264255 "2:1;6:1;7:1;8:1;9:7";
BA_ "SubCodeLengths" BO_ 2163264511 "2:1;6:1;7:1;8:1;9:7";
BA_ "SubCodeLengths" BO_ 2163264767 "2:1;6:1;7:1;8:1;9:7";
BA_ "SubCodeLengths" BO_ 2163265023 "2:1;6:1;7:1;8:1;9:7";
BA_ "SubCodeLengths" BO_ 2163265279 "2:1;6:1;7:1;8:1;9:7";
BA_ "SubCodeLengths" BO_ 2163265535 "2:1;6:1;7:1;8:1;9:7";
BA_ "SubCodeLengths" BO_ 2163303534 "5:37;31:37;32:28";
BA_ "SubCodeLengths" BO_ 2163303544 "5:37;31:37;32:28";
BA_ "SubCodeLengths" BO_ 2163303554 "5:37;31:37;32:28";
BA_ "SubCodeLengths" BO_ 2163303564 "5:37;31:37;32:28";
BA_ "SubCodeLengths" BO_ 2163303574 "5:37;31:37;32:28";
BA_ "SubCodeLengths" BO_ 2163303625 "5:37;31:37;32:28";
BA_ "SubCodeLengths" BO_ 2163303626 "5:37;31:37;32:28";
BA_ "SubCodeLengths" BO_ 2163303627 "5:37;31:37;32:28";
BA_ "SubCodeLengths" BO_ 2163303628 "5:37;31:37;32:28";
BA_ "SubCodeLengths" BO_ 2163303629 "5:37;31:37;32:28";
BA_ "SubCodeLengths" BO_ 2163303630 "5:37;31:37;32:28";
BA_ "SubCodeLengths" BO_ 2163303631 "5:37;31:37;32:28";
BA_ "SubCodeLengths" BO_ 2163306084 "5:37;31:37;32:28";
BA_ "SubCodeLengths" BO_ 2163306104 "5:37;31:37;32:28";
BA_ "SubCodeLengths" BO_ 2163306114 "5:37;31:37;32:28";
BA_ "SubCodeLengths" BO_ 2163306124 "5:37;31:37;32:28";
BA_ "SubCodeLengths" BO_ 2163306134 "5:37;31:37;32:28";
BA_ "SubCodeLengths" BO_ 2163306185 "5:37;31:37;32:28";
BA_ "SubCodeLengths" BO_ 2163306186 "5:37;31:37;32:28";
BA_ "SubCodeLengths" BO_ 2163306187 "5:37;31:37;32:28";
BA_ "SubCodeLengths" BO_ 2163306188 "5:37;31:37;32:28";
BA_ "SubCodeLengths" BO_ 2163306189 "5:37;31:37;32:28";
BA_ "SubCodeLengths" BO_ 2163306190 "5:37;31:37;32:28";
BA_ "SubCodeLengths" BO_ 2163306191 "5:37;31:37;32:28";
BA_ "SubCodeLengths" BO_ 2163308644 "5:37;31:37;32:28";
BA_ "SubCodeLengths" BO_ 2163308654 "5:37;31:37;32:28";
VAL_ 2163238143 SubCode 11 "POWER" 10 "THOR" 9 "RTC_SYNC" 8 "SAFETY_RESET" 7 "SAFETY_PING" 6 "ECAT_PING" 5 "BAT_LATCH" 4 "BUZZER" 3 "BRAKE" 2 "PING" 1 "MC_TARGET" 0 "MC_TORQUE" ;
VAL_ 2147640320 EvtCode 19 "CAN_ID_CHANGED" 18 "THOR_OFF" 17 "ROBOT_OFF" 16 "BLACKBOX_TRIG" 15 "BAT_WARN" 14 "ESTOP_UPDATE" 13 "ERR_CLEAR" 12 "ERR_CODE" 11 "WIZ_PHY_SNTP" 10 "WIZ_PHY_DHCP" 9 "WIZ_PHY_LINK" 8 "PAUSE" 7 "ECAT_CONNECT" 6 "ANGLE_EX_CONNECT" 5 "BRAKE_EX_CONNECT" 4 "BLDC_FAULT" 3 "BLDC_TORQUE" 2 "BLDC_LIMIT" 1 "ESTOP" 0 "OK" ;
VAL_ 2147640575 EvtCode 19 "CAN_ID_CHANGED" 18 "THOR_OFF" 17 "ROBOT_OFF" 16 "BLACKBOX_TRIG" 15 "BAT_WARN" 14 "ESTOP_UPDATE" 13 "ERR_CLEAR" 12 "ERR_CODE" 11 "WIZ_PHY_SNTP" 10 "WIZ_PHY_DHCP" 9 "WIZ_PHY_LINK" 8 "PAUSE" 7 "ECAT_CONNECT" 6 "ANGLE_EX_CONNECT" 5 "BRAKE_EX_CONNECT" 4 "BLDC_FAULT" 3 "BLDC_TORQUE" 2 "BLDC_LIMIT" 1 "ESTOP" 0 "OK" ;
VAL_ 2163240703 SubCode 11 "POWER" 10 "THOR" 9 "RTC_SYNC" 8 "SAFETY_RESET" 7 "SAFETY_PING" 6 "ECAT_PING" 5 "BAT_LATCH" 4 "BUZZER" 3 "BRAKE" 2 "PING" 1 "MC_TARGET" 0 "MC_TORQUE" ;
VAL_ 2147642880 EvtCode 19 "CAN_ID_CHANGED" 18 "THOR_OFF" 17 "ROBOT_OFF" 16 "BLACKBOX_TRIG" 15 "BAT_WARN" 14 "ESTOP_UPDATE" 13 "ERR_CLEAR" 12 "ERR_CODE" 11 "WIZ_PHY_SNTP" 10 "WIZ_PHY_DHCP" 9 "WIZ_PHY_LINK" 8 "PAUSE" 7 "ECAT_CONNECT" 6 "ANGLE_EX_CONNECT" 5 "BRAKE_EX_CONNECT" 4 "BLDC_FAULT" 3 "BLDC_TORQUE" 2 "BLDC_LIMIT" 1 "ESTOP" 0 "OK" ;
VAL_ 2147643135 EvtCode 19 "CAN_ID_CHANGED" 18 "THOR_OFF" 17 "ROBOT_OFF" 16 "BLACKBOX_TRIG" 15 "BAT_WARN" 14 "ESTOP_UPDATE" 13 "ERR_CLEAR" 12 "ERR_CODE" 11 "WIZ_PHY_SNTP" 10 "WIZ_PHY_DHCP" 9 "WIZ_PHY_LINK" 8 "PAUSE" 7 "ECAT_CONNECT" 6 "ANGLE_EX_CONNECT" 5 "BRAKE_EX_CONNECT" 4 "BLDC_FAULT" 3 "BLDC_TORQUE" 2 "BLDC_LIMIT" 1 "ESTOP" 0 "OK" ;
VAL_ 2163243263 SubCode 11 "POWER" 10 "THOR" 9 "RTC_SYNC" 8 "SAFETY_RESET" 7 "SAFETY_PING" 6 "ECAT_PING" 5 "BAT_LATCH" 4 "BUZZER" 3 "BRAKE" 2 "PING" 1 "MC_TARGET" 0 "MC_TORQUE" ;
VAL_ 2147645440 EvtCode 19 "CAN_ID_CHANGED" 18 "THOR_OFF" 17 "ROBOT_OFF" 16 "BLACKBOX_TRIG" 15 "BAT_WARN" 14 "ESTOP_UPDATE" 13 "ERR_CLEAR" 12 "ERR_CODE" 11 "WIZ_PHY_SNTP" 10 "WIZ_PHY_DHCP" 9 "WIZ_PHY_LINK" 8 "PAUSE" 7 "ECAT_CONNECT" 6 "ANGLE_EX_CONNECT" 5 "BRAKE_EX_CONNECT" 4 "BLDC_FAULT" 3 "BLDC_TORQUE" 2 "BLDC_LIMIT" 1 "ESTOP" 0 "OK" ;
VAL_ 2147645695 EvtCode 19 "CAN_ID_CHANGED" 18 "THOR_OFF" 17 "ROBOT_OFF" 16 "BLACKBOX_TRIG" 15 "BAT_WARN" 14 "ESTOP_UPDATE" 13 "ERR_CLEAR" 12 "ERR_CODE" 11 "WIZ_PHY_SNTP" 10 "WIZ_PHY_DHCP" 9 "WIZ_PHY_LINK" 8 "PAUSE" 7 "ECAT_CONNECT" 6 "ANGLE_EX_CONNECT" 5 "BRAKE_EX_CONNECT" 4 "BLDC_FAULT" 3 "BLDC_TORQUE" 2 "BLDC_LIMIT" 1 "ESTOP" 0 "OK" ;
VAL_ 2163245823 SubCode 11 "POWER" 10 "THOR" 9 "RTC_SYNC" 8 "SAFETY_RESET" 7 "SAFETY_PING" 6 "ECAT_PING" 5 "BAT_LATCH" 4 "BUZZER" 3 "BRAKE" 2 "PING" 1 "MC_TARGET" 0 "MC_TORQUE" ;
VAL_ 2147648000 EvtCode 19 "CAN_ID_CHANGED" 18 "THOR_OFF" 17 "ROBOT_OFF" 16 "BLACKBOX_TRIG" 15 "BAT_WARN" 14 "ESTOP_UPDATE" 13 "ERR_CLEAR" 12 "ERR_CODE" 11 "WIZ_PHY_SNTP" 10 "WIZ_PHY_DHCP" 9 "WIZ_PHY_LINK" 8 "PAUSE" 7 "ECAT_CONNECT" 6 "ANGLE_EX_CONNECT" 5 "BRAKE_EX_CONNECT" 4 "BLDC_FAULT" 3 "BLDC_TORQUE" 2 "BLDC_LIMIT" 1 "ESTOP" 0 "OK" ;
VAL_ 2147648255 EvtCode 19 "CAN_ID_CHANGED" 18 "THOR_OFF" 17 "ROBOT_OFF" 16 "BLACKBOX_TRIG" 15 "BAT_WARN" 14 "ESTOP_UPDATE" 13 "ERR_CLEAR" 12 "ERR_CODE" 11 "WIZ_PHY_SNTP" 10 "WIZ_PHY_DHCP" 9 "WIZ_PHY_LINK" 8 "PAUSE" 7 "ECAT_CONNECT" 6 "ANGLE_EX_CONNECT" 5 "BRAKE_EX_CONNECT" 4 "BLDC_FAULT" 3 "BLDC_TORQUE" 2 "BLDC_LIMIT" 1 "ESTOP" 0 "OK" ;
VAL_ 2163248383 SubCode 11 "POWER" 10 "THOR" 9 "RTC_SYNC" 8 "SAFETY_RESET" 7 "SAFETY_PING" 6 "ECAT_PING" 5 "BAT_LATCH" 4 "BUZZER" 3 "BRAKE" 2 "PING" 1 "MC_TARGET" 0 "MC_TORQUE" ;
VAL_ 2147650560 EvtCode 19 "CAN_ID_CHANGED" 18 "THOR_OFF" 17 "ROBOT_OFF" 16 "BLACKBOX_TRIG" 15 "BAT_WARN" 14 "ESTOP_UPDATE" 13 "ERR_CLEAR" 12 "ERR_CODE" 11 "WIZ_PHY_SNTP" 10 "WIZ_PHY_DHCP" 9 "WIZ_PHY_LINK" 8 "PAUSE" 7 "ECAT_CONNECT" 6 "ANGLE_EX_CONNECT" 5 "BRAKE_EX_CONNECT" 4 "BLDC_FAULT" 3 "BLDC_TORQUE" 2 "BLDC_LIMIT" 1 "ESTOP" 0 "OK" ;
VAL_ 2147650815 EvtCode 19 "CAN_ID_CHANGED" 18 "THOR_OFF" 17 "ROBOT_OFF" 16 "BLACKBOX_TRIG" 15 "BAT_WARN" 14 "ESTOP_UPDATE" 13 "ERR_CLEAR" 12 "ERR_CODE" 11 "WIZ_PHY_SNTP" 10 "WIZ_PHY_DHCP" 9 "WIZ_PHY_LINK" 8 "PAUSE" 7 "ECAT_CONNECT" 6 "ANGLE_EX_CONNECT" 5 "BRAKE_EX_CONNECT" 4 "BLDC_FAULT" 3 "BLDC_TORQUE" 2 "BLDC_LIMIT" 1 "ESTOP" 0 "OK" ;
VAL_ 2163250943 SubCode 11 "POWER" 10 "THOR" 9 "RTC_SYNC" 8 "SAFETY_RESET" 7 "SAFETY_PING" 6 "ECAT_PING" 5 "BAT_LATCH" 4 "BUZZER" 3 "BRAKE" 2 "PING" 1 "MC_TARGET" 0 "MC_TORQUE" ;
VAL_ 2147653120 EvtCode 19 "CAN_ID_CHANGED" 18 "THOR_OFF" 17 "ROBOT_OFF" 16 "BLACKBOX_TRIG" 15 "BAT_WARN" 14 "ESTOP_UPDATE" 13 "ERR_CLEAR" 12 "ERR_CODE" 11 "WIZ_PHY_SNTP" 10 "WIZ_PHY_DHCP" 9 "WIZ_PHY_LINK" 8 "PAUSE" 7 "ECAT_CONNECT" 6 "ANGLE_EX_CONNECT" 5 "BRAKE_EX_CONNECT" 4 "BLDC_FAULT" 3 "BLDC_TORQUE" 2 "BLDC_LIMIT" 1 "ESTOP" 0 "OK" ;
VAL_ 2147653375 EvtCode 19 "CAN_ID_CHANGED" 18 "THOR_OFF" 17 "ROBOT_OFF" 16 "BLACKBOX_TRIG" 15 "BAT_WARN" 14 "ESTOP_UPDATE" 13 "ERR_CLEAR" 12 "ERR_CODE" 11 "WIZ_PHY_SNTP" 10 "WIZ_PHY_DHCP" 9 "WIZ_PHY_LINK" 8 "PAUSE" 7 "ECAT_CONNECT" 6 "ANGLE_EX_CONNECT" 5 "BRAKE_EX_CONNECT" 4 "BLDC_FAULT" 3 "BLDC_TORQUE" 2 "BLDC_LIMIT" 1 "ESTOP" 0 "OK" ;
VAL_ 2163263999 SubCode 11 "POWER" 10 "THOR" 9 "RTC_SYNC" 8 "SAFETY_RESET" 7 "SAFETY_PING" 6 "ECAT_PING" 5 "BAT_LATCH" 4 "BUZZER" 3 "BRAKE" 2 "PING" 1 "MC_TARGET" 0 "MC_TORQUE" ;
VAL_ 2147666176 EvtCode 19 "CAN_ID_CHANGED" 18 "THOR_OFF" 17 "ROBOT_OFF" 16 "BLACKBOX_TRIG" 15 "BAT_WARN" 14 "ESTOP_UPDATE" 13 "ERR_CLEAR" 12 "ERR_CODE" 11 "WIZ_PHY_SNTP" 10 "WIZ_PHY_DHCP" 9 "WIZ_PHY_LINK" 8 "PAUSE" 7 "ECAT_CONNECT" 6 "ANGLE_EX_CONNECT" 5 "BRAKE_EX_CONNECT" 4 "BLDC_FAULT" 3 "BLDC_TORQUE" 2 "BLDC_LIMIT" 1 "ESTOP" 0 "OK" ;
VAL_ 2163264255 SubCode 11 "POWER" 10 "THOR" 9 "RTC_SYNC" 8 "SAFETY_RESET" 7 "SAFETY_PING" 6 "ECAT_PING" 5 "BAT_LATCH" 4 "BUZZER" 3 "BRAKE" 2 "PING" 1 "MC_TARGET" 0 "MC_TORQUE" ;
VAL_ 2147666432 EvtCode 19 "CAN_ID_CHANGED" 18 "THOR_OFF" 17 "ROBOT_OFF" 16 "BLACKBOX_TRIG" 15 "BAT_WARN" 14 "ESTOP_UPDATE" 13 "ERR_CLEAR" 12 "ERR_CODE" 11 "WIZ_PHY_SNTP" 10 "WIZ_PHY_DHCP" 9 "WIZ_PHY_LINK" 8 "PAUSE" 7 "ECAT_CONNECT" 6 "ANGLE_EX_CONNECT" 5 "BRAKE_EX_CONNECT" 4 "BLDC_FAULT" 3 "BLDC_TORQUE" 2 "BLDC_LIMIT" 1 "ESTOP" 0 "OK" ;
VAL_ 2163264511 SubCode 11 "POWER" 10 "THOR" 9 "RTC_SYNC" 8 "SAFETY_RESET" 7 "SAFETY_PING" 6 "ECAT_PING" 5 "BAT_LATCH" 4 "BUZZER" 3 "BRAKE" 2 "PING" 1 "MC_TARGET" 0 "MC_TORQUE" ;
VAL_ 2147666688 EvtCode 19 "CAN_ID_CHANGED" 18 "THOR_OFF" 17 "ROBOT_OFF" 16 "BLACKBOX_TRIG" 15 "BAT_WARN" 14 "ESTOP_UPDATE" 13 "ERR_CLEAR" 12 "ERR_CODE" 11 "WIZ_PHY_SNTP" 10 "WIZ_PHY_DHCP" 9 "WIZ_PHY_LINK" 8 "PAUSE" 7 "ECAT_CONNECT" 6 "ANGLE_EX_CONNECT" 5 "BRAKE_EX_CONNECT" 4 "BLDC_FAULT" 3 "BLDC_TORQUE" 2 "BLDC_LIMIT" 1 "ESTOP" 0 "OK" ;
VAL_ 2163264767 SubCode 11 "POWER" 10 "THOR" 9 "RTC_SYNC" 8 "SAFETY_RESET" 7 "SAFETY_PING" 6 "ECAT_PING" 5 "BAT_LATCH" 4 "BUZZER" 3 "BRAKE" 2 "PING" 1 "MC_TARGET" 0 "MC_TORQUE" ;
VAL_ 2147666944 EvtCode 19 "CAN_ID_CHANGED" 18 "THOR_OFF" 17 "ROBOT_OFF" 16 "BLACKBOX_TRIG" 15 "BAT_WARN" 14 "ESTOP_UPDATE" 13 "ERR_CLEAR" 12 "ERR_CODE" 11 "WIZ_PHY_SNTP" 10 "WIZ_PHY_DHCP" 9 "WIZ_PHY_LINK" 8 "PAUSE" 7 "ECAT_CONNECT" 6 "ANGLE_EX_CONNECT" 5 "BRAKE_EX_CONNECT" 4 "BLDC_FAULT" 3 "BLDC_TORQUE" 2 "BLDC_LIMIT" 1 "ESTOP" 0 "OK" ;
VAL_ 2163265023 SubCode 11 "POWER" 10 "THOR" 9 "RTC_SYNC" 8 "SAFETY_RESET" 7 "SAFETY_PING" 6 "ECAT_PING" 5 "BAT_LATCH" 4 "BUZZER" 3 "BRAKE" 2 "PING" 1 "MC_TARGET" 0 "MC_TORQUE" ;
VAL_ 2147667200 EvtCode 19 "CAN_ID_CHANGED" 18 "THOR_OFF" 17 "ROBOT_OFF" 16 "BLACKBOX_TRIG" 15 "BAT_WARN" 14 "ESTOP_UPDATE" 13 "ERR_CLEAR" 12 "ERR_CODE" 11 "WIZ_PHY_SNTP" 10 "WIZ_PHY_DHCP" 9 "WIZ_PHY_LINK" 8 "PAUSE" 7 "ECAT_CONNECT" 6 "ANGLE_EX_CONNECT" 5 "BRAKE_EX_CONNECT" 4 "BLDC_FAULT" 3 "BLDC_TORQUE" 2 "BLDC_LIMIT" 1 "ESTOP" 0 "OK" ;
VAL_ 2163265279 SubCode 11 "POWER" 10 "THOR" 9 "RTC_SYNC" 8 "SAFETY_RESET" 7 "SAFETY_PING" 6 "ECAT_PING" 5 "BAT_LATCH" 4 "BUZZER" 3 "BRAKE" 2 "PING" 1 "MC_TARGET" 0 "MC_TORQUE" ;
VAL_ 2147667456 EvtCode 19 "CAN_ID_CHANGED" 18 "THOR_OFF" 17 "ROBOT_OFF" 16 "BLACKBOX_TRIG" 15 "BAT_WARN" 14 "ESTOP_UPDATE" 13 "ERR_CLEAR" 12 "ERR_CODE" 11 "WIZ_PHY_SNTP" 10 "WIZ_PHY_DHCP" 9 "WIZ_PHY_LINK" 8 "PAUSE" 7 "ECAT_CONNECT" 6 "ANGLE_EX_CONNECT" 5 "BRAKE_EX_CONNECT" 4 "BLDC_FAULT" 3 "BLDC_TORQUE" 2 "BLDC_LIMIT" 1 "ESTOP" 0 "OK" ;
VAL_ 2163265535 SubCode 11 "POWER" 10 "THOR" 9 "RTC_SYNC" 8 "SAFETY_RESET" 7 "SAFETY_PING" 6 "ECAT_PING" 5 "BAT_LATCH" 4 "BUZZER" 3 "BRAKE" 2 "PING" 1 "MC_TARGET" 0 "MC_TORQUE" ;
VAL_ 2147667712 EvtCode 19 "CAN_ID_CHANGED" 18 "THOR_OFF" 17 "ROBOT_OFF" 16 "BLACKBOX_TRIG" 15 "BAT_WARN" 14 "ESTOP_UPDATE" 13 "ERR_CLEAR" 12 "ERR_CODE" 11 "WIZ_PHY_SNTP" 10 "WIZ_PHY_DHCP" 9 "WIZ_PHY_LINK" 8 "PAUSE" 7 "ECAT_CONNECT" 6 "ANGLE_EX_CONNECT" 5 "BRAKE_EX_CONNECT" 4 "BLDC_FAULT" 3 "BLDC_TORQUE" 2 "BLDC_LIMIT" 1 "ESTOP" 0 "OK" ;
VAL_ 2163303534 SubCode 34 "POWER" 33 "THOR" 32 "SAFETY" 31 "ECAT_ERR" 30 "BUZZER_CFG" 27 "ANGLE_MULTI" 26 "BAT_LATCH" 25 "SAFETY_SENSOR" 22 "HRMC" 19 "TOF" 18 "USS" 17 "ANGLE" 9 "TACTILE_G2" 5 "PING" ;
VAL_ 2163303534 Saf_State 4 "RESETTING" 3 "FAULT" 2 "STOPPED" 1 "STOPPING" 0 "NORMAL" ;
VAL_ 2163303544 SubCode 34 "POWER" 33 "THOR" 32 "SAFETY" 31 "ECAT_ERR" 30 "BUZZER_CFG" 27 "ANGLE_MULTI" 26 "BAT_LATCH" 25 "SAFETY_SENSOR" 22 "HRMC" 19 "TOF" 18 "USS" 17 "ANGLE" 9 "TACTILE_G2" 5 "PING" ;
VAL_ 2163303544 Saf_State 4 "RESETTING" 3 "FAULT" 2 "STOPPED" 1 "STOPPING" 0 "NORMAL" ;
VAL_ 2163303554 SubCode 34 "POWER" 33 "THOR" 32 "SAFETY" 31 "ECAT_ERR" 30 "BUZZER_CFG" 27 "ANGLE_MULTI" 26 "BAT_LATCH" 25 "SAFETY_SENSOR" 22 "HRMC" 19 "TOF" 18 "USS" 17 "ANGLE" 9 "TACTILE_G2" 5 "PING" ;
VAL_ 2163303554 Saf_State 4 "RESETTING" 3 "FAULT" 2 "STOPPED" 1 "STOPPING" 0 "NORMAL" ;
VAL_ 2163303564 SubCode 34 "POWER" 33 "THOR" 32 "SAFETY" 31 "ECAT_ERR" 30 "BUZZER_CFG" 27 "ANGLE_MULTI" 26 "BAT_LATCH" 25 "SAFETY_SENSOR" 22 "HRMC" 19 "TOF" 18 "USS" 17 "ANGLE" 9 "TACTILE_G2" 5 "PING" ;
VAL_ 2163303564 Saf_State 4 "RESETTING" 3 "FAULT" 2 "STOPPED" 1 "STOPPING" 0 "NORMAL" ;
VAL_ 2163303574 SubCode 34 "POWER" 33 "THOR" 32 "SAFETY" 31 "ECAT_ERR" 30 "BUZZER_CFG" 27 "ANGLE_MULTI" 26 "BAT_LATCH" 25 "SAFETY_SENSOR" 22 "HRMC" 19 "TOF" 18 "USS" 17 "ANGLE" 9 "TACTILE_G2" 5 "PING" ;
VAL_ 2163303574 Saf_State 4 "RESETTING" 3 "FAULT" 2 "STOPPED" 1 "STOPPING" 0 "NORMAL" ;
VAL_ 2163303625 SubCode 34 "POWER" 33 "THOR" 32 "SAFETY" 31 "ECAT_ERR" 30 "BUZZER_CFG" 27 "ANGLE_MULTI" 26 "BAT_LATCH" 25 "SAFETY_SENSOR" 22 "HRMC" 19 "TOF" 18 "USS" 17 "ANGLE" 9 "TACTILE_G2" 5 "PING" ;
VAL_ 2163303625 Saf_State 4 "RESETTING" 3 "FAULT" 2 "STOPPED" 1 "STOPPING" 0 "NORMAL" ;
VAL_ 2163303626 SubCode 34 "POWER" 33 "THOR" 32 "SAFETY" 31 "ECAT_ERR" 30 "BUZZER_CFG" 27 "ANGLE_MULTI" 26 "BAT_LATCH" 25 "SAFETY_SENSOR" 22 "HRMC" 19 "TOF" 18 "USS" 17 "ANGLE" 9 "TACTILE_G2" 5 "PING" ;
VAL_ 2163303626 Saf_State 4 "RESETTING" 3 "FAULT" 2 "STOPPED" 1 "STOPPING" 0 "NORMAL" ;
VAL_ 2163303627 SubCode 34 "POWER" 33 "THOR" 32 "SAFETY" 31 "ECAT_ERR" 30 "BUZZER_CFG" 27 "ANGLE_MULTI" 26 "BAT_LATCH" 25 "SAFETY_SENSOR" 22 "HRMC" 19 "TOF" 18 "USS" 17 "ANGLE" 9 "TACTILE_G2" 5 "PING" ;
VAL_ 2163303627 Saf_State 4 "RESETTING" 3 "FAULT" 2 "STOPPED" 1 "STOPPING" 0 "NORMAL" ;
VAL_ 2163303628 SubCode 34 "POWER" 33 "THOR" 32 "SAFETY" 31 "ECAT_ERR" 30 "BUZZER_CFG" 27 "ANGLE_MULTI" 26 "BAT_LATCH" 25 "SAFETY_SENSOR" 22 "HRMC" 19 "TOF" 18 "USS" 17 "ANGLE" 9 "TACTILE_G2" 5 "PING" ;
VAL_ 2163303628 Saf_State 4 "RESETTING" 3 "FAULT" 2 "STOPPED" 1 "STOPPING" 0 "NORMAL" ;
VAL_ 2163303629 SubCode 34 "POWER" 33 "THOR" 32 "SAFETY" 31 "ECAT_ERR" 30 "BUZZER_CFG" 27 "ANGLE_MULTI" 26 "BAT_LATCH" 25 "SAFETY_SENSOR" 22 "HRMC" 19 "TOF" 18 "USS" 17 "ANGLE" 9 "TACTILE_G2" 5 "PING" ;
VAL_ 2163303629 Saf_State 4 "RESETTING" 3 "FAULT" 2 "STOPPED" 1 "STOPPING" 0 "NORMAL" ;
VAL_ 2163303630 SubCode 34 "POWER" 33 "THOR" 32 "SAFETY" 31 "ECAT_ERR" 30 "BUZZER_CFG" 27 "ANGLE_MULTI" 26 "BAT_LATCH" 25 "SAFETY_SENSOR" 22 "HRMC" 19 "TOF" 18 "USS" 17 "ANGLE" 9 "TACTILE_G2" 5 "PING" ;
VAL_ 2163303630 Saf_State 4 "RESETTING" 3 "FAULT" 2 "STOPPED" 1 "STOPPING" 0 "NORMAL" ;
VAL_ 2163303631 SubCode 34 "POWER" 33 "THOR" 32 "SAFETY" 31 "ECAT_ERR" 30 "BUZZER_CFG" 27 "ANGLE_MULTI" 26 "BAT_LATCH" 25 "SAFETY_SENSOR" 22 "HRMC" 19 "TOF" 18 "USS" 17 "ANGLE" 9 "TACTILE_G2" 5 "PING" ;
VAL_ 2163303631 Saf_State 4 "RESETTING" 3 "FAULT" 2 "STOPPED" 1 "STOPPING" 0 "NORMAL" ;
VAL_ 2163306084 SubCode 34 "POWER" 33 "THOR" 32 "SAFETY" 31 "ECAT_ERR" 30 "BUZZER_CFG" 27 "ANGLE_MULTI" 26 "BAT_LATCH" 25 "SAFETY_SENSOR" 22 "HRMC" 19 "TOF" 18 "USS" 17 "ANGLE" 9 "TACTILE_G2" 5 "PING" ;
VAL_ 2163306084 Saf_State 4 "RESETTING" 3 "FAULT" 2 "STOPPED" 1 "STOPPING" 0 "NORMAL" ;
VAL_ 2163306104 SubCode 34 "POWER" 33 "THOR" 32 "SAFETY" 31 "ECAT_ERR" 30 "BUZZER_CFG" 27 "ANGLE_MULTI" 26 "BAT_LATCH" 25 "SAFETY_SENSOR" 22 "HRMC" 19 "TOF" 18 "USS" 17 "ANGLE" 9 "TACTILE_G2" 5 "PING" ;
VAL_ 2163306104 Saf_State 4 "RESETTING" 3 "FAULT" 2 "STOPPED" 1 "STOPPING" 0 "NORMAL" ;
VAL_ 2163306114 SubCode 34 "POWER" 33 "THOR" 32 "SAFETY" 31 "ECAT_ERR" 30 "BUZZER_CFG" 27 "ANGLE_MULTI" 26 "BAT_LATCH" 25 "SAFETY_SENSOR" 22 "HRMC" 19 "TOF" 18 "USS" 17 "ANGLE" 9 "TACTILE_G2" 5 "PING" ;
VAL_ 2163306114 Saf_State 4 "RESETTING" 3 "FAULT" 2 "STOPPED" 1 "STOPPING" 0 "NORMAL" ;
VAL_ 2163306124 SubCode 34 "POWER" 33 "THOR" 32 "SAFETY" 31 "ECAT_ERR" 30 "BUZZER_CFG" 27 "ANGLE_MULTI" 26 "BAT_LATCH" 25 "SAFETY_SENSOR" 22 "HRMC" 19 "TOF" 18 "USS" 17 "ANGLE" 9 "TACTILE_G2" 5 "PING" ;
VAL_ 2163306124 Saf_State 4 "RESETTING" 3 "FAULT" 2 "STOPPED" 1 "STOPPING" 0 "NORMAL" ;
VAL_ 2163306134 SubCode 34 "POWER" 33 "THOR" 32 "SAFETY" 31 "ECAT_ERR" 30 "BUZZER_CFG" 27 "ANGLE_MULTI" 26 "BAT_LATCH" 25 "SAFETY_SENSOR" 22 "HRMC" 19 "TOF" 18 "USS" 17 "ANGLE" 9 "TACTILE_G2" 5 "PING" ;
VAL_ 2163306134 Saf_State 4 "RESETTING" 3 "FAULT" 2 "STOPPED" 1 "STOPPING" 0 "NORMAL" ;
VAL_ 2163306185 SubCode 34 "POWER" 33 "THOR" 32 "SAFETY" 31 "ECAT_ERR" 30 "BUZZER_CFG" 27 "ANGLE_MULTI" 26 "BAT_LATCH" 25 "SAFETY_SENSOR" 22 "HRMC" 19 "TOF" 18 "USS" 17 "ANGLE" 9 "TACTILE_G2" 5 "PING" ;
VAL_ 2163306185 Saf_State 4 "RESETTING" 3 "FAULT" 2 "STOPPED" 1 "STOPPING" 0 "NORMAL" ;
VAL_ 2163306186 SubCode 34 "POWER" 33 "THOR" 32 "SAFETY" 31 "ECAT_ERR" 30 "BUZZER_CFG" 27 "ANGLE_MULTI" 26 "BAT_LATCH" 25 "SAFETY_SENSOR" 22 "HRMC" 19 "TOF" 18 "USS" 17 "ANGLE" 9 "TACTILE_G2" 5 "PING" ;
VAL_ 2163306186 Saf_State 4 "RESETTING" 3 "FAULT" 2 "STOPPED" 1 "STOPPING" 0 "NORMAL" ;
VAL_ 2163306187 SubCode 34 "POWER" 33 "THOR" 32 "SAFETY" 31 "ECAT_ERR" 30 "BUZZER_CFG" 27 "ANGLE_MULTI" 26 "BAT_LATCH" 25 "SAFETY_SENSOR" 22 "HRMC" 19 "TOF" 18 "USS" 17 "ANGLE" 9 "TACTILE_G2" 5 "PING" ;
VAL_ 2163306187 Saf_State 4 "RESETTING" 3 "FAULT" 2 "STOPPED" 1 "STOPPING" 0 "NORMAL" ;
VAL_ 2163306188 SubCode 34 "POWER" 33 "THOR" 32 "SAFETY" 31 "ECAT_ERR" 30 "BUZZER_CFG" 27 "ANGLE_MULTI" 26 "BAT_LATCH" 25 "SAFETY_SENSOR" 22 "HRMC" 19 "TOF" 18 "USS" 17 "ANGLE" 9 "TACTILE_G2" 5 "PING" ;
VAL_ 2163306188 Saf_State 4 "RESETTING" 3 "FAULT" 2 "STOPPED" 1 "STOPPING" 0 "NORMAL" ;
VAL_ 2163306189 SubCode 34 "POWER" 33 "THOR" 32 "SAFETY" 31 "ECAT_ERR" 30 "BUZZER_CFG" 27 "ANGLE_MULTI" 26 "BAT_LATCH" 25 "SAFETY_SENSOR" 22 "HRMC" 19 "TOF" 18 "USS" 17 "ANGLE" 9 "TACTILE_G2" 5 "PING" ;
VAL_ 2163306189 Saf_State 4 "RESETTING" 3 "FAULT" 2 "STOPPED" 1 "STOPPING" 0 "NORMAL" ;
VAL_ 2163306190 SubCode 34 "POWER" 33 "THOR" 32 "SAFETY" 31 "ECAT_ERR" 30 "BUZZER_CFG" 27 "ANGLE_MULTI" 26 "BAT_LATCH" 25 "SAFETY_SENSOR" 22 "HRMC" 19 "TOF" 18 "USS" 17 "ANGLE" 9 "TACTILE_G2" 5 "PING" ;
VAL_ 2163306190 Saf_State 4 "RESETTING" 3 "FAULT" 2 "STOPPED" 1 "STOPPING" 0 "NORMAL" ;
VAL_ 2163306191 SubCode 34 "POWER" 33 "THOR" 32 "SAFETY" 31 "ECAT_ERR" 30 "BUZZER_CFG" 27 "ANGLE_MULTI" 26 "BAT_LATCH" 25 "SAFETY_SENSOR" 22 "HRMC" 19 "TOF" 18 "USS" 17 "ANGLE" 9 "TACTILE_G2" 5 "PING" ;
VAL_ 2163306191 Saf_State 4 "RESETTING" 3 "FAULT" 2 "STOPPED" 1 "STOPPING" 0 "NORMAL" ;
VAL_ 2163308644 SubCode 34 "POWER" 33 "THOR" 32 "SAFETY" 31 "ECAT_ERR" 30 "BUZZER_CFG" 27 "ANGLE_MULTI" 26 "BAT_LATCH" 25 "SAFETY_SENSOR" 22 "HRMC" 19 "TOF" 18 "USS" 17 "ANGLE" 9 "TACTILE_G2" 5 "PING" ;
VAL_ 2163308644 Saf_State 4 "RESETTING" 3 "FAULT" 2 "STOPPED" 1 "STOPPING" 0 "NORMAL" ;
VAL_ 2163308654 SubCode 34 "POWER" 33 "THOR" 32 "SAFETY" 31 "ECAT_ERR" 30 "BUZZER_CFG" 27 "ANGLE_MULTI" 26 "BAT_LATCH" 25 "SAFETY_SENSOR" 22 "HRMC" 19 "TOF" 18 "USS" 17 "ANGLE" 9 "TACTILE_G2" 5 "PING" ;
VAL_ 2163308654 Saf_State 4 "RESETTING" 3 "FAULT" 2 "STOPPED" 1 "STOPPING" 0 "NORMAL" ;
